[part 1 of 2: packages /Systems to /BMW/Boardnet/Clusters/CommunicationClusters]
AUTOSAR XML (schema 4-3-0)
package /Systems
  system EPS: category=ECU_SYSTEM_DESCRIPTION, pnc-vector-length=6, pnc-vector-offset=2, system-version=0.0.1
package /Systems/EndToEndProtections
  end to end protection set EndToEndProtectionSet
    18 x end to end protection:
      endToEndProt_ACLNY_MASSCNTR: end-to-end-profile={category=PROFILE_01, data-ids=31, data-id-mode=0, data-length=48, max-delta-counter-init=14, crc-offset=0, counter-offset=8}, end-to-end-protection-i-signal-i-pdu{data-offset=0, i-signal-group=sigGroup_ACLNY_MASSCNTR, i-signal-i-pdu=ACLNY_MASSCNTR}
      endToEndProt_AVL_FORC_GRD: end-to-end-profile={category=PROFILE_01, data-ids=190, data-id-mode=0, data-length=40, max-delta-counter-init=14, crc-offset=0, counter-offset=8}, end-to-end-protection-i-signal-i-pdu{data-offset=0, i-signal-group=sigGroup_AVL_FORC_GRD, i-signal-i-pdu=AVL_FORC_GRD}
      endToEndProt_AVL_PO_EPS: end-to-end-profile={category=PROFILE_01, data-ids=186, data-id-mode=0, data-length=64, max-delta-counter-init=14, crc-offset=0, counter-offset=8}, end-to-end-protection-i-signal-i-pdu{data-offset=0, i-signal-group=sigGroup_AVL_PO_EPS, i-signal-i-pdu=AVL_PO_EPS}
      endToEndProt_AVL_RPM_WHL: end-to-end-profile={category=PROFILE_01, data-ids=17, data-id-mode=0, data-length=96, max-delta-counter-init=14, crc-offset=0, counter-offset=8}, end-to-end-protection-i-signal-i-pdu{data-offset=0, i-signal-group=sigGroup_AVL_RPM_WHL, i-signal-i-pdu=AVL_RPM_WHL}
      endToEndProt_AVL_STMOM_DV_ACT: end-to-end-profile={category=PROFILE_01, data-ids=108, data-id-mode=0, data-length=32, max-delta-counter-init=14, crc-offset=0, counter-offset=8}, end-to-end-protection-i-signal-i-pdu{data-offset=0, i-signal-group=sigGroup_AVL_STMOM_DV_ACT, i-signal-i-pdu=AVL_STMOM_DV_ACT}
      endToEndProt_CON_VEH: end-to-end-profile={category=PROFILE_01, data-ids=197, data-id-mode=0, data-length=64, max-delta-counter-init=14, crc-offset=0, counter-offset=8}, end-to-end-protection-i-signal-i-pdu{data-offset=0, i-signal-group=sigGroup_CON_VEH, i-signal-i-pdu=CON_VEH}
      endToEndProt_DISP_CC_EPS: end-to-end-profile={category=PROFILE_01, data-ids=3148, data-id-mode=3, data-length=40, max-delta-counter-init=14, crc-offset=0, counter-offset=8, data-id-nibble-offset=12}, end-to-end-protection-i-signal-i-pdu{data-offset=0, i-signal-group=sigGroup_DISP_CC_EPS, i-signal-i-pdu=DISP_CC_EPS}
      endToEndProt_DT_EST: end-to-end-profile={category=PROFILE_01, data-ids=230, data-id-mode=0, data-length=128, max-delta-counter-init=14, crc-offset=0, counter-offset=8}, end-to-end-protection-i-signal-i-pdu{data-offset=0, i-signal-group=sigGroup_DT_EST, i-signal-i-pdu=DT_EST}
      endToEndProt_ENERG_DGR_DRDY: end-to-end-profile={category=PROFILE_01, data-ids=56, data-id-mode=0, data-length=64, max-delta-counter-init=14, crc-offset=56, counter-offset=52}, end-to-end-protection-i-signal-i-pdu{data-offset=0, i-signal-group=sigGroup_ENERG_DGR_DRDY, i-signal-i-pdu=ENERG_DGR_DRDY}
      endToEndProt_ENSU_SFY: end-to-end-profile={category=PROFILE_01, data-ids=628, data-id-mode=3, data-length=64, max-delta-counter-init=14, crc-offset=0, counter-offset=8, data-id-nibble-offset=12}, end-to-end-protection-i-signal-i-pdu{data-offset=0, i-signal-group=sigGroup_ENSU_SFY, i-signal-i-pdu=ENSU_SFY}
      endToEndProt_OFFS_QUAD_EPS: end-to-end-profile={category=PROFILE_01, data-ids=229, data-id-mode=0, data-length=40, max-delta-counter-init=14, crc-offset=0, counter-offset=8}, end-to-end-protection-i-signal-i-pdu{data-offset=0, i-signal-group=sigGroup_OFFS_QUAD_EPS, i-signal-i-pdu=OFFS_QUAD_EPS}
      endToEndProt_ST_EST: end-to-end-profile={category=PROFILE_01, data-ids=112, data-id-mode=0, data-length=40, max-delta-counter-init=14, crc-offset=0, counter-offset=8}, end-to-end-protection-i-signal-i-pdu{data-offset=0, i-signal-group=sigGroup_ST_EST, i-signal-i-pdu=ST_EST}
      endToEndProt_SU_EPS: end-to-end-profile={category=PROFILE_01, data-ids=131, data-id-mode=0, data-length=64, max-delta-counter-init=14, crc-offset=56, counter-offset=52}, end-to-end-protection-i-signal-i-pdu{data-offset=0, i-signal-group=sigGroup_SU_EPS, i-signal-i-pdu=SU_EPS}
      endToEndProt_TAR_ESTP_VIRT_FTAX: end-to-end-profile={category=PROFILE_01, data-ids=52, data-id-mode=0, data-length=64, max-delta-counter-init=14, crc-offset=0, counter-offset=8}, end-to-end-protection-i-signal-i-pdu{data-offset=0, i-signal-group=sigGroup_TAR_ESTP_VIRT_FTAX, i-signal-i-pdu=TAR_ESTP_VIRT_FTAX}
      endToEndProt_TAR_QTA_STRMOM_DV: end-to-end-profile={category=PROFILE_01, data-ids=109, data-id-mode=0, data-length=64, max-delta-counter-init=14, crc-offset=0, counter-offset=8}, end-to-end-protection-i-signal-i-pdu{data-offset=0, i-signal-group=sigGroup_TAR_QTA_STRMOM_DV, i-signal-i-pdu=TAR_QTA_STRMOM_DV}
      endToEndProt_TAR_STMOM_DV_ACT: end-to-end-profile={category=PROFILE_01, data-ids=179, data-id-mode=0, data-length=64, max-delta-counter-init=14, crc-offset=0, counter-offset=8}, end-to-end-protection-i-signal-i-pdu{data-offset=0, i-signal-group=sigGroup_TAR_STMOM_DV_ACT, i-signal-i-pdu=TAR_STMOM_DV_ACT}
      endToEndProt_VYAW_VEH: end-to-end-profile={category=PROFILE_01, data-ids=14, data-id-mode=0, data-length=48, max-delta-counter-init=14, crc-offset=0, counter-offset=8}, end-to-end-protection-i-signal-i-pdu{data-offset=0, i-signal-group=sigGroup_VYAW_VEH, i-signal-i-pdu=VYAW_VEH}
      endToEndProt_V_VEH: end-to-end-profile={category=PROFILE_01, data-ids=12, data-id-mode=0, data-length=40, max-delta-counter-init=14, crc-offset=0, counter-offset=8}, end-to-end-protection-i-signal-i-pdu{data-offset=0, i-signal-group=sigGroup_V_VEH, i-signal-i-pdu=V_VEH}
package /BMW/Boardnet/Clusters/CommunicationClusters
  flexray cluster A_FlexRay:
    baudrate=10000000
    protocol-name=FlexRay
    action-point-offset=2
    bit=1E-7
    cas-rx-low-max=79
    cold-start-attempts=8
    cycle=0.005
    cycle-count-max=63
    detect-nit-error=false
    dynamic-slot-idle-phase=1
    ignore-after-tx=0
    listen-noise=2
    macro-per-cycle=3636
    macrotick-duration=0.000001375
    max-without-clock-correction-fatal=2
    max-without-clock-correction-passive=2
    minislot-action-point-offset=2
    minislot-duration=5
    network-idle-time=7
    network-management-vector-length=0
    number-of-minislots=289
    number-of-static-slots=91
    offset-correction-start=3632
    payload-length-static=8
    safety-margin=100
    sample-clock-period=1.25E-8
    static-slot-duration=24
    symbol-window=0
    symbol-window-action-point-offset=2
    sync-frame-id-count-max=15
    transmission-start-sequence-duration=9
    wakeup-rx-idle=59
    wakeup-rx-low=50
    wakeup-rx-window=301
    wakeup-tx-active=60
    wakeup-tx-idle=180
    flexray physical channel A_FlexRay: comm-connectors=con_EPS_FibexID_0b7e5e09c061465d913e8968ece3cded, channel-name=CHANNEL-A  # A-FlexRay
      frame xcpstatic: from EPS, category=XCP_RUNTIME_CONFIGURED, frame-length=16, flexray-absolutely-scheduled-timing{communication-cycle=cycle-repetition={base-cycle=0, cycle-repetition=CYCLE-REPETITION-1}, slot-id=10}, allow-dynamic-l-sdu-length=false, payload-preamble-indicator=false  # XCP Bereich Statisch / XCP Frame Static | Dieser Frame dient als Platzhalter für die XCP-Konfiguration für FlexRay (s. LH FlexRay) und zur Pufferkonfiguration der FlexRay-Controller. Der statische XCP-Bereich wird auch durch das Projekt "Funktionstrace" mitbenutzt. Ansprechpartner ist Florian Kuttig oder Christian Pigorsch. / Dummyframe für Infrastruktur XCP
        general purpose i pdu dummy16bstatic: category=XCP, length=16  # Dummy-PDU 16 Byte static | Dummy-PDU ohne inhaltliche Verbindlichkeit mit 16 Byte für Infrastruktur (z.B. XCP).
      frame ERRM_BN_U: to EPS, category=APPLICATION, frame-length=2, flexray-absolutely-scheduled-timing{communication-cycle=cycle-repetition={base-cycle=0, cycle-repetition=CYCLE-REPETITION-1}, slot-id=104}, allow-dynamic-l-sdu-length=false, payload-preamble-indicator=false  # Fehlerspeicher Bordnetz Spannung
        pdu ERRM_BN_U: length=2, minimum-delay=0.01, transmission-mode-true-timing={cyclic-timing=time-period={tolerance=absolute-tolerance=1, value=5}, event-controlled-timing={number-of-repetitions=0, "Die Nachricht wird bei einer beliebigen Änderung des Signals "Steuerung Fehlerspeicher Bordnetzspannung" ereignisgesteuert versendet."}}, unused-bit-pattern=255  # Fehlerspeicher Bordnetz Spannung | Diese Botschaft beinhaltet das Signal Steuerung Fehlerspeicher Bordnetzspannung mit dem Ziel der Bereitstellung von Spannungsschwellen für das Fehlerspeicherhandling. Diese Botschaft wird von einigen Versionen der DME nicht verschickt. Es darf daher auf Empfängerseite keine Timeout-Fehlerspeichereinträge dazu geben. Die Empfänger müssen bei Timeout dieser Botschaft eine interne Ersatzwertbildung vornehmen.
          signal CTR_ERRM_BN_U: start 0, 6 bit, little-endian, base-type=uint8, invalid-value=value_63Dot0:63, compu-method=CTR_ERRM_BN_U, transfer-property=TRIGGERED-ON-CHANGE, to EPS  # Steuerung_Fehlerspeicher_Bordnetz_Spannung / control_error-memory_Bordnetz_voltage | LogicalInterface:BMW.INFRASTRUCTURE.LOWVOLTAGE.EnergyManagementConsumer[internal]@Infrastruktur; Das Signal Steuerung_Fehlerspeicher_Bordnetz_Spannung stellt Spannungsschwellen für das Fehlerspeicherhandling zur Verfügung.
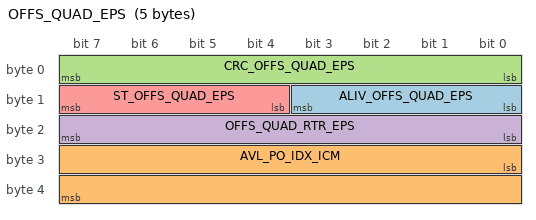
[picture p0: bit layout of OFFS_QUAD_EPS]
      frame OFFS_QUAD_EPS: to EPS, category=APPLICATION, frame-length=5, flexray-absolutely-scheduled-timing{communication-cycle=cycle-repetition={base-cycle=0, cycle-repetition=CYCLE-REPETITION-1}, slot-id=107}, allow-dynamic-l-sdu-length=false, payload-preamble-indicator=false  # Offset Quadrant EPS
        pdu OFFS_QUAD_EPS: length=5, minimum-delay=0.01, transmission-mode-true-timing={cyclic-timing=time-period={tolerance=absolute-tolerance=0.2, value=1}, event-controlled-timing={number-of-repetitions=1, repetition-period=0.01, "$(ET;2;10) Wird bei Änderung des Signals ST_OFFS_QUAD_EPS 2-malig mit einem Wiederholzyklus von t = 10 ms versendet."}}, unused-bit-pattern=255  # Offset Quadrant EPS | Mittels Aufsetzalgorithmus ermittelter Offset des aktuellen Nullpunktes der EPS-Position (entspricht der Segmentmitte des Segments in dem sich der EPS-Rotor z.B. nach dem letzten Einbruch der Spannungsversorgung befand) zum absoluten Nullpunkt (Segmentmitte des Segments bei Geradeausfahrt). Die Nachricht wird beim Zustandswechsel vom ST_OFFS_QUAD_EPS sofort gesendet (ereignisgesteuert). Um sicher zu stellen dass die EPS die Daten empfängt, wird die Nachricht 2-malig gesendet mit einer Wiederholrate von 10ms. Dabei ist zu beachten, dass der funktionale Inhalt der Botschaft (gilt nicht für CRC und Alive) bei der Wiederholung identisch bleiben wird. Ausnahme: In DSC_2013 (MCV) und DSC_Modul (444, UKL) weicht der Implementierungsstand bzgl. der wiederholten Versendung von der hier definierten Spezifikation ab. Details sind im jeweiligen Projekt dokumentiert.
          signal ALIV_OFFS_QUAD_EPS: start 8, 4 bit, little-endian, base-type=uint8, invalid-value=value_15Dot0:15, compu-method=ALIV_COU_4, transfer-property=TRIGGERED-ON-CHANGE, to EPS  # Alive_Offset_Quadrant_EPS / alive_offset_quadrant_EPS | LogicalInterface:BMW.CHASSIS.STEERING.ElectricPowerSteering[internal]@Fahren;
          signal AVL_PO_IDX_ICM: start 24, 16 bit, little-endian, base-type=uint16, invalid-value=value_65535Dot0:65535, compu-method=AVL_PINA_IDX_ICM, data-constr=AVL_PINA_IDX_ICM, transfer-property=TRIGGERED-ON-CHANGE, to EPS  # Ist_Position_Index_ICM / actual-value_position_index_ICM | LogicalInterface:BMW.CHASSIS.STEERING.ElectricPowerSteering[internal]@Fahren; Rücksenden des von der EPS übertragenen Wertes von Ist_Position_Index_EPS, sofern mit Hilfe des Index-Signals aufgesetzt werden konnte. Dies soll bei einem weiteren Rotorsegmentwechsel, zwischen dem Empfang einer Indexflanke und Zurücksenden des vom Aufsetzalgorithmus ermittelten Offsetwertes, ermöglichen, diesen auf Seiten der EPS berücksichtigen und korrigieren zu können. Das Signal wird ohne Einheit übertragen. Die Einheit kann aus dem Signal "Einheit_Position_EPS" entnommen werden aus der Nachricht "Ist Position EPS": - Im F25/L7 ist das Signal als Zahnstangenhub zu interpretieren. Die Einheit ist somit 0.2mm. Hinweis: Aufgrund der derzeitigen bei der Nachrichtenkataloggenerierung durch die IT bedingte Rundung von Nachkommastellen, werden die Offset- und Quantisierungswerte nicht korrekt wieder gegeben. Folgende Angaben entsprechen den exakten Werten: Offset = -1439,9560546875 Quantisierung = 0,0439453125
          signal CRC_OFFS_QUAD_EPS: start 0, 8 bit, little-endian, base-type=uint8, compu-method=CRC8, data-constr=CRC8, transfer-property=TRIGGERED-ON-CHANGE, to EPS  # CRC_Offset_Quadrant_EPS / CRC_offset_quadrant_EPS | LogicalInterface:BMW.CHASSIS.STEERING.ElectricPowerSteering[internal]@Fahren; Standardabsicherung Applikations-CRC Dieses Signal verwendet die Applikations-CRC-ID = 229 (Dez)
          signal OFFS_QUAD_RTR_EPS: start 16, 8 bit, little-endian, base-type=uint8, invalid-value=value_255Dot0:255, compu-method=OFFS_QUAD_PINA_EPS, data-constr=OFFS_QUAD_PINA_EPS, transfer-property=TRIGGERED-ON-CHANGE, to EPS  # Offset_Quadrant_Rotor_EPS / offset_quadrant_rotor_EPS | LogicalInterface:BMW.CHASSIS.STEERING.ElectricPowerSteering[internal]@Fahren; Mittels Aufsetzalgorithmus ermittelter Offset des aktuellen Nullpunktes der EPS-Position (entspricht der Segmentmitte des Segments in dem sich der EPS-Rotor z.B. nach dem letzten Einbruch der Spannungsversorgung befand) zum absoluten Nullpunkt (Segmentmitte des Segments bei Geradeausfahrt). Der Offset wird angegeben als Anzahl voller Umdrehungen des EPS-Rotors (entspr. Anzahl Segmente).
          signal ST_OFFS_QUAD_EPS: start 12, 4 bit, little-endian, base-type=uint8, invalid-value=value_15Dot0:15, compu-method=ST_OFFS_QUAD_PINA_EPS, transfer-property=TRIGGERED-ON-CHANGE, to EPS  # Status_Offset_Quadrant_EPS / status_offset_quadrant_EPS | LogicalInterface:BMW.CHASSIS.STEERING.ElectricPowerSteering[internal]@Fahren; Mit dem Statuswert wird dem EPS-Steuergerät signalisiert, dass ein Offsetwert mithilfe des Aufsetzalgorithmus bestimmt werden konnte und zu übernehmen ist (= Offset übernehmen) bzw. dass der von der EPS aktuell verrechnete Offsetwert falsch ist und um den mitgelieferten Wert korrigiert werden muss (= Offset korrigieren). Ansonsten wird der Offset gerade ermittelt oder sofern dies bereits geschehen ist plausibilisiert und auf Richtigkeit überprüft (=Offset in Prüfung).
          mapping sigGroup_OFFS_QUAD_EPS: i-signal-group=sigGroup_OFFS_QUAD_EPS
      frame STEA_OFFS: to EPS, category=APPLICATION, frame-length=8, flexray-absolutely-scheduled-timing{communication-cycle=cycle-repetition={base-cycle=0, cycle-repetition=CYCLE-REPETITION-2}, slot-id=108}, allow-dynamic-l-sdu-length=false, payload-preamble-indicator=false  # Lenkwinkel Offset
        pdu STEA_OFFS: length=8, transmission-mode-true-timing=cyclic-timing=time-period={tolerance=absolute-tolerance=0.02, value=0.1}, unused-bit-pattern=255  # Lenkwinkel Offset | Offsetwerte zu den verschiedenen Lenkwinkeln. Die Werte werden mittels Langzeitabgleich gebildet.
          signal AVL_STEA_PNI_OFFS: start 36, 12 bit, little-endian, base-type=uint16, invalid-value=value_4095Dot0:4095, compu-method=AVL_STEA_PNI_OFFS, data-constr=AVL_STEA_PNI_OFFS, to EPS  # Ist_Lenkwinkel_Ritzel_Offset / actual-value_steering-angle_pinion_offset | LogicalInterface:BMW.CHASSIS.STEERING.ElectricPowerSteering[internal]@Fahren; Das Signal wird ohne Einheit übertragen. Die Einheit kann aus dem Signal "Einheit_Position_EPS" entnommen werden: - Signal kann als Ritzelwinkel interpretiert werden. Die Einheit ist Grad - Signal kann als Zahnstangenhub interpretiert werden. Die Einheit ist somit 0.2mm
      frame xcpstatic: from EPS, category=XCP_RUNTIME_CONFIGURED, frame-length=16, flexray-absolutely-scheduled-timing{communication-cycle=cycle-repetition={base-cycle=0, cycle-repetition=CYCLE-REPETITION-1}, slot-id=11}, allow-dynamic-l-sdu-length=false, payload-preamble-indicator=false  # XCP Bereich Statisch / XCP Frame Static | Dieser Frame dient als Platzhalter für die XCP-Konfiguration für FlexRay (s. LH FlexRay) und zur Pufferkonfiguration der FlexRay-Controller. Der statische XCP-Bereich wird auch durch das Projekt "Funktionstrace" mitbenutzt. Ansprechpartner ist Florian Kuttig oder Christian Pigorsch. / Dummyframe für Infrastruktur XCP
        carries pdu dummy16bstatic: packing-byte-order=little-endian, start-position=0
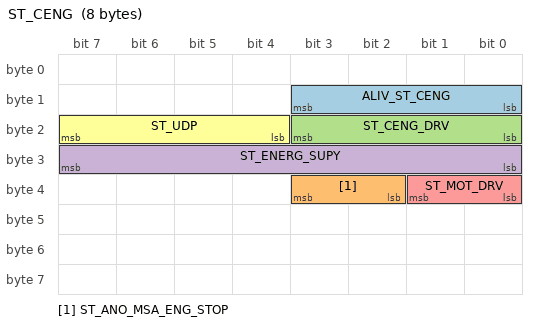
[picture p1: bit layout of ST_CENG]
      frame ST_CENG: to EPS, category=APPLICATION, frame-length=8, flexray-absolutely-scheduled-timing{communication-cycle=cycle-repetition={base-cycle=0, cycle-repetition=CYCLE-REPETITION-2}, slot-id=117}, allow-dynamic-l-sdu-length=false, payload-preamble-indicator=false  # Status Verbrennungsmotor
        pdu ST_CENG: length=8, minimum-delay=0.01, transmission-mode-true-timing={cyclic-timing=time-period={tolerance=absolute-tolerance=0.7, value=1}, event-controlled-timing=number-of-repetitions=0}, unused-bit-pattern=255  # Status Verbrennungsmotor
          signal ALIV_ST_CENG: start 8, 4 bit, little-endian, base-type=uint8, invalid-value=value_15Dot0:15, compu-method=ALIV_4_BIT_UInt, data-constr=ALIV_4_BIT_UInt, transfer-property=TRIGGERED-ON-CHANGE, to EPS  # Alive_Status_Verbrennungsmotor / alive_status_combustion-engine | LogicalInterface:BMW.POWERTRAIN.ENGINE.DrivingReadinessEngineStart[internal]@Fahren; Standardabsicherung Alivezähler laut Definition per Lastenheft Allgemeine Bordnetzkommunikation
          signal ST_ANO_MSA_ENG_STOP: start 34, 2 bit, little-endian, base-type=uint8, invalid-value=value_3Dot0:3, compu-method=ST_ANO_MSA_ENG_STOP, transfer-property=TRIGGERED-ON-CHANGE, to EPS  # Status_Ankündigung_MSA_Motor_Stop / status_announcement_MSA_engine_stop | LogicalInterface:BMW.POWERTRAIN.ENGINE.DrivingReadinessEngineStart[external]@Fahren; In diesem Signal wird die Ankündigung des MSA-Motorstops kommuniziert.
          signal ST_CENG_DRV: start 16, 4 bit, little-endian, base-type=uint8, invalid-value=value_15Dot0:15, compu-method=ST_CENG_DRV, transfer-property=TRIGGERED-ON-CHANGE, to EPS  # Status_Verbrennungsmotor_Antrieb / status_combustion-engine_drive | LogicalInterface:BMW.POWERTRAIN.ENGINE.DrivingReadinessEngineStart[external]@Fahren; In diesem Signal wird der Zusand des Antriebsverbrennungsmotors angegeben. Dieser Zustand gilt nicht für den REX-Verbrennungsmotors Motorzustand lässt keinen Rückschluss auf Kurbelwellendrehzahl zu. Aus der Reihenfolge der Codierung kann nicht auf gültige Zustandswechsel geschlossen werden.
          signal ST_ENERG_SUPY: start 24, 8 bit, little-endian, base-type=uint8, invalid-value=value_255Dot0:255, compu-method=ST_ENERG_SUPY, transfer-property=TRIGGERED-ON-CHANGE, to EPS  # Status_Energie_Versorgung / status_Energy_supply | LogicalInterface:BMW.POWERTRAIN.ENGINE.DrivingReadinessEngineStart[external]@Fahren; Im diesem Signal wird angegeben welcher Energieversorgungszweig vom Spannungseinbruch im Signal Status_Spannungseinbruch betroffen ist. Die betroffenen Steuergeräte am jeweiligen Versorgungszweig können dadurch gezielt Maßnahmen für die Unterspannung ergreifen. Ist Status_Spannungseinbruch gleich 1101 (Schnittstelle ist nicht verfügbar) wird in diesem Signal 0000 0000b (Kein Spannungseinbruch) ausgegeben.
          signal ST_MOT_DRV: start 32, 2 bit, little-endian, base-type=uint8, invalid-value=value_3Dot0:3, compu-method=ST_MOT_DRV, transfer-property=TRIGGERED-ON-CHANGE, to EPS  # Status_E-Motor_Antrieb / status_motor_drive | LogicalInterface:BMW.POWERTRAIN.ENGINE.DrivingReadinessEngineStart[external]@Fahren; In diesem Signal wird der Zustand des Elektromotors angegeben. Status der Traktions-E-Maschine(n) lässt keinen Rückschluss auf die Hochvoltverfügbarkeit zu.
          signal ST_UDP: start 20, 4 bit, little-endian, base-type=uint8, invalid-value=value_15Dot0:15, compu-method=ST_UDP, transfer-property=TRIGGERED-ON-CHANGE, to EPS  # Status_Spannungseinbruch / status_voltage-drop | LogicalInterface:BMW.POWERTRAIN.ENGINE.DrivingReadinessEngineStart[external]@Fahren; In diesem Signal wird der Startspannungseinbruch vor dem Start angekündigt (mindestens 70 ms vor dem Startspannungseinbruch) und behält den Zustand während des Startvorgangs bei. Die Entscheidung für einen Einbruch bis Spannungsschwelle 1 (Warmstart) bzw. Spannungsschwelle 2 (Kaltstart) wird anhand einer applizierbaren Motortemperaturschwelle getroffen. Der applizierte Wert entspricht der Temperaturschwelle von MSA. Codierung 0001 "Startspannungseinbruch bis maximal Spannungsschwelle 1" wird nur gesetzt, wenn zusätzlich kein MSA-Abschaltverhinderer durch SOC/SOH gesetzt ist. Der Spannungseinbruch basiert auf Temperaturabschätzung. Wird ein Einbruch auf Schwelle 1 oder 2 angekündigt, so erfolgt während des Starts bei geänderter Temperatur kein Wechsel auf die dann gültige Schwelle.
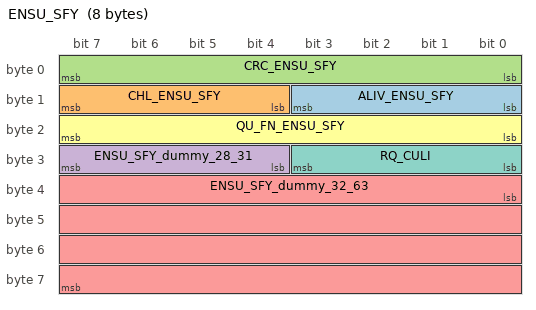
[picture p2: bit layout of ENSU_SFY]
      frame ENSU_SFY: to EPS, category=APPLICATION, frame-length=8, flexray-absolutely-scheduled-timing{communication-cycle=cycle-repetition={base-cycle=1, cycle-repetition=CYCLE-REPETITION-2}, slot-id=119}, allow-dynamic-l-sdu-length=false, payload-preamble-indicator=false  # Energieversorgung Sicherheit
        pdu ENSU_SFY: length=8, transmission-mode-true-timing=cyclic-timing=time-period={tolerance=absolute-tolerance=0.002, value=0.01}, unused-bit-pattern=255  # Energieversorgung Sicherheit | Die PDU enthält Informationen über den aktuellen Zustand der sicheren Energieversorgung sowie Kommandos um einen bestimmten Zustand der sicheren Energieversorgung einzustellen.
          signal ALIV_ENSU_SFY: start 8, 4 bit, little-endian, base-type=uint8, invalid-value=value_15Dot0:15, compu-method=ALIV_4_BIT_Unsigned_Integer, data-constr=ALIV_4_BIT_Unsigned_Integer, to EPS  # Alive_Energieversorgung_Sicherheit / alive_energy-supply_safety | LogicalInterface:BMW.INFRASTRUCTURE.LOWVOLTAGE.EnergySupplySafe[internal]@Infrastruktur; Standardabsicherung Alivezähler laut Definition per Lastenheft Allgemeine Bordnetzkommunikation.
          signal CHL_ENSU_SFY: start 12, 4 bit, little-endian, base-type=uint8, invalid-value=value_15Dot0:15, compu-method=CHL_4_UInt, data-constr=CHL_4_UInt, to EPS  # CHL_Energieversorgung_Sicherheit / CHL_energy-supply_safety | LogicalInterface:BMW.INFRASTRUCTURE.LOWVOLTAGE.EnergySupplySafe[internal]@Infrastruktur; Dieses Signal beinhaltet explizit den Wert der Erweiterungs-ID = 2 (dez) = 2 (hex) für den erweiterten Standardabsicherungs-Applikations-CRC und entspricht Bit 12-15 der Applikations-Data-ID (CRC-ID) des zughörigen CRC-Signals. Dieses Signal liegt im Bereich der für die Berechnung des CRC-Signales verwendet wird und muss empfängerseitig im Rahmen der CRC-Prüfung auf korrekte Befüllung geprüft werden. Nur wenn der Wert des Signales dem Sollwert entspricht ist und die Überprüfung des CRC-Signals positiv verläuft kann davon ausgegangen werden, dass die erwartete PDU fehlerfrei empfangen wurde. Das Signal kann den Wert 0 nicht annehmen um eine klare Differenzierung der 1A E2E-Protection (Autosar SWS 428) Anwendungsprofile 1A und 1C zu ermöglichen.
          signal CRC_ENSU_SFY: start 0, 8 bit, little-endian, base-type=uint8, compu-method=CRC8, data-constr=CRC8, to EPS  # CRC_Energieversorgung_Sicherheit / CRC_energy-supply_safety | LogicalInterface:BMW.INFRASTRUCTURE.LOWVOLTAGE.EnergySupplySafe[internal]@Infrastruktur; Dieses Signal beinhaltet die CRC-Checksumme für die erweiterte Standardabsicherung mit Applikations-CRC nach Anwendungsprofil 1C E2E-Protection (Autosar SWS 428). Das Signal verwendet die Applikations-Data-ID (12 Bit) 628 (dez) = 274 (hex). Die Applikations-CRC-ID besteht aus zwei Teilen: 1.) Bit 0-7: 116 (dez) = 74 (hex). Dieser Wert wird nur als Startwert für die CRC8-Berechnung verwendet. (Vergleiche Anwendungsprofil 1A E2E-Protection (Autosar SWS 428)) 2.) Bit 8-11: 2 (dez) = 2 (hex). Dieser Wert wird NICHT für die CRC8-Berechnung verwendet sondern als explizit übertragene Erweiterungs-ID zur Unterscheidung der CRC-abgesicherten PDUs. Dieser Teil der Applikations-Data-ID geht also nicht in das CRC-Signal ein sondern wird im Wert des zugehörigen CHL-Signales abgebildet. Die Bits 8-11 der Appliktions-Data-ID entsprechen somit den Bits 12-15 der PDU.
          signal ENSU_SFY_dummy_28_31: start 28, 4 bit, little-endian, init-value=15, base-type=uint8, compu-method=UINT4, data-constr=UINT4, to EPS
          signal ENSU_SFY_dummy_32_63: start 32, 32 bit, little-endian, init-value=4294967295, base-type=uint32, compu-method=UINT32, data-constr=UINT32, to EPS
          signal QU_FN_ENSU_SFY: start 16, 8 bit, little-endian, base-type=uint8, invalid-value=value_255Dot0:255, compu-method=QU_FN_ENSU_SFY, to EPS  # Qualifier_Funktion_Energieversorgung_Sicherheit / Qualifier_function_energy-supply_safety | LogicalInterface:BMW.INFRASTRUCTURE.LOWVOLTAGE.EnergySupplySafe[internal]@Infrastruktur; Funktions-Qualifier zur sicheren Energieversorgung.
          signal RQ_CULI: start 24, 4 bit, little-endian, base-type=uint8, invalid-value=value_15Dot0:15, compu-method=RQ_CULI, to EPS  # Anforderung_Strombegrenzung / request_current-limitation | LogicalInterface:BMW.INFRASTRUCTURE.LOWVOLTAGE.EnergySupplySafe[internal]@Infrastruktur; Das Signal kommandiert einen bestimmten Grad der Leistungseinschränkung an die Empfänger. Diese Leistungseinschränkung ist jeweils vereinbart und umfasst typischerweise einen maximalen Stromverbrauch, einen maximalen Stromgradienten und eine Integrität nach ASIL.
          mapping sigGroup_ENSU_SFY: i-signal-group=sigGroup_ENSU_SFY
      frame xcpstatic: from EPS, category=XCP_RUNTIME_CONFIGURED, frame-length=16, flexray-absolutely-scheduled-timing{communication-cycle=cycle-repetition={base-cycle=0, cycle-repetition=CYCLE-REPETITION-1}, slot-id=12}, allow-dynamic-l-sdu-length=false, payload-preamble-indicator=false  # XCP Bereich Statisch / XCP Frame Static | Dieser Frame dient als Platzhalter für die XCP-Konfiguration für FlexRay (s. LH FlexRay) und zur Pufferkonfiguration der FlexRay-Controller. Der statische XCP-Bereich wird auch durch das Projekt "Funktionstrace" mitbenutzt. Ansprechpartner ist Florian Kuttig oder Christian Pigorsch. / Dummyframe für Infrastruktur XCP
        carries pdu dummy16bstatic: packing-byte-order=little-endian, start-position=0
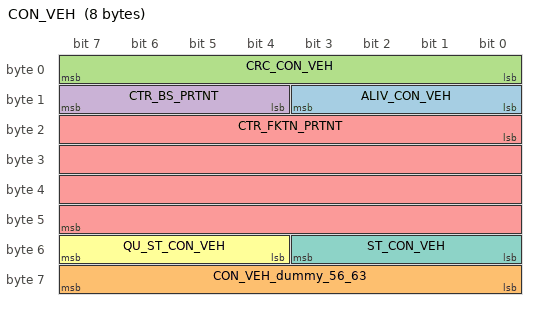
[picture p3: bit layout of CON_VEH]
      frame CON_VEH: to EPS, category=APPLICATION, frame-length=8, flexray-absolutely-scheduled-timing{communication-cycle=cycle-repetition={base-cycle=1, cycle-repetition=CYCLE-REPETITION-2}, slot-id=121}, allow-dynamic-l-sdu-length=false, payload-preamble-indicator=false  # Zustand Fahrzeug
        pdu CON_VEH: length=8, minimum-delay=0.02, transmission-mode-true-timing={cyclic-timing=time-period={tolerance=absolute-tolerance=0.02, value=0.1}, event-controlled-timing={number-of-repetitions=7, repetition-period=0.05, "$(ET;8;50) Die Nachricht wird bei Signalchance 8x mit einer Zykluszeit 50ms +- 10ms versendet"}}, unused-bit-pattern=255  # Zustand Fahrzeug | Diese Nachricht überträgt den Status (aktiv oder inaktiv) der Teilnetze. Ab SP 2015: Diese Nachricht enthält alle Signale, die zur Steuerung von Fahrzeugzuständen und Teilnetzen notwendig sind und wird mit CRC und Alive abgesichert.
          signal ALIV_CON_VEH: start 8, 4 bit, little-endian, base-type=uint8, invalid-value=value_15Dot0:15, compu-method=ALIV_4_BIT_Unsigned_Integer, data-constr=ALIV_4_BIT_Unsigned_Integer, transfer-property=TRIGGERED-ON-CHANGE, to EPS  # Alive_Zustand_Fahrzeug / alive_condition_vehicle | LogicalInterface:BMW.INFRASTRUCTURE.VEHICLE.VehicleCondition[external]@Infrastruktur; Standardabsicherung Alivezähler laut Definition per Lastenheft Allgemeine Bordnetzkommunikation.
          signal CON_VEH_dummy_56_63: start 56, 8 bit, little-endian, init-value=255, base-type=uint8, compu-method=UINT8, data-constr=UINT8, transfer-property=PENDING, to EPS
          signal CRC_CON_VEH: start 0, 8 bit, little-endian, base-type=uint8, compu-method=CRC8, data-constr=CRC8, transfer-property=TRIGGERED-ON-CHANGE, to EPS  # CRC_Zustand_Fahrzeug / CRC_condition_vehicle | LogicalInterface:BMW.INFRASTRUCTURE.VEHICLE.VehicleCondition[external]@Infrastruktur; Standardabsicherung Applikations-CRC laut Definition per Lastenheft Allgemeine Bordnetzkommunikation. Dieses Signal verwendet die Applikations-CRC-ID = 197 (Dez).
          signal CTR_BS_PRTNT: start 12, 4 bit, little-endian, base-type=uint8, invalid-value=value_15Dot0:15, compu-method=CTR_BS_PRTNT, transfer-property=TRIGGERED-ON-CHANGE, to EPS  # Steuerung_Basis_Teilnetze / control_base_partial-networks | LogicalInterface:BMW.INFRASTRUCTURE.VEHICLE.VehicleCondition[external]@Infrastruktur; Dieses Signal gibt an, ob im aktuellen Fahrzeugzustand Kommunikation benötigt wird. Über dieses Signal wird mitgeteilt, ob im aktuell aktiven Fahrzeugzustand ("Parken, Wohnen, Fahren", s. Signal ST_CON_VEH) Kommunikation benötigt wird. Dieses Signal definiert dadurch ein sogenanntes Basisteilnetz. Es dient dazu, festzulegen, welche Signale und Nachrichten im jeweiligen Basisteilnetz verfügbar sind. Der Teilnetzdomänenmaster (s. LH Teilnetzbetrieb Domänenmaster und Slave, 100003564) empfängt dieses Signal und befüllt aufgrund des Signalinhalts seine Netzwerkmanagement-Nachricht (Signal CTR_BS_PRTNT_NM). Über diese werden dann die Komponenten gesteuert, die das AUTOSAR Netzwerkmanagement unterstützen. Andere Komponenten (beispielsweise Komponenten an Klemme 15N oder MOST-Teilnehmer) werten dieses Signal selbst aus und steuern damit ihre Kommunikation.
          signal CTR_FKTN_PRTNT: start 16, 32 bit, little-endian, base-type=uint32, invalid-value=value_4Dot294967295E9:4294967295, compu-method=FKTN_PRTNT, transfer-property=TRIGGERED-ON-CHANGE, to EPS  # Steuerung_Funktionale_Teilnetze / control_functional_partial-networks | LogicalInterface:BMW.INFRASTRUCTURE.VEHICLE.VehicleCondition[external]@Infrastruktur; Dieses Signal gibt an, welche funktionalen Teilnetze aktiv sind. Über dieses Signal wird mitgeteilt, welche funktionalen Teilnetze (z.B. "Entertainment", "Laden") aktiv sind. Es dient dazu, festzulegen, welche Signale und Nachrichten im jeweiligen funktionalen Teilnetz verfügbar sind. Der Teilnetzdomänenmaster (s. LH Teilnetzbetrieb Domänenmaster und Slave, 100003564) empfängt dieses Signal und befüllt aufgrund des Signalinhalts seine Netzwerkmanagement-Nachricht (Signal CTR_FKTN_PRTNT_NM). Über diese werden dann die Komponenten gesteuert, die das AUTOSAR Netzwerkmanagement unterstützen. Andere Komponenten (beispielsweise Komponenten an Klemme 15N oder MOST-Teilnehmer) werten dieses Signal selbst aus und steuern damit ihre Kommunikation.
          signal QU_ST_CON_VEH: start 52, 4 bit, little-endian, base-type=uint8, invalid-value=value_15Dot0:15, compu-method=QU_ST_CON_VEH, transfer-property=TRIGGERED-ON-CHANGE, to EPS  # Qualifier_Status_Zustand_Fahrzeug / Qualifier_status_condition_vehicle | LogicalInterface:BMW.INFRASTRUCTURE.VEHICLE.VehicleCondition[external]@Infrastruktur; Das Signal zeigt an, ob der berechnete Wert von Status_Zustand_Fahrzeug==Fahren im Sinne der Sicherheitsanforderungen nach ASIL B korrekt ist und ob die sicherheitsrelevanten Eingangsgrößen gültig vorliegen. Alle anderen Fzg.-Zustände erfüllen KEINE Anforderungen der funktionalen Sicherheit. Qualifier_Status_Zustand_Fahrzeug == "Signalwert gültig" gilt, wenn - Status_Zustand_Fahrzeug == Fahren und - Status_Fahren_Bereitschaft_Antrieb == Fahrbereitschaft und - alle sicherheitsrelevanten Eingangsgrößen gültig vorliegen Interpretation: Das Fzg. Befindet im Zustand Fahren, ASIL B. Qualifier_Status_Zustand_Fahrzeug == "Signalwert eingeschränkt gültig" gilt, wenn - (Status_Zustand_Fahren== Fahren und Status_Fahren_Bereitschaft_Antrieb!=Fahrbereitschaft) oder - (Status_Zustand_Fahren!= Fahren und Status_Fahren_Bereitschaft_Antrieb==Fahrbereitschaft) oder - (Status_Zustand_Fahren==Fahren und Status_Fahren_Bereitschaft_Antrieb==Fahrbereitschaft und Sicherheitsrelvante Eingangsgössen liegen nicht gültig vor Interpretation: Das Fzg befindet sich im Zustand Fahren, ASIL B Bedingungen nicht erfüllt. Qualifier_Status_Zustand_Fahrzeug == " Wert nicht verfügbar " gilt, wenn - Status_Zustand_Fahrzeug != Fahren und - Status_Fahren_Bereitschaft_Antrieb != Fahrbereitschaft Interpretation: Keine Überprüfung von Fzg.-Zuständen != Fahren gem. ISO26262
          signal ST_CON_VEH: start 48, 4 bit, little-endian, base-type=uint8, invalid-value=value_15Dot0:15, compu-method=ST_CON_VEH, transfer-property=TRIGGERED-ON-CHANGE, to EPS  # Status_Zustand_Fahrzeug / status_condition_vehicle | LogicalInterface:BMW.INFRASTRUCTURE.VEHICLE.VehicleCondition[external]@Infrastruktur; Das Signal Status_Zustand_Fahrzeug beschreibt den Fahrzeugzustand (Lastenheft "Parken, Wohnen, Fahren", 10000924) aus Kundensicht. Anhand dieses Zustandes wird festgelegt, welche (Kunden-)Funktionen aktuell verfügbar sein sollen. Die Aktivbedingung für die einzelnen Funktionen sind der E/E-Funktionsliste zu entnehmen.
          mapping sigGroup_CON_VEH: i-signal-group=sigGroup_CON_VEH
      frame TL_MST_GW_TRNSM_FR_254: to EPS, category=TPL, frame-length=254, flexray-absolutely-scheduled-timing{communication-cycle=cycle-repetition={base-cycle=0, cycle-repetition=CYCLE-REPETITION-1}, slot-id=147}, allow-dynamic-l-sdu-length=false, payload-preamble-indicator=false  # Transport-Layer Master Gateway Übertragung FlexRay_254 | ACHTUNG: Die Länge dieser Nachricht ist variabel, bis 254 Byte. Die genaue TL-Spezifikation für FlexRay ist im Lastenheft FlexRay, Part 3: Process and Software (SAP-Nr.: 10000879-000) beschrieben.
        n pdu TL_MST_GW_TRNSM_FR_254: length=254  # Transport-Layer Master Gateway Übertragung FlexRay_254 | ACHTUNG: Die Länge dieser Nachricht ist variabel, bis 254 Byte. Die genaue TL-Spezifikation für FlexRay ist im Lastenheft FlexRay, Part 3: Process and Software (SAP-Nr.: 10000879-000) beschrieben.
      frame TL_ECU_TRNSM_FR_32: from EPS, category=TPL, frame-length=32, flexray-absolutely-scheduled-timing{communication-cycle=cycle-repetition={base-cycle=0, cycle-repetition=CYCLE-REPETITION-1}, slot-id=183}, allow-dynamic-l-sdu-length=false, payload-preamble-indicator=false  # Transport-Layer STG Übertragung FlexRay_32 | ACHTUNG: Die Länge dieser Nachricht ist variabel, aber maximal 32 byte. Die genaue TL-Spezifikation für FlexRay ist im Lastenheft FlexRay, Part 3: Process and Software (SAP-Nr.: 10000879-000) beschrieben.
        n pdu TL_ECU_TRNSM_FR_32: length=32  # Transport-Layer STG Übertragung FlexRay_32 | ACHTUNG: Die Länge dieser Nachricht ist variabel, aber maximal 32 byte. Die genaue TL-Spezifikation für FlexRay ist im Lastenheft FlexRay, Part 3: Process and Software (SAP-Nr.: 10000879-000) beschrieben.
      frame TL_BRC_FR_32: to EPS, category=TPL, frame-length=32, flexray-absolutely-scheduled-timing{communication-cycle=cycle-repetition={base-cycle=0, cycle-repetition=CYCLE-REPETITION-1}, slot-id=209}, allow-dynamic-l-sdu-length=false, payload-preamble-indicator=false  # Transport-Layer Broadcast FlexRay_32
        n pdu TL_BRC_FR_32: length=32  # Transport-Layer Broadcast FlexRay_32 | ACHTUNG: Die Länge dieser Nachricht ist variabel, aber maximal 32 Byte. Die genaue TL-Spezifikation für FlexRay ist im Lastenheft FlexRay, Part 3: Process and Software (SAP-Nr.: 10000879-000) beschrieben. ACHTUNG: Bitte unbedingt beachten, dass alle Slots in der Transport Layer Area 3 (209-213) von allen Steuergeräten standardmäßig empfangen werden müssen. Ausnahme: Steuergeräte, die als Sender für einen Slot-Cycle eingetragen sind, müssen diesen Slot-Cycle nicht empfangen.
      frame TL_BRC_FR_32: to EPS, category=TPL, frame-length=32, flexray-absolutely-scheduled-timing{communication-cycle=cycle-repetition={base-cycle=0, cycle-repetition=CYCLE-REPETITION-1}, slot-id=210}, allow-dynamic-l-sdu-length=false, payload-preamble-indicator=false  # Transport-Layer Broadcast FlexRay_32
        carries pdu TL_BRC_FR_32: packing-byte-order=little-endian, start-position=0
      frame TL_BRC_FR_32: to EPS, category=TPL, frame-length=32, flexray-absolutely-scheduled-timing{communication-cycle=cycle-repetition={base-cycle=0, cycle-repetition=CYCLE-REPETITION-1}, slot-id=211}, allow-dynamic-l-sdu-length=false, payload-preamble-indicator=false  # Transport-Layer Broadcast FlexRay_32
        carries pdu TL_BRC_FR_32: packing-byte-order=little-endian, start-position=0
      frame TL_BRC_FR_32: to EPS, category=TPL, frame-length=32, flexray-absolutely-scheduled-timing{communication-cycle=cycle-repetition={base-cycle=0, cycle-repetition=CYCLE-REPETITION-1}, slot-id=212}, allow-dynamic-l-sdu-length=false, payload-preamble-indicator=false  # Transport-Layer Broadcast FlexRay_32
        carries pdu TL_BRC_FR_32: packing-byte-order=little-endian, start-position=0
      frame TL_BRC_FR_32: to EPS, category=TPL, frame-length=32, flexray-absolutely-scheduled-timing{communication-cycle=cycle-repetition={base-cycle=0, cycle-repetition=CYCLE-REPETITION-1}, slot-id=213}, allow-dynamic-l-sdu-length=false, payload-preamble-indicator=false  # Transport-Layer Broadcast FlexRay_32
        carries pdu TL_BRC_FR_32: packing-byte-order=little-endian, start-position=0
      frame SVC: to EPS, category=SERVICE, frame-length=8, flexray-absolutely-scheduled-timing{communication-cycle=cycle-repetition={base-cycle=3, cycle-repetition=CYCLE-REPETITION-4}, slot-id=214}, allow-dynamic-l-sdu-length=false, payload-preamble-indicator=false  # Dienste / Services | Dieser Frame löst die bis einschließlich SP2015 gültige Version des gleichnamigen Frames ab. Ab SP2018 darf nur noch diese Version des Frames verwendet werden. Die Dienste-Nachricht kann von mehreren Steuergeräten versendet werden und ist eine Multiplex-Nachricht. Um sicherzustellen, dass dabei mit verschiedenen Identifiern gesendet wird, wird zu einer "Basis-ID" von 580h (10110000000b) die Steuergeräteadresse des jeweiligen Senders hinzuaddiert. Der in der ID2 übertragene Wert gibt an, welcher Dienst übertragen wird, resp. wie die Bytes 1-7 zu interpretieren sind. Die Auslösebedingungen (inkl. Entprellzeiten) beziehen sich dabei immer auf die ID2, nicht auf die Bus-ID.
        multiplexed i pdu SVC:  # Dienste / Services
          length=8
          dynamic-part{segment-position{segment-byte-order=little-endian, segment-length=64, segment-position=0}, dynamic-part-alternatives=[{i-pdu=SECU_CHAL, initial-dynamic-part=false, selector-field-code=248}, {i-pdu=RQ_STG_EFAN, initial-dynamic-part=false, selector-field-code=21}, {i-pdu=SECU_RESP, initial-dynamic-part=false, selector-field-code=247}, {i-pdu=ANFRAGE, initial-dynamic-part=true, selector-field-code=1}]}
          selector-field-byte-order=little-endian
          selector-field-length=8
          selector-field-start-position=0
          trigger-mode=DYNAMIC-PART-TRIGGER
          unused-bit-pattern=255
      frame SVC: to EPS, category=SERVICE, frame-length=8, flexray-absolutely-scheduled-timing{communication-cycle=cycle-repetition={base-cycle=10, cycle-repetition=CYCLE-REPETITION-16}, slot-id=215}, allow-dynamic-l-sdu-length=false, payload-preamble-indicator=false  # Dienste / Services | Dieser Frame löst die bis einschließlich SP2015 gültige Version des gleichnamigen Frames ab. Ab SP2018 darf nur noch diese Version des Frames verwendet werden. Die Dienste-Nachricht kann von mehreren Steuergeräten versendet werden und ist eine Multiplex-Nachricht. Um sicherzustellen, dass dabei mit verschiedenen Identifiern gesendet wird, wird zu einer "Basis-ID" von 580h (10110000000b) die Steuergeräteadresse des jeweiligen Senders hinzuaddiert. Der in der ID2 übertragene Wert gibt an, welcher Dienst übertragen wird, resp. wie die Bytes 1-7 zu interpretieren sind. Die Auslösebedingungen (inkl. Entprellzeiten) beziehen sich dabei immer auf die ID2, nicht auf die Bus-ID.
        carries pdu SVC: packing-byte-order=little-endian, start-position=0
      frame SVC: to EPS, category=SERVICE, frame-length=8, flexray-absolutely-scheduled-timing{communication-cycle=cycle-repetition={base-cycle=2, cycle-repetition=CYCLE-REPETITION-16}, slot-id=215}, allow-dynamic-l-sdu-length=false, payload-preamble-indicator=false  # Dienste / Services | Dieser Frame löst die bis einschließlich SP2015 gültige Version des gleichnamigen Frames ab. Ab SP2018 darf nur noch diese Version des Frames verwendet werden. Die Dienste-Nachricht kann von mehreren Steuergeräten versendet werden und ist eine Multiplex-Nachricht. Um sicherzustellen, dass dabei mit verschiedenen Identifiern gesendet wird, wird zu einer "Basis-ID" von 580h (10110000000b) die Steuergeräteadresse des jeweiligen Senders hinzuaddiert. Der in der ID2 übertragene Wert gibt an, welcher Dienst übertragen wird, resp. wie die Bytes 1-7 zu interpretieren sind. Die Auslösebedingungen (inkl. Entprellzeiten) beziehen sich dabei immer auf die ID2, nicht auf die Bus-ID.
        carries pdu SVC: packing-byte-order=little-endian, start-position=0
      frame SVC: to EPS, category=SERVICE, frame-length=8, flexray-absolutely-scheduled-timing{communication-cycle=cycle-repetition={base-cycle=5, cycle-repetition=CYCLE-REPETITION-16}, slot-id=215}, allow-dynamic-l-sdu-length=false, payload-preamble-indicator=false  # Dienste / Services | Dieser Frame löst die bis einschließlich SP2015 gültige Version des gleichnamigen Frames ab. Ab SP2018 darf nur noch diese Version des Frames verwendet werden. Die Dienste-Nachricht kann von mehreren Steuergeräten versendet werden und ist eine Multiplex-Nachricht. Um sicherzustellen, dass dabei mit verschiedenen Identifiern gesendet wird, wird zu einer "Basis-ID" von 580h (10110000000b) die Steuergeräteadresse des jeweiligen Senders hinzuaddiert. Der in der ID2 übertragene Wert gibt an, welcher Dienst übertragen wird, resp. wie die Bytes 1-7 zu interpretieren sind. Die Auslösebedingungen (inkl. Entprellzeiten) beziehen sich dabei immer auf die ID2, nicht auf die Bus-ID.
        carries pdu SVC: packing-byte-order=little-endian, start-position=0
      frame SVC: to EPS, category=SERVICE, frame-length=8, flexray-absolutely-scheduled-timing{communication-cycle=cycle-repetition={base-cycle=6, cycle-repetition=CYCLE-REPETITION-16}, slot-id=215}, allow-dynamic-l-sdu-length=false, payload-preamble-indicator=false  # Dienste / Services | Dieser Frame löst die bis einschließlich SP2015 gültige Version des gleichnamigen Frames ab. Ab SP2018 darf nur noch diese Version des Frames verwendet werden. Die Dienste-Nachricht kann von mehreren Steuergeräten versendet werden und ist eine Multiplex-Nachricht. Um sicherzustellen, dass dabei mit verschiedenen Identifiern gesendet wird, wird zu einer "Basis-ID" von 580h (10110000000b) die Steuergeräteadresse des jeweiligen Senders hinzuaddiert. Der in der ID2 übertragene Wert gibt an, welcher Dienst übertragen wird, resp. wie die Bytes 1-7 zu interpretieren sind. Die Auslösebedingungen (inkl. Entprellzeiten) beziehen sich dabei immer auf die ID2, nicht auf die Bus-ID.
        carries pdu SVC: packing-byte-order=little-endian, start-position=0
      frame SVC: to EPS, category=SERVICE, frame-length=8, flexray-absolutely-scheduled-timing{communication-cycle=cycle-repetition={base-cycle=9, cycle-repetition=CYCLE-REPETITION-16}, slot-id=215}, allow-dynamic-l-sdu-length=false, payload-preamble-indicator=false  # Dienste / Services | Dieser Frame löst die bis einschließlich SP2015 gültige Version des gleichnamigen Frames ab. Ab SP2018 darf nur noch diese Version des Frames verwendet werden. Die Dienste-Nachricht kann von mehreren Steuergeräten versendet werden und ist eine Multiplex-Nachricht. Um sicherzustellen, dass dabei mit verschiedenen Identifiern gesendet wird, wird zu einer "Basis-ID" von 580h (10110000000b) die Steuergeräteadresse des jeweiligen Senders hinzuaddiert. Der in der ID2 übertragene Wert gibt an, welcher Dienst übertragen wird, resp. wie die Bytes 1-7 zu interpretieren sind. Die Auslösebedingungen (inkl. Entprellzeiten) beziehen sich dabei immer auf die ID2, nicht auf die Bus-ID.
        carries pdu SVC: packing-byte-order=little-endian, start-position=0
      frame SVC: to EPS, category=SERVICE, frame-length=8, flexray-absolutely-scheduled-timing{communication-cycle=cycle-repetition={base-cycle=10, cycle-repetition=CYCLE-REPETITION-16}, slot-id=216}, allow-dynamic-l-sdu-length=false, payload-preamble-indicator=false  # Dienste / Services | Dieser Frame löst die bis einschließlich SP2015 gültige Version des gleichnamigen Frames ab. Ab SP2018 darf nur noch diese Version des Frames verwendet werden. Die Dienste-Nachricht kann von mehreren Steuergeräten versendet werden und ist eine Multiplex-Nachricht. Um sicherzustellen, dass dabei mit verschiedenen Identifiern gesendet wird, wird zu einer "Basis-ID" von 580h (10110000000b) die Steuergeräteadresse des jeweiligen Senders hinzuaddiert. Der in der ID2 übertragene Wert gibt an, welcher Dienst übertragen wird, resp. wie die Bytes 1-7 zu interpretieren sind. Die Auslösebedingungen (inkl. Entprellzeiten) beziehen sich dabei immer auf die ID2, nicht auf die Bus-ID.
        carries pdu SVC: packing-byte-order=little-endian, start-position=0
      frame SVC: to EPS, category=SERVICE, frame-length=8, flexray-absolutely-scheduled-timing{communication-cycle=cycle-repetition={base-cycle=12, cycle-repetition=CYCLE-REPETITION-16}, slot-id=216}, allow-dynamic-l-sdu-length=false, payload-preamble-indicator=false  # Dienste / Services | Dieser Frame löst die bis einschließlich SP2015 gültige Version des gleichnamigen Frames ab. Ab SP2018 darf nur noch diese Version des Frames verwendet werden. Die Dienste-Nachricht kann von mehreren Steuergeräten versendet werden und ist eine Multiplex-Nachricht. Um sicherzustellen, dass dabei mit verschiedenen Identifiern gesendet wird, wird zu einer "Basis-ID" von 580h (10110000000b) die Steuergeräteadresse des jeweiligen Senders hinzuaddiert. Der in der ID2 übertragene Wert gibt an, welcher Dienst übertragen wird, resp. wie die Bytes 1-7 zu interpretieren sind. Die Auslösebedingungen (inkl. Entprellzeiten) beziehen sich dabei immer auf die ID2, nicht auf die Bus-ID.
        carries pdu SVC: packing-byte-order=little-endian, start-position=0
      frame SVC: to EPS, category=SERVICE, frame-length=8, flexray-absolutely-scheduled-timing{communication-cycle=cycle-repetition={base-cycle=13, cycle-repetition=CYCLE-REPETITION-16}, slot-id=216}, allow-dynamic-l-sdu-length=false, payload-preamble-indicator=false  # Dienste / Services | Dieser Frame löst die bis einschließlich SP2015 gültige Version des gleichnamigen Frames ab. Ab SP2018 darf nur noch diese Version des Frames verwendet werden. Die Dienste-Nachricht kann von mehreren Steuergeräten versendet werden und ist eine Multiplex-Nachricht. Um sicherzustellen, dass dabei mit verschiedenen Identifiern gesendet wird, wird zu einer "Basis-ID" von 580h (10110000000b) die Steuergeräteadresse des jeweiligen Senders hinzuaddiert. Der in der ID2 übertragene Wert gibt an, welcher Dienst übertragen wird, resp. wie die Bytes 1-7 zu interpretieren sind. Die Auslösebedingungen (inkl. Entprellzeiten) beziehen sich dabei immer auf die ID2, nicht auf die Bus-ID.
        carries pdu SVC: packing-byte-order=little-endian, start-position=0
      frame SVC: to EPS, category=SERVICE, frame-length=8, flexray-absolutely-scheduled-timing{communication-cycle=cycle-repetition={base-cycle=14, cycle-repetition=CYCLE-REPETITION-16}, slot-id=216}, allow-dynamic-l-sdu-length=false, payload-preamble-indicator=false  # Dienste / Services | Dieser Frame löst die bis einschließlich SP2015 gültige Version des gleichnamigen Frames ab. Ab SP2018 darf nur noch diese Version des Frames verwendet werden. Die Dienste-Nachricht kann von mehreren Steuergeräten versendet werden und ist eine Multiplex-Nachricht. Um sicherzustellen, dass dabei mit verschiedenen Identifiern gesendet wird, wird zu einer "Basis-ID" von 580h (10110000000b) die Steuergeräteadresse des jeweiligen Senders hinzuaddiert. Der in der ID2 übertragene Wert gibt an, welcher Dienst übertragen wird, resp. wie die Bytes 1-7 zu interpretieren sind. Die Auslösebedingungen (inkl. Entprellzeiten) beziehen sich dabei immer auf die ID2, nicht auf die Bus-ID.
        carries pdu SVC: packing-byte-order=little-endian, start-position=0
      frame SVC: to EPS, category=SERVICE, frame-length=8, flexray-absolutely-scheduled-timing{communication-cycle=cycle-repetition={base-cycle=15, cycle-repetition=CYCLE-REPETITION-16}, slot-id=216}, allow-dynamic-l-sdu-length=false, payload-preamble-indicator=false  # Dienste / Services | Dieser Frame löst die bis einschließlich SP2015 gültige Version des gleichnamigen Frames ab. Ab SP2018 darf nur noch diese Version des Frames verwendet werden. Die Dienste-Nachricht kann von mehreren Steuergeräten versendet werden und ist eine Multiplex-Nachricht. Um sicherzustellen, dass dabei mit verschiedenen Identifiern gesendet wird, wird zu einer "Basis-ID" von 580h (10110000000b) die Steuergeräteadresse des jeweiligen Senders hinzuaddiert. Der in der ID2 übertragene Wert gibt an, welcher Dienst übertragen wird, resp. wie die Bytes 1-7 zu interpretieren sind. Die Auslösebedingungen (inkl. Entprellzeiten) beziehen sich dabei immer auf die ID2, nicht auf die Bus-ID.
        carries pdu SVC: packing-byte-order=little-endian, start-position=0
      frame SVC: to EPS, category=SERVICE, frame-length=8, flexray-absolutely-scheduled-timing{communication-cycle=cycle-repetition={base-cycle=6, cycle-repetition=CYCLE-REPETITION-16}, slot-id=216}, allow-dynamic-l-sdu-length=false, payload-preamble-indicator=false  # Dienste / Services | Dieser Frame löst die bis einschließlich SP2015 gültige Version des gleichnamigen Frames ab. Ab SP2018 darf nur noch diese Version des Frames verwendet werden. Die Dienste-Nachricht kann von mehreren Steuergeräten versendet werden und ist eine Multiplex-Nachricht. Um sicherzustellen, dass dabei mit verschiedenen Identifiern gesendet wird, wird zu einer "Basis-ID" von 580h (10110000000b) die Steuergeräteadresse des jeweiligen Senders hinzuaddiert. Der in der ID2 übertragene Wert gibt an, welcher Dienst übertragen wird, resp. wie die Bytes 1-7 zu interpretieren sind. Die Auslösebedingungen (inkl. Entprellzeiten) beziehen sich dabei immer auf die ID2, nicht auf die Bus-ID.
        carries pdu SVC: packing-byte-order=little-endian, start-position=0
      frame SVC: to EPS, category=SERVICE, frame-length=8, flexray-absolutely-scheduled-timing{communication-cycle=cycle-repetition={base-cycle=7, cycle-repetition=CYCLE-REPETITION-16}, slot-id=216}, allow-dynamic-l-sdu-length=false, payload-preamble-indicator=false  # Dienste / Services | Dieser Frame löst die bis einschließlich SP2015 gültige Version des gleichnamigen Frames ab. Ab SP2018 darf nur noch diese Version des Frames verwendet werden. Die Dienste-Nachricht kann von mehreren Steuergeräten versendet werden und ist eine Multiplex-Nachricht. Um sicherzustellen, dass dabei mit verschiedenen Identifiern gesendet wird, wird zu einer "Basis-ID" von 580h (10110000000b) die Steuergeräteadresse des jeweiligen Senders hinzuaddiert. Der in der ID2 übertragene Wert gibt an, welcher Dienst übertragen wird, resp. wie die Bytes 1-7 zu interpretieren sind. Die Auslösebedingungen (inkl. Entprellzeiten) beziehen sich dabei immer auf die ID2, nicht auf die Bus-ID.
        carries pdu SVC: packing-byte-order=little-endian, start-position=0
      frame SVC: from EPS, category=SERVICE, frame-length=8, flexray-absolutely-scheduled-timing{communication-cycle=cycle-repetition={base-cycle=9, cycle-repetition=CYCLE-REPETITION-16}, slot-id=216}, allow-dynamic-l-sdu-length=false, payload-preamble-indicator=false  # Dienste / Services | Dieser Frame löst die bis einschließlich SP2015 gültige Version des gleichnamigen Frames ab. Ab SP2018 darf nur noch diese Version des Frames verwendet werden. Die Dienste-Nachricht kann von mehreren Steuergeräten versendet werden und ist eine Multiplex-Nachricht. Um sicherzustellen, dass dabei mit verschiedenen Identifiern gesendet wird, wird zu einer "Basis-ID" von 580h (10110000000b) die Steuergeräteadresse des jeweiligen Senders hinzuaddiert. Der in der ID2 übertragene Wert gibt an, welcher Dienst übertragen wird, resp. wie die Bytes 1-7 zu interpretieren sind. Die Auslösebedingungen (inkl. Entprellzeiten) beziehen sich dabei immer auf die ID2, nicht auf die Bus-ID.
        carries pdu SVC: packing-byte-order=little-endian, start-position=0
      frame xcpmaster: to EPS, category=XCP_PRE_CONFIGURED, frame-length=32, flexray-absolutely-scheduled-timing{communication-cycle=cycle-repetition={base-cycle=0, cycle-repetition=CYCLE-REPETITION-1}, slot-id=219}, allow-dynamic-l-sdu-length=false, payload-preamble-indicator=false  # XCP-Master | XCP-Masterframe für die Kommunikation vom Master zum Slave (Pre-Configured).
        general purpose i pdu dummy32bmaster: category=XCP, length=32  # Dummy-PDU 32 Byte XCP-Master | Die PDU (32 Byte lang) hat ebenso keine inhaltliche Verbindlichkeit.
      frame xcpslave: from EPS, category=XCP_PRE_CONFIGURED, frame-length=32, flexray-absolutely-scheduled-timing{communication-cycle=cycle-repetition={base-cycle=0, cycle-repetition=CYCLE-REPETITION-1}, slot-id=220}, allow-dynamic-l-sdu-length=false, payload-preamble-indicator=false  # XCP-Slave | Frame für die Kommunikation von den Slaves zum Master (Pre-Configured).
        general purpose i pdu dummy32bslave: category=XCP, length=32  # Dummy-PDU 32 Byte XCP-Slave | Dummy-PDU ohne inhaltliche Verbindlichkeit mit 32 Byte für Infrastruktur (z.B. XCP).
      frame ST_ENERG_GEN: to EPS, category=APPLICATION, frame-length=8, flexray-absolutely-scheduled-timing{communication-cycle=cycle-repetition={base-cycle=1, cycle-repetition=CYCLE-REPETITION-2}, slot-id=232}, allow-dynamic-l-sdu-length=false, payload-preamble-indicator=false  # Status Energieerzeugung
        pdu ST_ENERG_GEN: length=8, minimum-delay=0.05, transmission-mode-true-timing={cyclic-timing=time-period={tolerance=absolute-tolerance=0.2, value=1}, event-controlled-timing=number-of-repetitions=0}, unused-bit-pattern=255  # Status Energieerzeugung | Diese Nachricht wird in Hybridfahrzeugen nicht auf dem FA-CAN gesendet.
          signal ST_LDREL_GEN: start 56, 4 bit, little-endian, base-type=uint8, invalid-value=value_15Dot0:15, compu-method=ST_LDREL_GEN, transfer-property=TRIGGERED-ON-CHANGE, to EPS  # Status_Entlastung_Generator / status_load-relieving_generator | LogicalInterface:BMW.INFRASTRUCTURE.LOWVOLTAGE.GeneratorInterface[external]@Infrastruktur; Überträgt den aktuellen Zustand der Generator Entlastungsfunktion (Bestandteil von AEP).
          signal ST_SEP_STOR: start 40, 2 bit, little-endian, base-type=uint8, invalid-value=value_3Dot0:3, compu-method=ST_DCSW, transfer-property=TRIGGERED-ON-CHANGE, to EPS  # Status_Trennelement_Speicher / status_separating-element_store | LogicalInterface:BMW.INFRASTRUCTURE.LOWVOLTAGE.EnergyManagementConverter[internal]@Infrastruktur; Mit diesem Signal wird angezeigt, ob das Trennelement auf die Position 12V oder 24V ist, oder ob er in der Abwartezeit ist bevor eine Umschaltung aus der 24V Position zu der 12V Position.
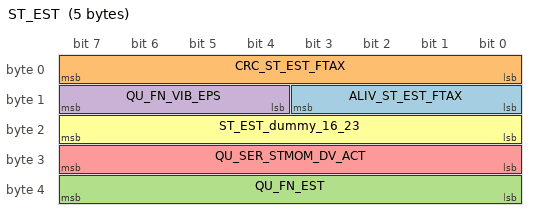
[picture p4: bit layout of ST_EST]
      frame ST_EST: from EPS, category=APPLICATION, frame-length=5, flexray-absolutely-scheduled-timing{communication-cycle=cycle-repetition={base-cycle=1, cycle-repetition=CYCLE-REPETITION-2}, slot-id=234}, allow-dynamic-l-sdu-length=false, payload-preamble-indicator=false  # Status Elektrische-Lenkung Vorderachse / status electrical-steering front-axle
        pdu ST_EST: length=5, minimum-delay=0.05, transmission-mode-true-timing={cyclic-timing=time-period={tolerance=absolute-tolerance=0.1, value=0.5}, event-controlled-timing={number-of-repetitions=0, "Dreimalige Versendung bei SIGNALCHANGE"}}, unused-bit-pattern=255  # Status Elektrische-Lenkung Vorderachse / status electrical-steering front-axle | Gerätestatus der EPS
          signal ALIV_ST_EST_FTAX: start 8, 4 bit, little-endian, base-type=uint8, invalid-value=value_15Dot0:15, compu-method=ALIV_COU_4, transfer-property=TRIGGERED-ON-CHANGE  # Alive_Status_Elektrische-Lenkung_Vorderachse / alive_status_electrical-steering_front-axle | LogicalInterface:BMW.CHASSIS.STEERING.ElectricPowerSteering[internal]@Fahren; Standardabsicherung Alivezähler laut Definition per Lastenheft Allgemeine Bordnetzkommunikation.
          signal CRC_ST_EST_FTAX: start 0, 8 bit, little-endian, base-type=uint8, compu-method=CRC8, data-constr=CRC8, transfer-property=TRIGGERED-ON-CHANGE  # CRC_Status_Elektrische-Lenkung_Vorderachse / CRC_status_electrical-steering_front-axle | LogicalInterface:BMW.CHASSIS.STEERING.ElectricPowerSteering[internal]@Fahren; Standardabsicherung Applikations-CRC laut Definition per Lastenheft Allgemeine Bordnetzkommunikation. Dieses Signal verwendet die Applikations-CRC-ID = 112 (Dez)
          signal QU_FN_EST: start 32, 8 bit, little-endian, base-type=uint8, invalid-value=value_255Dot0:255, compu-method=QU_FN_EST, transfer-property=TRIGGERED-ON-CHANGE  # Qualifier_Funktion_Elektrische-Lenkung / Qualifier_function_electrical-steering | LogicalInterface:BMW.CHASSIS.STEERING.ElectricPowerSteering[internal]@Fahren; Der Funktionsqualifier teilt anderen Systemen im Fahrzeugverbund mit, ob und wie die EPS Funktion zur Verfügung steht. Hierbei ist die EPS Degradierung mittels 60h = 0110 0000 oder B0h = 1011 0000 zu versenden. 60h für den Fall, dass die Funktion der EPS bis zum nächsten Klemmenwechsel degradiert bleibt. B0h für den Fall, dass eine "Heilung" im aktuellen Zündungszyklus möglich ist. Mittels des EPS Funktionsqualifiers ist es zusätzlich möglich zu erkennen, um welche EPS es sich im Fahrzeug handelt. Hierbei sind durch die EPS folgende Spezifikation zu bedienen: - 12V EPS 1010 0000 A0h - 12V EAS 1010 0100 A4h - 24V EAS 1010 1000 A8h Sollte in einem Fahrzeug die große Bordnetzerweiterung mit ihrem hohen Spannungsniveau ausgefallen sein, so wird dies dem Fahrzeugverbund durch die EPS durch die Bitkombination des Qualifiers wie folgt mitgeteilt: - 24V EAS, EPS Kl.30 Abfall von 24V -> 12V 0011 0001 31h
          signal QU_FN_VIB_EPS: start 12, 4 bit, little-endian, base-type=uint8, invalid-value=value_15Dot0:15, compu-method=QU_FN_VIB_EPS, transfer-property=TRIGGERED-ON-CHANGE  # Qualifier_Funktion_Vibration_EPS / Qualifier_function_vibration_EPS | LogicalInterface:BMW.CHASSIS.STEERING.ElectricPowerSteering[internal]@Fahren; Funktionsqualifier zur EPS-Lenkradvibration
          signal QU_SER_STMOM_DV_ACT: start 24, 8 bit, little-endian, base-type=uint8, invalid-value=value_255Dot0:255, compu-method=QU_SER_STMOM_STMOM_DV_ACT, transfer-property=TRIGGERED-ON-CHANGE  # Qualifier_Service_Lenkmoment_Fahrer_Stellglied / Qualifier_service_steering-moment_driver_actuator | LogicalInterface:BMW.CHASSIS.STEERING.ElectricPowerSteering[internal]@Fahren; Der Service Qualifier Qualifier_Service_Lenkmoment_Fahrer_Stellglied (QU_SER_STMOM_DV_ACT) gillt in der L6: für die Offset Handmomentenschnittstelle. in der L7 und folgenden Baureihen: für die Fahrdynamikschnittstelle, bestehend aus der Offset Handmomenten-, Offset Motormomenten- und der Faktorenschnittstelle. D.h. sofern alle Sollwerte der Unterschnittstellen funktional umsetzbar sind, wird dies über den einen Service Qualifier der Fahrdynamikschnittstelle mitgeteilt. Die Fahrdynamikschnittstelle erlaubt eine Modifikation der interner bestimmten Sollwerte. (Handmoment, Motormoment, Rücklauf,...) Sollte ein funktionales Problem bei der Ansteuerung der Schnittstellen vorliegen, so wird die betroffene Anforderung auf BMW Seite heraus gerampt.
          signal ST_EST_dummy_16_23: start 16, 8 bit, little-endian, init-value=255, base-type=uint8, compu-method=UINT8, data-constr=UINT8, transfer-property=PENDING
          mapping sigGroup_ST_EST: i-signal-group=sigGroup_ST_EST
      frame SECU_FAHRGESTELLNUMMER: to EPS, category=APPLICATION, frame-length=8, flexray-absolutely-scheduled-timing{communication-cycle=cycle-repetition={base-cycle=0, cycle-repetition=CYCLE-REPETITION-4}, slot-id=244}, allow-dynamic-l-sdu-length=false, payload-preamble-indicator=false  # Sicher Fahrgestellnummer
        pdu SECU_FAHRGESTELLNUMMER: length=8, minimum-delay=0.05, transmission-mode-true-timing=event-controlled-timing=number-of-repetitions=0, unused-bit-pattern=255  # Sicher Fahrgestellnummer | $(AUTOSAR; SIGNALGROUP)
          signal STU_8_BYTE: start 0, 64 bit, little-endian, base-type=uint64, invalid-value=value_18446744073709551615:18446744073709552000, compu-method=STU_8_BYTE, data-constr=STU_8_BYTE, to EPS  # Signatur_8_Byte / signature_8_byte | LogicalInterface:BMW.INFRASTRUCTURE.VEHICLE.VehicleInformation[internal]@Infrastruktur;
      frame CTR_DIAG_OBD_DRDY: to EPS, category=APPLICATION, frame-length=2, flexray-absolutely-scheduled-timing{communication-cycle=cycle-repetition={base-cycle=0, cycle-repetition=CYCLE-REPETITION-2}, slot-id=247}, allow-dynamic-l-sdu-length=false, payload-preamble-indicator=false  # Steuerung Diagnose OBD Fahrdynamik
        pdu CTR_DIAG_OBD_DRDY: length=2, minimum-delay=0.05, transmission-mode-true-timing={cyclic-timing=time-period={tolerance=absolute-tolerance=0.2, value=1}, event-controlled-timing={number-of-repetitions=0, "Bei Anforderung "OBD-Fehlerspeicher löschen" in der DSC wird die Nachricht zusätzlich versendet."}}, unused-bit-pattern=255  # Steuerung Diagnose OBD Fahrdynamik | Bis SP2015: Diese PDU wird nur versendet, wenn das DSC "OBD-relevant" bzw. "OBD-konform" ist. Ab SP2018: Diese PDU wird permanent versendet – unabhängig davon, ob das DSC "OBD-relevant" bzw. "OBD-konform" ist. Diese PDU beinhaltet: - Die Anforderung der MIL an die Motorsteuerung der Verbrennungsmaschine. - Die Anforderung an die zugeordnete "Dependent Secondary Devices", dass gerade die OBD-Diagnose zurückzusetzen ist.
          signal RQ_RST_OBD_DIAG_DRDY: start 2, 2 bit, little-endian, base-type=uint8, invalid-value=value_3Dot0:3, compu-method=RQ_RST_OBD_DIAG, transfer-property=TRIGGERED-ON-CHANGE, to EPS  # Anforderung_Reset_OBD_Diagnose_Fahrdynamik / request_reset_OBD_diagnosis_driving-dynamics | LogicalInterface:BMW.INFRASTRUCTURE.DIAGNOSIS.OnBoardDiagnosis[external]@Infrastruktur; Das "Primary Device" verwaltet den OBD-Fehlerspeicher und die Umweltbedingungen (Freezeframe). Dieses Signal enthält die Statusinfo vom "Primary Device" an das "Dependent Secondary Device", daß gerade "OBD-Fehlerspeicher löschen" angefordert wurde. Das "Dependent Secondary Device" reagiert auf dieses Signal mit dem Rücksetzen der OBD-Diagnose für die am "Dependent Secondary Device" angeschlossenen OBD-Komponenten, danach können evtl. Fehler in den angeschlossenen OBD-Komponenten neu erkannt werden. Das Signal wird nur dann versendet, wenn das Löschen des Fehlerspeichers auch wirklich erfolgen darf; z.B via Mode $04 nur bei Kl.15 an und stehendem Motor.
      frame DIAG_OBD_ENG: to EPS, category=APPLICATION, frame-length=7, flexray-absolutely-scheduled-timing{communication-cycle=cycle-repetition={base-cycle=1, cycle-repetition=CYCLE-REPETITION-2}, slot-id=247}, allow-dynamic-l-sdu-length=false, payload-preamble-indicator=false  # Diagnose OBD Motor
        pdu DIAG_OBD_ENG: length=7, minimum-delay=0.05, transmission-mode-true-timing={cyclic-timing=time-period={tolerance=absolute-tolerance=0.2, value=1}, event-controlled-timing=number-of-repetitions=0}, unused-bit-pattern=255  # Diagnose OBD Motor | Zentrale OBD Informationen von dem OBD-Master SG an alle betroffenen OBD Steuergeräte (Primary und ggf. dep. Secondary SG's). Der Zykluszähler "Fueled Engine Operation Ignition Cycle Center" wird ausschließlich in Hybrid Projekten benötigt.
          signal ST_OBD_CYC: start 0, 6 bit, little-endian, base-type=uint8, invalid-value=value_63Dot0:63, compu-method=ST_OBD_CYC, transfer-property=TRIGGERED-ON-CHANGE, to EPS  # Status_OBD_Zyklus / status_OBD_cycle | LogicalInterface:BMW.INFRASTRUCTURE.DIAGNOSIS.OnBoardDiagnosis[external]@Infrastruktur; Dieses Signal enthält Codierungen aus den alten Signalen Status_RBM-Zyklus und Status_OBD_Steuerfunktion_Getriebe_Erweitert. Dieses Signal enthält die Information, welcher Zyklus in der DME aktiv ist (Warm-Up-Zyklus, Driving-Zyklus, RBM-Zyklus). RBM-Zyklus nicht aktiv bedeutet: Nicht alle Bedingungen erfüllt RBM-Zyklus aktiv bedeutet: Alle Bedingungen erfüllt Dabei handelt es sich um folgende Bedingungen (Übernahme aus Gesetzestext): - time grösser oder gleich 600s (bei einer Höhe kleiner als 8000f, Umgebungstemperatur grösser oder gleich 20°F) - cumulative time grösser oder gleich 200s mit Geschwindigkeit grösser oder gleich 25mph (bei einer Höhe kleiner als 8000f, Umgebungstemperatur grösser oder gleich 20°F) - continous idle grösser oder gleich 30s Der PFC Zyklus entspricht dem RBM-Zyklus, jedoch ohne Berücksichtung der Höhe und der Umgebungstemperatur.
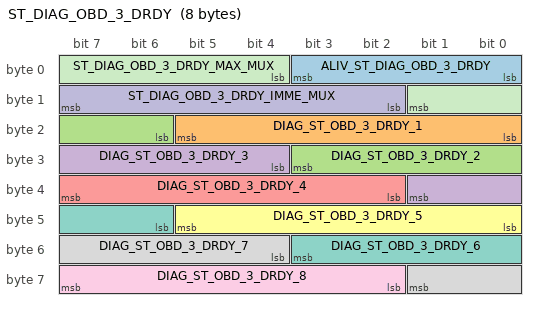
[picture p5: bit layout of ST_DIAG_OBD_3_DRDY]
      frame ST_DIAG_OBD_3_DRDY: from EPS, category=APPLICATION, frame-length=8, flexray-absolutely-scheduled-timing{communication-cycle=cycle-repetition={base-cycle=10, cycle-repetition=CYCLE-REPETITION-32}, slot-id=248}, allow-dynamic-l-sdu-length=false, payload-preamble-indicator=false  # Status Diagnose OBD 3 Fahrdynamik
        pdu ST_DIAG_OBD_3_DRDY:  # Status Diagnose OBD 3 Fahrdynamik | $(AUTOSAR; SIGNALGROUP) Zur Erfüllung der gesetzlichen Anforderungen der CARB ("California Air Resources Board") und EPA ("U.S. Environmental Protection Agency") wird das sog. Distributed-OBD-Konzept verwendet. Hierbei überwacht und diagnostiziert der Sender lokale OBD-Relevante Sensoren bzw. Funktionen und bildet daraus für jede Diagnose einen eigenen Diagnose Status zur Übermittlung der Fehlererkennung. Diese Botschaft dient zur Übermittlung der Diagnose Status an den zugeordnete OBD Host, der dann für die gesetzeskonforme Abspeicherung sorgt. Die allgemeine Spezifikation zur Umsetzung ist: vor SP2015: in der aktuell gültigen Version "Informationsaustausch im Zuge der Distributed-OBD Architektur (D-OBD)" beschrieben. ab SP2015: in der aktuell gültigen Version "Systemlastenheft OBD" beschrieben. Details zur inhaltlichen Umsetzung der Multiplexnachricht (Anzahl und Position der einzelnen übertragenen Diagnosestatusinformation) sind mit dem jeweiligen Steuergeräteverantwortlichen abzustimmen.
          length=8
          minimum-delay=0.16
          transmission-mode-true-timing=event-controlled-timing={number-of-repetitions=0, "Die PDU hat drei Triggerbedingung, die im NK aber nicht modelliert werden, da sie bei einer AUTOSAR RTE-Konfiguration stören würden und direkt in einem SW-C als Trigger implementiert werden müssen: Burst-Modus Zyklisch Eventgetriggert Vor SP2015: der erste Versand der Botschaft hat 500ms nach Klemme 15 ein zu erfolgen. Ab SP2015: der erste Versand der Botschaft hat 500ms nach Sendebereitschaft des Steuergeräts und gesetzter Aktivbedingung zu erfolgen. Die Bestimmung der 500ms erfolgt nach der internen Zeitmessung."}
          unused-bit-pattern=255
          signal ALIV_ST_DIAG_OBD_3_DRDY: start 0, 4 bit, little-endian, base-type=uint8, invalid-value=value_15Dot0:15, compu-method=ALIV_4_BIT_Unsigned_Integer, data-constr=ALIV_4_BIT_Unsigned_Integer, transfer-property=TRIGGERED-ON-CHANGE  # Alive_Status_Diagnose_OBD_3_Fahrdynamik / alive_status_diagnosis_OBD_3_driving-dynamics | LogicalInterface:BMW.INFRASTRUCTURE.DIAGNOSIS.OnBoardDiagnosis[internal]@Infrastruktur; Standardabsicherung Alivezähler laut Definition per Lastenheft Allgemeine Bordnetzkommunikation.
          signal DIAG_ST_OBD_3_DRDY_1: start 16, 6 bit, little-endian, base-type=uint8, invalid-value=value_63Dot0:63, compu-method=DIAG_ST_OBD, data-constr=DIAG_ST_OBD, transfer-property=TRIGGERED-ON-CHANGE  # Diagnose_Status_OBD_3_Fahrdynamik_1 / diagnosis_status_OBD_3_driving-dynamics_1 | LogicalInterface:BMW.INFRASTRUCTURE.DIAGNOSIS.OnBoardDiagnosis[internal]@Infrastruktur; Diagnose Status zur Übermittlung der Status des OBD-Fehler, Cal-ID, oder CVN. Den Inhalt des Signals wird über das Signal Status_Diagnose_OBD_3_Fahrdynamik_Multiplexer_Aktuell definiert (Multiplexing)
          signal DIAG_ST_OBD_3_DRDY_2: start 22, 6 bit, little-endian, base-type=uint8, invalid-value=value_63Dot0:63, compu-method=DIAG_ST_OBD, data-constr=DIAG_ST_OBD, transfer-property=TRIGGERED-ON-CHANGE  # Diagnose_Status_OBD_3_Fahrdynamik_2 / diagnosis_status_OBD_3_driving-dynamics_2 | LogicalInterface:BMW.INFRASTRUCTURE.DIAGNOSIS.OnBoardDiagnosis[internal]@Infrastruktur; Diagnose Status zur Übermittlung der Status des OBD-Fehler, Cal-ID, oder CVN. Den Inhalt des Signals wird über das Signal Status_Diagnose_OBD_3_Fahrdynamik_Multiplexer_Aktuell definiert (Multiplexing)
          signal DIAG_ST_OBD_3_DRDY_3: start 28, 6 bit, little-endian, base-type=uint8, invalid-value=value_63Dot0:63, compu-method=DIAG_ST_OBD, data-constr=DIAG_ST_OBD, transfer-property=TRIGGERED-ON-CHANGE  # Diagnose_Status_OBD_3_Fahrdynamik_3 / diagnosis_status_OBD_3_driving-dynamics_3 | LogicalInterface:BMW.INFRASTRUCTURE.DIAGNOSIS.OnBoardDiagnosis[internal]@Infrastruktur; Diagnose Status zur Übermittlung der Status des OBD-Fehler, Cal-ID, oder CVN. Den Inhalt des Signals wird über das Signal Status_Diagnose_OBD_3_Fahrdynamik_Multiplexer_Aktuell definiert (Multiplexing)
          signal DIAG_ST_OBD_3_DRDY_4: start 34, 6 bit, little-endian, base-type=uint8, invalid-value=value_63Dot0:63, compu-method=DIAG_ST_OBD, data-constr=DIAG_ST_OBD, transfer-property=TRIGGERED-ON-CHANGE  # Diagnose_Status_OBD_3_Fahrdynamik_4 / diagnosis_status_OBD_3_driving-dynamics_4 | LogicalInterface:BMW.INFRASTRUCTURE.DIAGNOSIS.OnBoardDiagnosis[internal]@Infrastruktur; Diagnose Status zur Übermittlung der Status des OBD-Fehler, Cal-ID, oder CVN. Den Inhalt des Signals wird über das Signal Status_Diagnose_OBD_3_Fahrdynamik_Multiplexer_Aktuell definiert (Multiplexing)
          signal DIAG_ST_OBD_3_DRDY_5: start 40, 6 bit, little-endian, base-type=uint8, invalid-value=value_63Dot0:63, compu-method=DIAG_ST_OBD, data-constr=DIAG_ST_OBD, transfer-property=TRIGGERED-ON-CHANGE  # Diagnose_Status_OBD_3_Fahrdynamik_5 / diagnosis_status_OBD_3_driving-dynamics_5 | LogicalInterface:BMW.INFRASTRUCTURE.DIAGNOSIS.OnBoardDiagnosis[internal]@Infrastruktur; Diagnose Status zur Übermittlung der Status des OBD-Fehler, Cal-ID, oder CVN. Den Inhalt des Signals wird über das Signal Status_Diagnose_OBD_3_Fahrdynamik_Multiplexer_Aktuell definiert (Multiplexing)
          signal DIAG_ST_OBD_3_DRDY_6: start 46, 6 bit, little-endian, base-type=uint8, invalid-value=value_63Dot0:63, compu-method=DIAG_ST_OBD, data-constr=DIAG_ST_OBD, transfer-property=TRIGGERED-ON-CHANGE  # Diagnose_Status_OBD_3_Fahrdynamik_6 / diagnosis_status_OBD_3_driving-dynamics_6 | LogicalInterface:BMW.INFRASTRUCTURE.DIAGNOSIS.OnBoardDiagnosis[internal]@Infrastruktur; Diagnose Status zur Übermittlung der Status des OBD-Fehler, Cal-ID, oder CVN. Den Inhalt des Signals wird über das Signal Status_Diagnose_OBD_3_Fahrdynamik_Multiplexer_Aktuell definiert (Multiplexing)
          signal DIAG_ST_OBD_3_DRDY_7: start 52, 6 bit, little-endian, base-type=uint8, invalid-value=value_63Dot0:63, compu-method=DIAG_ST_OBD, data-constr=DIAG_ST_OBD, transfer-property=TRIGGERED-ON-CHANGE  # Diagnose_Status_OBD_3_Fahrdynamik_7 / diagnosis_status_OBD_3_driving-dynamics_7 | LogicalInterface:BMW.INFRASTRUCTURE.DIAGNOSIS.OnBoardDiagnosis[internal]@Infrastruktur; Diagnose Status zur Übermittlung der Status des OBD-Fehler, Cal-ID, oder CVN. Den Inhalt des Signals wird über das Signal Status_Diagnose_OBD_3_Fahrdynamik_Multiplexer_Aktuell definiert (Multiplexing)
          signal DIAG_ST_OBD_3_DRDY_8: start 58, 6 bit, little-endian, base-type=uint8, invalid-value=value_63Dot0:63, compu-method=DIAG_ST_OBD, data-constr=DIAG_ST_OBD, transfer-property=TRIGGERED-ON-CHANGE  # Diagnose_Status_OBD_3_Fahrdynamik_8 / diagnosis_status_OBD_3_driving-dynamics_8 | LogicalInterface:BMW.INFRASTRUCTURE.DIAGNOSIS.OnBoardDiagnosis[internal]@Infrastruktur; Diagnose Status zur Übermittlung der Status des OBD-Fehler, Cal-ID, oder CVN. Den Inhalt des Signals wird über das Signal Status_Diagnose_OBD_3_Fahrdynamik_Multiplexer_Aktuell definiert (Multiplexing)
          signal ST_DIAG_OBD_3_DRDY_IMME_MUX: start 10, 6 bit, little-endian, base-type=uint8, invalid-value=value_63Dot0:63, compu-method=ST_DIAG_OBD_MUX_IMME, data-constr=ST_DIAG_OBD_MUX_IMME, transfer-property=TRIGGERED-ON-CHANGE  # Status_Diagnose_OBD_3_Fahrdynamik_Aktuell_Multiplexer / status_diagnosis_OBD_3_driving-dynamics_immediate_multiplexer | LogicalInterface:BMW.INFRASTRUCTURE.DIAGNOSIS.OnBoardDiagnosis[internal]@Infrastruktur; Alle Diagnose Status eines Steuergeräts werden in einer Botschaft zusammengefasst. Falls mehr als 8 Diagnose Status vorhanden sind, werden diese Inhalte in der Botschaft gemultiplext. Dieses Signal gibt den aktuellen Multiplex-Identifier an. Der maximal mögliche Wert ist dem Signal "ST_DIAG_OBD_3_DRDY_MAX_MUX" zu entnehmen.
          signal ST_DIAG_OBD_3_DRDY_MAX_MUX: start 4, 6 bit, little-endian, base-type=uint8, invalid-value=value_63Dot0:63, compu-method=ST_DIAG_OBD_MUX_MAX, data-constr=ST_DIAG_OBD_MUX_MAX, transfer-property=TRIGGERED-ON-CHANGE  # Status_Diagnose_OBD_3_Fahrdynamik_Maximal_Multiplexer / status_diagnosis_OBD_3_driving-dynamics_maximum_multiplexer | LogicalInterface:BMW.INFRASTRUCTURE.DIAGNOSIS.OnBoardDiagnosis[internal]@Infrastruktur; Alle Diagnose Status eines Steuergeräts werden in einer Botschaft zusammengefasst. Falls mehr als 8 Diagnose Status vorhanden sind, werden diese Inhalte in der Botschaft gemultiplext. Dieses Signal entspricht des maximalen Werts im Signal ST_DIAG_OBD_3_DRDY_IMME_MUX (zwischen 4 und 60 mögliche Werte).
      frame A_TEMP: to EPS, category=APPLICATION, frame-length=2, flexray-absolutely-scheduled-timing{communication-cycle=cycle-repetition={base-cycle=1, cycle-repetition=CYCLE-REPETITION-4}, slot-id=252}, allow-dynamic-l-sdu-length=false, payload-preamble-indicator=false  # Außentemperatur / Exterior temperature
        pdu A_TEMP:  # Außentemperatur / Exterior temperature | Timeout-Migration am 5. Mai 2006: Timeout-vereinheitlicht auf 3000 ms Damit wurden folgende Cluster-spezifisch abweichend vergebenen Werte geändert: Motor-CAN (4): 0ms, Motor-CAN [3]: 0ms, A_FlexRay (5): 0ms, A_FlexRay [4]: 0ms, Body-CAN (5): 0ms, Body-CAN [4]: 0ms, Body-CAN [1]: 0ms, FA-CAN (5): 0ms, FA-CAN [4]: 0ms, S-CAN (6): 0ms, S-CAN [5]: 0ms, Safety-CAN (2): 0ms
          length=2
          minimum-delay=0.1
          transmission-mode-true-timing={cyclic-timing=time-period={tolerance=absolute-tolerance=0.2, value=1}, event-controlled-timing={number-of-repetitions=2, repetition-period=0.16, "$(ET;3;160)Bei Auslösung der Nachricht durch dieses Ereignis muss aus Sicherheitsgründen die Versendung insgesamt 3-mal mit einem Wiederholzyklus von t=160 ms erfolgen (Details in der Spezifikation: Erweiterung der ereignisgesteuerten Auslösebedingungen)."}}
          unused-bit-pattern=255
          signal TEMP_EX: start 0, 8 bit, little-endian, base-type=uint8, invalid-value=value_255Dot0:255, compu-method=UI_8_noIniVal_noDflVal_255_0_50s_MI_40_noEnc_hasRng, data-constr=UI_8_noIniVal_noDflVal_255_0_50s_MI_40_noEnc_hasRng, to EPS  # Temperatur_Außen / temperature_exterior | LogicalInterface:BMW.INFRASTRUCTURE.VEHICLE.EnvironmentalInformation[external]@Infrastruktur; Hier wird die bearbeitete (= gefilterte) Außentemperatur allen anderen Busteilnehmern zur Verfügung gestellt. Für die Filterung im Stand wird der durch den Außentemperaturfühler ermittelte Wert mit der aktuellen Motortemperatur verrechnet, um daraus den bestmöglichen Wert zu ermitteln. Bei Fahrt wird die Filterzeitkonstante von der Geschwindigkeit abhängig gemacht. Alter Name: T_UMG. Dieses Signal hat ein Äquivalent auf dem SF-CAN. / The processed (= filtered) exterior temperature is made available to all other bus participants. For filtering in the standing vehicle the value determined by the exterior temperature sensor is set off against the current engine temperature in order to find the best possible value. When the vehicle is moving, the filter time constant is made dependent on the speed.
      frame CTR_VIB_STW_DISP_EXMI_SP2015_FDBK_VIB_STW_DISP_EXMI: to EPS, category=APPLICATION, frame-length=16, flexray-absolutely-scheduled-timing{communication-cycle=cycle-repetition={base-cycle=2, cycle-repetition=CYCLE-REPETITION-4}, slot-id=269}, allow-dynamic-l-sdu-length=false, payload-preamble-indicator=false  # Steuerung Vibration Lenkrad Anzeige Außenspiegel SP2015 / Rückmeldung Vibration Lenkrad Anzeige Außenspiegel
        pdu CTR_VIB_STW_DISP_EXMI_SP2015: length=8, minimum-delay=0.02, transmission-mode-true-timing={cyclic-timing=time-period={tolerance=absolute-tolerance=0.1, value=0.5}, event-controlled-timing=number-of-repetitions=0}, unused-bit-pattern=255  # Steuerung Vibration Lenkrad Anzeige Außenspiegel SP2015 / Steuerung Vibration Lenkrad Anzeige Aussenspiegel SP2015 | Ansteuerung der Vibrations-Aktuatorik im Lenkrad durch den Vibrationskoordinator und der Warnanzeige der Fahrspurwechsel-Warnfunktion in den Außenspiegeln. Diese Nachricht wird nur bei Fahrzeugen mit TLC oder HCx unterstützt. Diese Nachricht wird nur in Fahrzeugen ohne Integrated Chassis Management Quer-/Längsdynamik vom kamerabasierten Fahrerassistenzsystem versendet. Diese Nachricht ersetzt ab SP2015 die Nachrichten "Steuerung Vibration Lenkrad" und "Steuerung Anzeige Warnung Fahrspurwechsel".
          signal CTR_WARN_DIR_VIB_EPS: start 54, 2 bit, little-endian, base-type=uint8, invalid-value=value_3Dot0:3, compu-method=CTR_WARN_DIR_VIB_EPS, transfer-property=TRIGGERED-ON-CHANGE, to EPS  # Steuerung_Warnung_Richtung_Vibration_EPS / control_warning_direction_vibration_EPS | LogicalInterface:BMW.DASS.DRIVING.ControlDriverAssistanceSystemSteeringWheel[internal]@FASuS; Dieses Signal dient zur Übermittlung einer Richtungsangabe für die haptische Rückmeldung (z.B. Vibration) im Lenkrad.
          signal CTR_WARN_ILVL_VIB_EPS: start 56, 4 bit, little-endian, base-type=uint8, invalid-value=value_15Dot0:15, compu-method=CTR_WARN_ILVL_VIB_EPS, transfer-property=TRIGGERED-ON-CHANGE, to EPS  # Steuerung_Warnung_Intensitätsstufe_Vibration_EPS / control_warning_intensity-level_vibration_EPS | LogicalInterface:BMW.DASS.DRIVING.ControlDriverAssistanceSystemSteeringWheel[internal]@FASuS; Steuerung der Ansteuerstufe für die haptische Rückmeldung im Lenkrad (z.B. Vibration).
          signal CTR_WARN_PTRN_VIB_EPS: start 36, 4 bit, little-endian, base-type=uint8, invalid-value=value_15Dot0:15, compu-method=CTR_WARN_PTRN_VIB_EPS, transfer-property=TRIGGERED-ON-CHANGE, to EPS  # Steuerung_Warnung_Muster_Vibration_EPS / control_warning_pattern_vibration_EPS | LogicalInterface:BMW.DASS.DRIVING.ControlDriverAssistanceSystemSteeringWheel[internal]@FASuS; Dieses Signal dient dazu ein Vibrationsmuster in der Lenkung anzustoßen für die haptische Rückmeldung (z.B. Vibration).
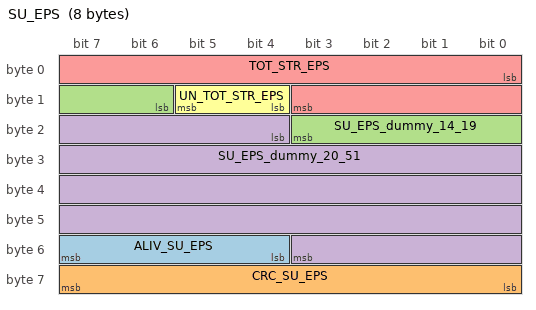
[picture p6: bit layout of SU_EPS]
      frame SU_EPS: from EPS, category=APPLICATION, frame-length=8, flexray-absolutely-scheduled-timing{communication-cycle=cycle-repetition={base-cycle=0, cycle-repetition=CYCLE-REPETITION-8}, slot-id=274}, allow-dynamic-l-sdu-length=false, payload-preamble-indicator=false  # Konfiguration EPS
        pdu SU_EPS:  # Konfiguration EPS | Diese Nachricht beinhaltet Informationen über die EPS Peripherie bzw. Konfiguration Für den Anfragemechanismus des Dienste Frames wurde der CAN-Identifier 1076 (dez.) vergeben.
          length=8
          minimum-delay=0.5
          transmission-mode-true-timing={cyclic-timing=time-period={tolerance=absolute-tolerance=1, value=5}, event-controlled-timing={number-of-repetitions=2, repetition-period=0.5, "$(ET;3;500)Ab Service Pack 2015 wird diese Nachricht zusätzlich zur der Versendung auf Anfrage nach dem Aufstarten des Sender Steuergeräts 3 Mal mit einer Wiederholrate von 500 ms geschickt."}}
          unused-bit-pattern=255
          signal ALIV_SU_EPS: start 52, 4 bit, little-endian, base-type=uint8, invalid-value=value_15Dot0:15, compu-method=ALIV_4_BIT_Unsigned_Integer, data-constr=ALIV_4_BIT_Unsigned_Integer  # Alive_Konfiguration_EPS / alive_setup_EPS | LogicalInterface:BMW.CHASSIS.STEERING.ElectricPowerSteering[internal]@Fahren; Standardabsicherung Alivezähler laut Definition per Lastenheft Allgemeine Bordnetzkommunikation.
          signal CRC_SU_EPS: start 56, 8 bit, little-endian, base-type=uint8, compu-method=CRC8, data-constr=CRC8  # CRC_Konfiguration_EPS / CRC_setup_EPS | LogicalInterface:BMW.CHASSIS.STEERING.ElectricPowerSteering[internal]@Fahren; Standardabsicherung Applikations-CRC laut Definition per Lastenheft Allgemeine Bordnetzkommunikation. Dieses Signal verwendet die Applikations-CRC-ID = 131 (dez.)
          signal SU_EPS_dummy_14_19: start 14, 6 bit, little-endian, init-value=63, base-type=uint8, compu-method=UINT6, data-constr=UINT6, transfer-property=PENDING
          signal SU_EPS_dummy_20_51: start 20, 32 bit, little-endian, init-value=4294967295, base-type=uint32, compu-method=UINT32, data-constr=UINT32, transfer-property=PENDING
          signal TOT_STR_EPS: start 0, 12 bit, little-endian, base-type=uint16, invalid-value=value_4095Dot0:4095, compu-method=TOT_STR_EPS, data-constr=TOT_STR_EPS  # Gesamt_Lenkübersetzung_EPS / total_steering-ratio_EPS | LogicalInterface:BMW.CHASSIS.STEERING.ElectricPowerSteering[internal]@Fahren; Definiert den Zahnstangenhub bzw. Ritzelwinkel, der einer ganzen EPS-Rotorumdrehung entspricht. Das Signal wird ohne Einheit übertragen. Die Einheit kann aus dem Signal "Einheit_Gesamt_Lenkübersetzung_EPS" entnommen werden. Im F25/L7 ist das Signal als Zahnstangenhub zu interpretieren. Die Einheit ist somit 0.2mm. Der Zahnstangenhub ist bei einer Bewegung der Zahnstange (aufs Fahrzeug bezogen) nach rechts positiv (entspricht einer Bewegung des Lenkrads aus seiner Nulllage entgegen des Uhrzeigersinns).
          signal UN_TOT_STR_EPS: start 12, 2 bit, little-endian, base-type=uint8, invalid-value=value_3Dot0:3, compu-method=UN_TOT_STR_EPS  # Einheit_Gesamt_Lenkübersetzung_EPS / unit-of-measurement_total_steering-ratio_EPS | LogicalInterface:BMW.CHASSIS.STEERING.ElectricPowerSteering[internal]@Fahren; Über dieses Signal wird übermittelt ob die EPS Gesamt-Lenkübersetzung als Zahnstangenhub oder Ritzelwinkel zu interpretieren ist.
          mapping sigGroup_SU_EPS: i-signal-group=sigGroup_SU_EPS
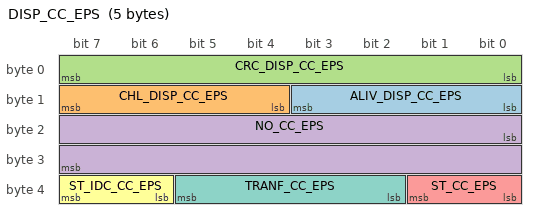
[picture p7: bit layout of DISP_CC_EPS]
      frame DISP_CC_EPS: from EPS, category=APPLICATION, frame-length=5, flexray-absolutely-scheduled-timing{communication-cycle=cycle-repetition={base-cycle=2, cycle-repetition=CYCLE-REPETITION-4}, slot-id=274}, allow-dynamic-l-sdu-length=false, payload-preamble-indicator=false  # Anzeige Checkcontrol EPS | Abgesicherte Checkcontrol Meldungen der EPS-Funktion an das Kombi Instrument. Um eine Alive-Überwachung des Sendersteuergeräts zu ermöglichen ist die Botschaft mit Alive-Zähler und CRC ausgestattet. Die Funktionsidentifikation "EPS" entspricht der Senderfunktion "Elektrische Lenkung Vorderachse". Soll eine CC Meldung auf dem zyklischen Kanal versendet werden, so wird die entsprechende CC ID als NO_CC_EPS, mit dem Wert "Setzen" als ST_CC_EPS und mit einer im Signal TRANF_CC_EPS festgelegten "Wiederholrate" in Sekunden versendet. Die folgenden Botschaften bis zum Ablauf der als "Wiederholrate" festgelegten Zeitspanne werden mit dem Wert "0xFFFE" als NO_CC_EPS und dem Wert "Rücksetzen" als ST_CC_EPS versendet.
        pdu DISP_CC_EPS: length=5, minimum-delay=0.06, transmission-mode-true-timing={cyclic-timing=time-period={tolerance=absolute-tolerance=0.064, value=0.32}, event-controlled-timing=number-of-repetitions=0}, unused-bit-pattern=255  # Anzeige Checkcontrol EPS
          signal ALIV_DISP_CC_EPS: start 8, 4 bit, little-endian, base-type=uint8, invalid-value=value_15Dot0:15, compu-method=ALIV_4_BIT_UInt, data-constr=ALIV_4_BIT_UInt, transfer-property=TRIGGERED-ON-CHANGE  # Alive_Anzeige_Checkcontrol_EPS / alive_display_check-control_EPS | LogicalInterface:BMW.INFOTAINMENT.DISPLAY.DisplayCheckControl[external]@IuK; Standardabsicherung Alivezähler laut Definition per Lastenheft Allgemeine Bordnetzkommunikation
          signal CHL_DISP_CC_EPS: start 12, 4 bit, little-endian, base-type=uint8, invalid-value=value_15Dot0:15, compu-method=CHL_4_UInt, data-constr=CHL_4_UInt, transfer-property=TRIGGERED-ON-CHANGE  # CHL_Anzeige_Checkcontrol_EPS / CHL_display_check-control_EPS | LogicalInterface:BMW.INFOTAINMENT.DISPLAY.DisplayCheckControl[external]@IuK; Dieses Signal beinhaltet explizit den Wert der Erweiterungs-ID = 12 (dez) = C (hex) für den erweiterten Standardabsicherungs-Applikations-CRC und entspricht Bit 12-15 der Applikations-Data-ID (CRC-ID) des zughörigen CRC-Signals. Dieses Signal liegt im Bereich der für die Berechnung des CRC-Signales verwendet wird und muss empfängerseitig im Rahmen der CRC-Prüfung auf korrekte Befüllung geprüft werden. Nur wenn der Wert des Signales dem Sollwert entspricht ist und die Überprüfung des CRC-Signals positiv verläuft kann davon ausgegangen werden, dass die erwartete PDU fehlerfrei empfangen wurde. Das Signal kann den Wert 0 nicht annehmen um eine klare Differenzierung der 1A E2E-Protection (Autosar SWS 428) Anwendungsprofile 1A und 1C zu ermöglichen.
          signal CRC_DISP_CC_EPS: start 0, 8 bit, little-endian, base-type=uint8, compu-method=CRC8, data-constr=CRC8, transfer-property=TRIGGERED-ON-CHANGE  # CRC_Anzeige_Checkcontrol_EPS / CRC_display_check-control_EPS | LogicalInterface:BMW.INFOTAINMENT.DISPLAY.DisplayCheckControl[external]@IuK; Anwendungsprofil 1C E2E-Protection (Autosar SWS 428). Das Signal verwendet die Applikations-Data-ID (12 Bit) 3148(dez) = C4C (hex). Die Applikations-CRC-ID besteht aus zwei Teilen: 1.) Bit 0-7: 76 (dez) = 4C (hex). Dieser Wert wird nur als Startwert für die CRC8-Berechnung verwendet. (Vergleiche Anwendungsprofil 1A E2E-Protection (Autosar SWS 428)) 2.) Bit 12-15: 12 (dez) = C (hex). Dieser Wert wird NICHT für die CRC8-Berechnung verwendet sondern als explizit übertragene Erweiterungs-ID zur Unterscheidung der CRC-abgesicherten PDUs. Dieser Teil der Applikations-Data-ID geht also nicht in das CRC-Signal ein sondern wird als Wert des Signales CHL_Anzeige_checkcontrol_EPS verwendet.
          signal NO_CC_EPS: start 16, 16 bit, little-endian, base-type=uint16, invalid-value=value_65535Dot0:65535, compu-method=NO_CC_EPS, data-constr=NO_CC_EPS, transfer-property=TRIGGERED-ON-CHANGE  # Nummer_Checkcontrol_EPS / number_check-control_EPS | LogicalInterface:BMW.INFOTAINMENT.DISPLAY.DisplayCheckControl[external]@IuK; Das Signal enthält die Nummer der Meldung, welche die Checkcontrol anzeigen oder löschen soll. Diese Nummer ist eindeutig im gesamten System und somit nicht abhängig von dem Steuergerät in dem die entsprechende Funktionalität realisiert wurde.
          signal ST_CC_EPS: start 32, 2 bit, little-endian, base-type=uint8, invalid-value=value_3Dot0:3, compu-method=ST_CC_EPS, transfer-property=TRIGGERED-ON-CHANGE  # Status_Checkcontrol_EPS / status_check-control_EPS | LogicalInterface:BMW.INFOTAINMENT.DISPLAY.DisplayCheckControl[external]@IuK; Hier wird festgelegt, ob die Meldung gesetzt oder gelöscht werden soll.
          signal ST_IDC_CC_EPS: start 38, 2 bit, little-endian, base-type=uint8, invalid-value=value_3Dot0:3, compu-method=ST_IDC_CC_EPS, transfer-property=TRIGGERED-ON-CHANGE  # Status_Blinken_Checkcontrol_EPS / status_indicate-direction_check-control_EPS | LogicalInterface:BMW.INFOTAINMENT.DISPLAY.DisplayCheckControl[external]@IuK; Hier wird angegeben mit welcher Frequenz eine durch diese Nachricht angesteuerte Hardware-Kontrolleuchte blinken soll. Die Blinkfrequenzen für langsames und schnelles Blinken sind codierbar.
          signal TRANF_CC_EPS: start 34, 4 bit, little-endian, base-type=uint8, invalid-value=value_15Dot0:15, compu-method=TRANF_CC_EPS, data-constr=TRANF_CC_EPS, transfer-property=TRIGGERED-ON-CHANGE  # Sendeart_Checkcontrol_EPS / transmitting-form_check-control_EPS | LogicalInterface:BMW.INFOTAINMENT.DISPLAY.DisplayCheckControl[external]@IuK; Dieses Signal gibt an, wie der Sender die Anzeigenachricht für die Checkcontrol-Meldung überträgt. Die Anzeigenachricht muß immer wieder zyklisch übertragen werden, solange die Meldung aktiv ist und angezeigt werden soll.
          mapping sigGroup_DISP_CC_EPS: i-signal-group=sigGroup_DISP_CC_EPS
      frame FZZSTD: to EPS, category=APPLICATION, frame-length=8, flexray-absolutely-scheduled-timing{communication-cycle=cycle-repetition={base-cycle=1, cycle-repetition=CYCLE-REPETITION-8}, slot-id=275}, allow-dynamic-l-sdu-length=false, payload-preamble-indicator=false  # Fahrzeugzustand
        pdu FZZSTD:  # Fahrzeugzustand
          length=8
          minimum-delay=0.1
          transmission-mode-true-timing={cyclic-timing=time-period={tolerance=absolute-tolerance=1, value=5}, event-controlled-timing={number-of-repetitions=0, "Diese Auslösebedingung gilt ab SP2015. Die Nachricht wird bei jeder Signaländerung einmalig versandt. Die Botschaft wird beim Teilnetzwechsel dreimalig im Abstand der minimalen Entprellzeit versendet."}}
          unused-bit-pattern=255
          signal ST_ENERG_FZM: start 16, 4 bit, little-endian, base-type=uint8, invalid-value=value_15Dot0:15, compu-method=ST_ENERG_FZM, transfer-property=TRIGGERED-ON-CHANGE, to EPS  # Status_Energie_FZM / status_Energy_FZM | LogicalInterface:BMW.INFRASTRUCTURE.VEHICLE.VehicleCondition[external]@Infrastruktur; Dieses Signal hat ein Äquivalent auf dem SF-CAN. Der Inhalt dieses Signals wird eins zu eins aus dem Signal "Status_Energie_Powermanagement" der Nachricht "Powermanagement Verbrauchersteuerung" übernommen. Wenn ein Ladezustand aufgrund ungünstiger Umgebungsbedingungen nicht ermittelt werden kann, wird der Ungültigkeitswert versendet. Dieser Zustand ist über mehrere Fahrzyklen zulässig und darf nicht zu Fehlerspeichern in empfangenden Komponenten führen.
          signal ST_ILK_ERRM_FZM: start 56, 2 bit, little-endian, base-type=uint8, invalid-value=value_3Dot0:3, compu-method=ST_ILK_ERRM_FZM, transfer-property=TRIGGERED-ON-CHANGE, to EPS  # Status_Sperre_Fehlerspeicher_FZM / status_interlock_error-memory_FZM | LogicalInterface:BMW.INFRASTRUCTURE.VEHICLE.VehicleCondition[external]@Infrastruktur; Dieses Signal hat ein Äquivalent auf dem SF-CAN.
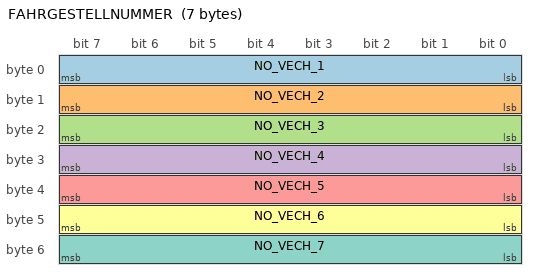
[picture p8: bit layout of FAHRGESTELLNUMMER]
      frame FAHRGESTELLNUMMER: to EPS, category=APPLICATION, frame-length=7, flexray-absolutely-scheduled-timing{communication-cycle=cycle-repetition={base-cycle=7, cycle-repetition=CYCLE-REPETITION-8}, slot-id=275}, allow-dynamic-l-sdu-length=false, payload-preamble-indicator=false  # Fahrgestellnummer / Chassis number
        pdu FAHRGESTELLNUMMER: length=7, minimum-delay=0.1, transmission-mode-true-timing=event-controlled-timing={number-of-repetitions=2, repetition-period=0.16, "$(ET;3;160)Bei Auslösen der Nachricht muss die Versendung insgesamt 3-mal mit einem Wiederholzyklus von t=160 ms erfolgen (Details in der Spezifikation: Erweiterung der ereignisgesteuerten Auslösebedingungen)."}, unused-bit-pattern=255  # Fahrgestellnummer / Chassis number | $(AUTOSAR; SIGNALGROUP) Diese Nachricht enthält die letzten sieben Stellen der Fahrgestellnummer, jede Stelle einzeln innerhalb eines 8-Bit-Signals in ASCII-Zeichen codiert. Beispiel: Fahrgestellnummer: WBAGL41000HB01108 (die letzten sieben Stellen: HB01108) Signal Nummer_Fahrgestell_1: H (siebtletzte Stelle der Fahrgestellnummer) Signal Nummer_Fahrgestell_2: B (sechstletzte Stelle der Fahrgestellnummer) ... Signal Nummer_Fahrgestell_6: 0 (vorletzte Stelle der Fahrgestellnummer) Signal Nummer_Fahrgestell_7: 8 (letzte Stelle der Fahrgestellnummer)
          signal NO_VECH_1: start 0, 8 bit, opaque, base-type=ascii8, invalid-value=value_255Dot0:255, compu-method=NO_VECH_1, transfer-property=TRIGGERED-ON-CHANGE, to EPS  # Nummer_Fahrgestell_1 / number_vehicle-chassis_1 | LogicalInterface:BMW.INFRASTRUCTURE.VEHICLE.VehicleInformation[external]@Infrastruktur; Dieses Signal enthält die siebtletzte Stelle der Fahrgestellnummer. (Die einzelnen Stellen sind in ASCII-Zeichen codiert.) Bit 0: LSB, Bit 7: MSB Transp.MOST-GW-Migration, 01.09.2006: Zusammenführung des Parameters ChassisNumber1 [1] mit dem Signal Nummer_Fahrgestell_1 [1]. / This signal contains the seventh last digit of the chassis number. (The individual digits are coded in ASCII characters.) Bit 0: LSB, Bit 7: MSB
          signal NO_VECH_2: start 8, 8 bit, opaque, base-type=ascii8, invalid-value=value_255Dot0:255, compu-method=NO_VECH_2, transfer-property=TRIGGERED-ON-CHANGE, to EPS  # Nummer_Fahrgestell_2 / number_vehicle-chassis_2 | LogicalInterface:BMW.INFRASTRUCTURE.VEHICLE.VehicleInformation[external]@Infrastruktur; Dieses Signal enthält die sechstletzte Stelle der Fahrgestellnummer. (Die einzelnen Stellen sind in ASCII-Zeichen codiert.) Bit 0: LSB, Bit 7: MSB Transp.MOST-GW-Migration, 01.09.2006: Zusammenführung des Parameters ChassisNumber2 [1] mit dem Signal Nummer_Fahrgestell_2 [1]. / This signal contains the sixth last digit of the chassis number. (The individual digits are coded in ASCII characters.) Bit 0: LSB, Bit 7: MSB
          signal NO_VECH_3: start 16, 8 bit, opaque, base-type=ascii8, invalid-value=value_255Dot0:255, compu-method=NO_VECH_3, transfer-property=TRIGGERED-ON-CHANGE, to EPS  # Nummer_Fahrgestell_3 / number_vehicle-chassis_3 | LogicalInterface:BMW.INFRASTRUCTURE.VEHICLE.VehicleInformation[external]@Infrastruktur; Dieses Signal enthält die fünftletzte Stelle der Fahrgestellnummer. (Die einzelnen Stellen sind in ASCII-Zeichen codiert.) Bit 0: LSB, Bit 7: MSB Transp.MOST-GW-Migration, 01.09.2006: Zusammenführung des Parameters ChassisNumber3 [1] mit dem Signal Nummer_Fahrgestell_3 [1]. / This signal contains the fifth last digit of the chassis number. (The individual digits are coded in ASCII characters.) Bit 0: LSB, Bit 7: MSB
          signal NO_VECH_4: start 24, 8 bit, opaque, base-type=ascii8, invalid-value=value_255Dot0:255, compu-method=NO_VECH_4, transfer-property=TRIGGERED-ON-CHANGE, to EPS  # Nummer_Fahrgestell_4 / number_vehicle-chassis_4 | LogicalInterface:BMW.INFRASTRUCTURE.VEHICLE.VehicleInformation[external]@Infrastruktur; Dieses Signal enthält die viertletzte Stelle der Fahrgestellnummer. (Die einzelnen Stellen sind in ASCII-Zeichen codiert.) Bit 0: LSB, Bit 7: MSB Transp.MOST-GW-Migration, 01.09.2006: Zusammenführung des Parameters ChassisNumber4 [1] mit dem Signal Nummer_Fahrgestell_4 [1]. / This signal contains the fourth last digit of the chassis number. (The individual digits are coded in ASCII characters.) Bit 0: LSB, Bit 7: MSB
          signal NO_VECH_5: start 32, 8 bit, opaque, base-type=ascii8, invalid-value=value_255Dot0:255, compu-method=NO_VECH_5, transfer-property=TRIGGERED-ON-CHANGE, to EPS  # Nummer_Fahrgestell_5 / number_vehicle-chassis_5 | LogicalInterface:BMW.INFRASTRUCTURE.VEHICLE.VehicleInformation[external]@Infrastruktur; Dieses Signal enthält die drittletzte Stelle der Fahrgestellnummer. (Die einzelnen Stellen sind in ASCII-Zeichen codiert.) Bit 0: LSB, Bit 7: MSB Transp.MOST-GW-Migration, 01.09.2006: Zusammenführung des Parameters ChassisNumber5 [1] mit dem Signal Nummer_Fahrgestell_5 [1]. / This signal contains the third last digit of the chassis number. (The individual digits are coded in ASCII characters.) Bit 0: LSB, Bit 7: MSB
          signal NO_VECH_6: start 40, 8 bit, opaque, base-type=ascii8, invalid-value=value_255Dot0:255, compu-method=NO_VECH_6, transfer-property=TRIGGERED-ON-CHANGE, to EPS  # Nummer_Fahrgestell_6 / number_vehicle-chassis_6 | LogicalInterface:BMW.INFRASTRUCTURE.VEHICLE.VehicleInformation[external]@Infrastruktur; Dieses Signal enthält die vorletzte Stelle der Fahrgestellnummer. (Die einzelnen Stellen sind in ASCII-Zeichen codiert.) Bit 0: LSB, Bit 7: MSB Transp.MOST-GW-Migration, 01.09.2006: Zusammenführung des Parameters ChassisNumber6 [1] mit dem Signal Nummer_Fahrgestell_6 [1]. / This signal contains the last but one digit of the chassis number. (The individual digits are coded in ASCII characters.) Bit 0: LSB, Bit 7: MSB
          signal NO_VECH_7: start 48, 8 bit, opaque, base-type=ascii8, invalid-value=value_255Dot0:255, compu-method=NO_VECH_7, transfer-property=TRIGGERED-ON-CHANGE, to EPS  # Nummer_Fahrgestell_7 / number_vehicle-chassis_7 | LogicalInterface:BMW.INFRASTRUCTURE.VEHICLE.VehicleInformation[external]@Infrastruktur; Dieses Signal enthält die letzte Stelle der Fahrgestellnummer. (Die einzelnen Stellen sind in ASCII-Zeichen codiert.) Bit 0: LSB, Bit 7: MSB Transp.MOST-GW-Migration, 01.09.2006: Zusammenführung des Parameters ChassisNumber7 [1] mit dem Signal Nummer_Fahrgestell_7 [4]. / This signal contains the last digit of the chassis number. (The individual digits are coded in ASCII characters.) Bit 0: LSB, Bit 7: MSB
      frame RELATIVZEIT: to EPS, category=APPLICATION, frame-length=6, flexray-absolutely-scheduled-timing{communication-cycle=cycle-repetition={base-cycle=2, cycle-repetition=CYCLE-REPETITION-8}, slot-id=276}, allow-dynamic-l-sdu-length=false, payload-preamble-indicator=false  # Relativzeit BN2020
        pdu RELATIVZEIT:  # Relativzeit BN2020 | Dieses Frame hat im BN2020 keine Timeoutüberwachung im ZGW.
          length=6
          minimum-delay=0.2
          transmission-mode-true-timing={cyclic-timing={time-period={tolerance=absolute-tolerance=0.2, value=1}, "Die Versendung der Nachricht erfolgt - bei aktivem Bus - zyklisch im Sekundenraster. Das Versenden der Relativzeit soll zukünftig für die Ermöglichung einer Zeitsynchronisation applikationsgesteuert genau beim Umspringen der Sekunde erfolgen."}, event-controlled-timing={number-of-repetitions=0, "Eine optionale Versendung, die sicherstellen soll, dass die Nachricht zeitsynchron mit dem Sekundenwechsel versendet wird. Die 1s-Zykluszeit wird entweder durch die ereignisgesteuerte Versendung oder durch die zyklische Versendung sichergestellt. Die beiden Sendearten werden nicht parallel benutzt. Zusätzlich wird die Nachricht bei jedem Klemmenwechsel versandt, allerdings erfolgt keine Versendung bei einem Wechsel von bzw. nach KL50."}}
          unused-bit-pattern=255
          signal T_SEC_COU_REL: start 0, 32 bit, little-endian, base-type=uint32, invalid-value=value_4Dot294967295E9:4294967295, compu-method=UI_32_noIniVal_noDflVal_4294967295_1_0_noEnc_hasRng, data-constr=UI_32_noIniVal_noDflVal_4294967295_1_0_noEnc_hasRng, to EPS  # Zeit_Sekunde_Zähler_Relativ / time_second_counter_relative | LogicalInterface:BMW.INFRASTRUCTURE.VEHICLE.VehicleInformation[external]@Infrastruktur; Dieser Zähler zählt synchron zur System- / Borduhr die Sekunden. ------------------------------------------------------------------------------------------------------------------------ Ab PL6 gilt (Senderfunktion "DM_Zeitmaster_Master"): Dieses Signal / dieser Parameter gibt die Zeit in Sekunden seit dem Start der Systemzeit (erfolgt typisch im Werk) wieder. Dazu wird bei der Initialisierung des Zeitmaster der Wert dieses Signals/Parameters auf die Zeit seit dem Start der Systemzeit in Sekunden gesetzt. Diese Zeit stellt einen streng fortlaufenden Sekundenzähler dar. Der Sender des Signals/Parameters legt zyklisch mit der Zykluszeit Backupintervall einen Backupwert im nichtflüchtigen Speicher ab. Nach Reset (z.B. Abklemmen der Batterie in der Werkstatt) wird der letzte Backupwert des Sekundenzählers plus die Dauer des Backupintervalls als neue Zeitbasis für den Zähler verwendet. Durch die Addition der Dauer des Backupintervalls ist sichergestellt, dass der Zähler auch nach einem Reset einen grösseren Wert hat wie der letzte Wert vor dem Reset. Mit diesem Signal/Parameter können Ereignisse im Fahrzeug (z.B. Fehlerspeichereinträge) in zeitliche Relation gebracht werden. Bei der Messung von relativen Zeiten mittels dieses Signals/Parameters muss darauf geachtet werden, dass der Wert des Zählers nach einem Reset einen Sprung machen kann. ------------------------------------------------------------------------------------------------------------------------ Für L6-Vorgängerbaureihen mit BN2000 gilt (Senderfunktion "Uhr"): Das Signal/der Parameter zählt im Sekundenraster von 0 bis über 4 Milliarden - entspricht ca. 140 Jahren. Der Zähler läuft nach Reset (z.B. Abklemmen der Batterie in der Werkstatt) von 0 los. Mit diesem Signal können relative Zeiten gemessen werden. Die Uhrzeit kann zu diesem Zweck nicht verwendet werden, da diese vom Kunden durch Stellen verändert werden kann. Eine Alive-Überwachung des Kombiinstruments kann mittels der Änderung des relativen Minutenzählers erfolgen. Alter Name: REL_ZEIT. Dieses Signal hat ein E72-Hybrid-Äquivalent (gleiche Signalklasse). Siehe HIM-Mapping-Tabelle. Dieses Signal hat ein Äquivalent auf dem SF-CAN. / This counter counts the seconds synchronously to the system / on-board clock. The signal counts in second raster from 0 to more than 4 billion - corresponds to approx. 140 years. The counter starts at 0 after being reset (e.g. disconnection of the battery in the workshop). With this signal relative times can be measured. The clock cannot be used for this purpose as it can be changed by the customer through adjustments. An alive monitoring of the instrument pack can be made by means of changing the relative minute counter.
      frame KILOMETERSTAND: to EPS, category=APPLICATION, frame-length=8, flexray-absolutely-scheduled-timing{communication-cycle=cycle-repetition={base-cycle=4, cycle-repetition=CYCLE-REPETITION-8}, slot-id=276}, allow-dynamic-l-sdu-length=false, payload-preamble-indicator=false  # Kilometerstand/Reichweite / Mileage/range
        pdu KILOMETERSTAND:  # Kilometerstand/Reichweite / Mileage/range | Timeout-Migration am 5. Mai 2006: Timeout-vereinheitlicht auf 30000 ms Damit wurden folgende Cluster-spezifisch abweichend vergebenen Werte geändert: Motor-CAN (4): 0ms, Motor-CAN [3]: 0ms, Motor-CAN [2]: 0ms, Motor-CAN [1]: 0ms, Body-CAN (5): 0ms, Body-CAN [4]: 0ms, Body-CAN [3]: 0ms, Body-CAN [2]: 0ms, Body-CAN [1]: 0ms, DME-CAN_L6_KSP2 [1]: 0ms, FA-CAN (5): 0ms, FA-CAN [4]: 0ms, FA-CAN [3]: 0ms, FA-CAN [2]: 0ms, FA-CAN [1]: 0ms, FAS-CAN [5]: 0ms, FAS_CAN_L6_KSP [1]: 0ms, FA_CAN_L6_KSP2 [1]: 0ms, I-CAN [3]: 0ms, I-CAN [2]: 0ms, I-FlexRay [1]: 0ms, PT-CAN (37): 0ms, PT-CAN [36]: 0ms, PT-CAN [35]: 0ms, PT-CAN [34]: 0ms, PT-CAN [33]: 0ms, PT-CAN [32]: 0ms, PT-CAN [31]: 0ms, PT-CAN [30]: 0ms, PT-CAN [29]: 0ms, PT-CAN [28]: 0ms, PT-CAN [27]: 0ms, PT-CAN [26]: 0ms, PT-CAN [25]: 0ms, PT-CAN [24]: 0ms, PT-CAN [23]: 0ms, PT_CAN_L6_KSP1 [1]: 0ms, S-CAN [4]: 0ms, S-CAN [3]: 0ms, S-CAN [2]: 0ms, S-CAN [1]: 0ms, Safety-CAN (2): 0ms
          length=8
          minimum-delay=0.2
          transmission-mode-true-timing={cyclic-timing={time-period={tolerance=absolute-tolerance=2, value=10}, "Weiters erfolgt die Versendung zyklisch mit einer großen Periode (Bus aktiv). / The message is also sent cyclically with a large period when the bus is active."}, event-controlled-timing={number-of-repetitions=0, "Die Nachricht wird - ab Bus aktiv - bei jeder Signaländerung versandt. Um eine Versendung auszulösen, müssen sich die Inhalte der Signale Wegstrecke_Kilometer bzw. Reichweite um mindestens 2 Kilometer von der letzten verschickten Nachricht unterscheiden. / When the bus is active the message is sent at each change of the signal contents. Concerning the signal 'mileage_kilometer' it it defined that the new content of the signal has to be at least 2 kilometers greater than the last message that was sent."}}
          unused-bit-pattern=255
          signal MILE_KM: start 0, 24 bit, little-endian, base-type=uint32, invalid-value=value_1Dot6777215E7:16777215, compu-method=MILE_KM, data-constr=MILE_KM, transfer-property=TRIGGERED-ON-CHANGE, to EPS  # Wegstrecke_Kilometer / mileage_kilometre | LogicalInterface:BMW.INFRASTRUCTURE.VEHICLE.VehicleInformation[external]@Infrastruktur; Hier wird der Anzeigewert des Gesamtwegstreckenzählers anderen Teilnehmern zur Verfügung gestellt. Dieses Signal hat ein Äquivalent auf dem SF-CAN. / Here the display value of the entire mileage counter is made available for other participants.
      frame xcpdynamic254_1: from EPS, category=XCP_RUNTIME_CONFIGURED, frame-length=254, flexray-absolutely-scheduled-timing{communication-cycle=cycle-repetition={base-cycle=0, cycle-repetition=CYCLE-REPETITION-1}, slot-id=294}, allow-dynamic-l-sdu-length=false, payload-preamble-indicator=false  # XCP-Bereich dynamic 254 Bytes 1 | XCP-Frame (Runtime-Configured) für die Kommunikation zwischen Master und Slaves. Maximal zulässige Größe ist 254 Bytes. Wichtig: Die FIBEX-Framegröße stellt keine Spezifikation dar sondern bildet lediglich die protokolltechnisch maximal erlaubte Größe. Die Framegröße muss durch den Anwender im a2l-File festgelegt werden. Dabei muss auch die ECU-spezifische Controllerkonfiguration beachtet werden. Sende-/Empfangsbeziehungen im FIBEX dürfen nicht ausgewertet werden und sind ebenfalls keine verbindliche Spezifikation.
        general purpose i pdu xcpdynamic254_1: category=XCP, length=254  # XCP-Bereich dynamic 254 Bytes 1 | Die PDU (254 Byte lang) hat ebenso keine inhaltliche Verbindlichkeit.
      frame xcpdynamic254_2: from EPS, category=XCP_RUNTIME_CONFIGURED, frame-length=254, flexray-absolutely-scheduled-timing{communication-cycle=cycle-repetition={base-cycle=0, cycle-repetition=CYCLE-REPETITION-1}, slot-id=295}, allow-dynamic-l-sdu-length=false, payload-preamble-indicator=false  # XCP-Bereich dynamic 254 Bytes 2 | XCP-Frame (Runtime-Configured) für die Kommunikation zwischen Master und Slaves. Maximal zulässige Größe ist 254 Bytes. Wichtig: Die FIBEX-Framegröße stellt keine Spezifikation dar sondern bildet lediglich die protokolltechnisch maximal erlaubte Größe. Die Framegröße muss durch den Anwender im a2l-File festgelegt werden. Dabei muss auch die ECU-spezifische Controllerkonfiguration beachtet werden. Sende-/Empfangsbeziehungen im FIBEX dürfen nicht ausgewertet werden und sind ebenfalls keine verbindliche Spezifikation.
        general purpose i pdu xcpdynamic254_2: category=XCP, length=254  # XCP-Bereich dynamic 254 Bytes 2 | Die PDU (254 Byte lang) hat ebenso keine inhaltliche Verbindlichkeit.
      frame xcpdynamic254_3: from EPS, category=XCP_RUNTIME_CONFIGURED, frame-length=254, flexray-absolutely-scheduled-timing{communication-cycle=cycle-repetition={base-cycle=0, cycle-repetition=CYCLE-REPETITION-1}, slot-id=296}, allow-dynamic-l-sdu-length=false, payload-preamble-indicator=false  # XCP-Bereich dynamic 254 Bytes 3 | XCP-Frame (Runtime-Configured) für die Kommunikation zwischen Master und Slaves. Maximal zulässige Größe ist 254 Bytes. Wichtig: Die FIBEX-Framegröße stellt keine Spezifikation dar sondern bildet lediglich die protokolltechnisch maximal erlaubte Größe. Die Framegröße muss durch den Anwender im a2l-File festgelegt werden. Dabei muss auch die ECU-spezifische Controllerkonfiguration beachtet werden. Sende-/Empfangsbeziehungen im FIBEX dürfen nicht ausgewertet werden und sind ebenfalls keine verbindliche Spezifikation.
        general purpose i pdu xcpdynamic254_3: category=XCP, length=254  # XCP-Bereich dynamic 254 Bytes 3 | Die PDU (254 Byte lang) hat ebenso keine inhaltliche Verbindlichkeit.
      frame xcpdynamic254_4: from EPS, category=XCP_RUNTIME_CONFIGURED, frame-length=254, flexray-absolutely-scheduled-timing{communication-cycle=cycle-repetition={base-cycle=0, cycle-repetition=CYCLE-REPETITION-1}, slot-id=297}, allow-dynamic-l-sdu-length=false, payload-preamble-indicator=false  # XCP-Bereich dynamic 254 Bytes 4 | XCP-Frame (Runtime-Configured) für die Kommunikation zwischen Master und Slaves. Maximal zulässige Größe ist 254 Bytes. Wichtig: Die FIBEX-Framegröße stellt keine Spezifikation dar sondern bildet lediglich die protokolltechnisch maximal erlaubte Größe. Die Framegröße muss durch den Anwender im a2l-File festgelegt werden. Dabei muss auch die ECU-spezifische Controllerkonfiguration beachtet werden. Sende-/Empfangsbeziehungen im FIBEX dürfen nicht ausgewertet werden und sind ebenfalls keine verbindliche Spezifikation.
        general purpose i pdu xcpdynamic254_4: category=XCP, length=254  # XCP-Bereich dynamic 254 Bytes 4 | Die PDU (254 Byte lang) hat ebenso keine inhaltliche Verbindlichkeit.
      frame xcpdynamic254_5: from EPS, category=XCP_RUNTIME_CONFIGURED, frame-length=254, flexray-absolutely-scheduled-timing{communication-cycle=cycle-repetition={base-cycle=0, cycle-repetition=CYCLE-REPETITION-1}, slot-id=298}, allow-dynamic-l-sdu-length=false, payload-preamble-indicator=false  # XCP-Bereich dynamic 254 Bytes 5 | XCP-Frame (Runtime-Configured) für die Kommunikation zwischen Master und Slaves. Maximal zulässige Größe ist 254 Bytes. Wichtig: Die FIBEX-Framegröße stellt keine Spezifikation dar sondern bildet lediglich die protokolltechnisch maximal erlaubte Größe. Die Framegröße muss durch den Anwender im a2l-File festgelegt werden. Dabei muss auch die ECU-spezifische Controllerkonfiguration beachtet werden. Sende-/Empfangsbeziehungen im FIBEX dürfen nicht ausgewertet werden und sind ebenfalls keine verbindliche Spezifikation.
        general purpose i pdu xcpdynamic254_5: category=XCP, length=254  # XCP-Bereich dynamic 254 Bytes 5 | Die PDU (254 Byte lang) hat ebenso keine inhaltliche Verbindlichkeit.
      frame xcpdynamic254_6: from EPS, category=XCP_RUNTIME_CONFIGURED, frame-length=254, flexray-absolutely-scheduled-timing{communication-cycle=cycle-repetition={base-cycle=0, cycle-repetition=CYCLE-REPETITION-1}, slot-id=299}, allow-dynamic-l-sdu-length=false, payload-preamble-indicator=false  # XCP-Bereich dynamic 254 Bytes 6 | XCP-Frame (Runtime-Configured) für die Kommunikation zwischen Master und Slaves. Maximal zulässige Größe ist 254 Bytes. Wichtig: Die FIBEX-Framegröße stellt keine Spezifikation dar sondern bildet lediglich die protokolltechnisch maximal erlaubte Größe. Die Framegröße muss durch den Anwender im a2l-File festgelegt werden. Dabei muss auch die ECU-spezifische Controllerkonfiguration beachtet werden. Sende-/Empfangsbeziehungen im FIBEX dürfen nicht ausgewertet werden und sind ebenfalls keine verbindliche Spezifikation.
        general purpose i pdu xcpdynamic254_6: category=XCP, length=254  # XCP-Bereich dynamic 254 Bytes 6 | Die PDU (254 Byte lang) hat ebenso keine inhaltliche Verbindlichkeit.
      frame xcpdynamic254_7: from EPS, category=XCP_RUNTIME_CONFIGURED, frame-length=254, flexray-absolutely-scheduled-timing{communication-cycle=cycle-repetition={base-cycle=0, cycle-repetition=CYCLE-REPETITION-1}, slot-id=300}, allow-dynamic-l-sdu-length=false, payload-preamble-indicator=false  # XCP-Bereich dynamic 254 Bytes 7 | XCP-Frame (Runtime-Configured) für die Kommunikation zwischen Master und Slaves. Maximal zulässige Größe ist 254 Bytes. Wichtig: Die FIBEX-Framegröße stellt keine Spezifikation dar sondern bildet lediglich die protokolltechnisch maximal erlaubte Größe. Die Framegröße muss durch den Anwender im a2l-File festgelegt werden. Dabei muss auch die ECU-spezifische Controllerkonfiguration beachtet werden. Sende-/Empfangsbeziehungen im FIBEX dürfen nicht ausgewertet werden und sind ebenfalls keine verbindliche Spezifikation.
        general purpose i pdu xcpdynamic254_7: category=XCP, length=254  # XCP-Bereich dynamic 254 Bytes 7 | Die PDU (254 Byte lang) hat ebenso keine inhaltliche Verbindlichkeit.
      frame xcpdynamic254_8: from EPS, category=XCP_RUNTIME_CONFIGURED, frame-length=254, flexray-absolutely-scheduled-timing{communication-cycle=cycle-repetition={base-cycle=0, cycle-repetition=CYCLE-REPETITION-1}, slot-id=301}, allow-dynamic-l-sdu-length=false, payload-preamble-indicator=false  # XCP-Bereich dynamic 254 Bytes 8 | XCP-Frame (Runtime-Configured) für die Kommunikation zwischen Master und Slaves. Maximal zulässige Größe ist 254 Bytes. Wichtig: Die FIBEX-Framegröße stellt keine Spezifikation dar sondern bildet lediglich die protokolltechnisch maximal erlaubte Größe. Die Framegröße muss durch den Anwender im a2l-File festgelegt werden. Dabei muss auch die ECU-spezifische Controllerkonfiguration beachtet werden. Sende-/Empfangsbeziehungen im FIBEX dürfen nicht ausgewertet werden und sind ebenfalls keine verbindliche Spezifikation.
        general purpose i pdu xcpdynamic254_8: category=XCP, length=254  # XCP-Bereich dynamic 254 Bytes 8 | Die PDU (254 Byte lang) hat ebenso keine inhaltliche Verbindlichkeit.
      frame FR_DBG_EPS: from EPS, category=APPLICATION, frame-length=58, flexray-absolutely-scheduled-timing{communication-cycle=cycle-repetition={base-cycle=0, cycle-repetition=CYCLE-REPETITION-1}, slot-id=315}, allow-dynamic-l-sdu-length=false, payload-preamble-indicator=false  # FlexRay Debug EPS | Dieser Frame enthält nur Debugging-Informationen, die ausschließlich während der Entwicklungszeit übertragen werden dürfen. Kein Serienumfang! Der Frame darf nicht für andere Zwecke als Debugging verwendet werden. Für Messzweck ist ausschließlich XCP zu verwenden. Jedes FlexRay Steuergerät ist einen Debug-Frame zugewiesen. Falls kein Bedarf vorhanden, soll dieser Debug-Frame nicht gesendet werden. Das Senden der Frame soll über ein Codierschalter abschaltbar sein. Der Codierschalter sollte wie folgt definiert werden: C_DebugFrame_FR Die in dieser Frame enthaltene Signale dürfen von den Fachstellen geändert werden. Die hier vorgegebene maximale Länge und Zykluszeit gilt für den Basis-Modus (z.B. FIT Fahrzeug oder SA909). Der Basis-Modus darf ohne Abstimmung nicht erweitert werden (dient zur Sicherstellung der Bandbreite im FIT-Fahrzeuge). Falls die Notwendigkeit besteht mehr Daten schneller zu senden, darf dies in einem Extended-Modus stattfinden. Dieser Extended Modus muss über den Debug-Codierschalter ein- und ausschaltbar sein. Für den Codierschalter sollte folgende Codierung verwendet werden 0: nichts senden 1: senden Basis-Modus 2: senden Extended-Modus_1 (optional) Die Umsetzung des Modus Erweitert ist optional.
        multiplexed i pdu FR_DBG_EPS:  # FlexRay Debug EPS
          length=58
          dynamic-part{segment-position{segment-byte-order=little-endian, segment-length=464, segment-position=0}, dynamic-part-alternatives=[{i-pdu=DBG_EPS_BS_MOD_58_BYTE, initial-dynamic-part=true, selector-field-code=1}, {i-pdu=DBG_EPS_MOD_EXT_120_BYTE, initial-dynamic-part=false, selector-field-code=2}]}
          selector-field-byte-order=little-endian
          selector-field-length=8
          selector-field-start-position=0
          trigger-mode=DYNAMIC-PART-TRIGGER
          unused-bit-pattern=255
      frame AVL_RPM_WHL: to EPS, category=APPLICATION, frame-length=12, flexray-absolutely-scheduled-timing{communication-cycle=cycle-repetition={base-cycle=0, cycle-repetition=CYCLE-REPETITION-1}, slot-id=46}, allow-dynamic-l-sdu-length=false, payload-preamble-indicator=false  # Ist Drehzahl Rad
        pdu AVL_RPM_WHL: length=12, transmission-mode-true-timing=cyclic-timing=time-period=0.005, unused-bit-pattern=255  # Ist Drehzahl Rad | Die Nachricht beinhaltet die im DSC-Steuergerät eingelesenen Raddrehzahlen. Die Aufbereitung der Fahrzeuggeschwindigkeit erfolgt plausibilisiert im ICM-Q/L-Steuergerät. Zusätzlich wird basierend auf den Raddrehzahlen eine Schlechtwegeerkennung in der Motorsteuerung durchgeführt. Die PDU "Ist Drehzahl Rad" wird auf CAN durch die PDUs "Ist Drehzahl Rad ungesichert" und "Ist Drehzahl Rad Qualifier" abgebildet. "Ist Drehzahl Rad" ist nur am FlexRay vorhanden, "Ist Drehzahl Rad ungesichert" und "Ist Drehzahl Rad Qualifier" nur am CAN. Das Gateway (ZGW) setzt die Nachrichten entsprechend um. Bitte die Zusammenhänge bei Änderungen beachten, da zwischen den PDUs Abhängigkeit besteht. DMEs für Motoren vor dem B38 dürfen eine Unterabtastung der Nachricht durchführen.
          signal ALIV_AVL_RPM_WHL: start 8, 4 bit, little-endian, base-type=uint8, invalid-value=value_15Dot0:15, compu-method=ALIV_COU_4, to EPS  # Alive_Ist_Drehzahl_Rad / alive_actual-value_RPM_wheel | LogicalInterface:BMW.POWERTRAIN.SpeedAccelerationDistance[external]@Fahren;
          signal AVL_RPM_WHL_FLH: start 48, 16 bit, little-endian, base-type=uint16, invalid-value=value_65535Dot0:65535, compu-method=AVL_RPM_WHL, data-constr=AVL_RPM_WHL, to EPS  # Ist_Drehzahl_Rad_VL / actual-value_RPM_wheel_FLH | LogicalInterface:BMW.POWERTRAIN.SpeedAccelerationDistance[external]@Fahren; Gemessene Drehzahl des vorderen linken Einzelrads. Hinweis: Aufgrund der derzeitigen bei der Nachrichtenkataloggenerierung durch die IT bedingte Rundung von Nachkommastellen, werden die Offset- und Quantisierungswerte nicht korrekt wieder gegeben. Folgende Angaben entsprechen den exakten Werten: Offset = -511,984375 Quantisierung = 0,015625 Die Drehrichtungsinformation der Signale (Vorzeichen des übermittelten Wertes) ist zeitweise nicht verlässlich. Die Verlässlichkeit ist in den jeweiligen Status Qualifiern (Qualifier_Ist_Drehzahl_Rad_XX, nur in "Ist Drehzahl Rad" und "Ist Drehzahl Rad Qualifier" enthalten) angegeben. Nach Stillstand ist die Drehrichtung erst nach ca. 15cm Fahrstrecke plausibilisiert. Vorher wird immer der Ersatzwert (positiver Betrag) übertragen. In F25 und L7 gilt zusätzlich für Fahrzeuge mit Raddrehzahlfühler - ohne Drehrichtungserkennung wird der Wertebereich nur von 0 bis 400 rad/s befüllt - mit Drehrichtungserkennung wird der Wertebereich von -400 bis 400 rad/s befüllt Über die Dienstbotschaft (Anfrage ID 427 "Konfiguration DSC") kann das DSC aufgefordert werden die Informationen, welche Sensoren verbaut sind, zu senden. (Rückmeldung erfolgt über die Botschaft "Konfiguration DSC") Dieses Signal hat ein Äquivalent auf dem SF-CAN.
          signal AVL_RPM_WHL_FRH: start 64, 16 bit, little-endian, base-type=uint16, invalid-value=value_65535Dot0:65535, compu-method=AVL_RPM_WHL, data-constr=AVL_RPM_WHL, to EPS  # Ist_Drehzahl_Rad_VR / actual-value_RPM_wheel_FRH | LogicalInterface:BMW.POWERTRAIN.SpeedAccelerationDistance[external]@Fahren; Gemessene Drehzahl des vorderen rechten Einzelrads. Hinweis: Aufgrund der derzeitigen bei der Nachrichtenkataloggenerierung durch die IT bedingte Rundung von Nachkommastellen, werden die Offset- und Quantisierungswerte nicht korrekt wieder gegeben. Folgende Angaben entsprechen den exakten Werten: Offset = -511,984375 Quantisierung = 0,015625 Die Drehrichtungsinformation der Signale (Vorzeichen des übermittelten Wertes) ist zeitweise nicht verlässlich. Die Verlässlichkeit ist in den jeweiligen Status Qualifiern (Qualifier_Ist_Drehzahl_Rad_XX, nur in "Ist Drehzahl Rad" und "Ist Drehzahl Rad Qualifier" enthalten) angegeben. Nach Stillstand ist die Drehrichtung erst nach ca. 15cm Fahrstrecke plausibilisiert. Vorher wird immer der Ersatzwert (positiver Betrag) übertragen. In F25 und L7 gilt zusätzlich für Fahrzeuge mit Raddrehzahlfühler - ohne Drehrichtungserkennung wird der Wertebereich nur von 0 bis 400 rad/s befüllt - mit Drehrichtungserkennung wird der Wertebereich von -400 bis 400 rad/s befüllt Über die Dienstbotschaft (Anfrage ID 427 "Konfiguration DSC") kann das DSC aufgefordert werden die Informationen, welche Sensoren verbaut sind, zu senden. (Rückmeldung erfolgt über die Botschaft "Konfiguration DSC") Dieses Signal hat ein Äquivalent auf dem SF-CAN.
          signal AVL_RPM_WHL_RLH: start 16, 16 bit, little-endian, base-type=uint16, invalid-value=value_65535Dot0:65535, compu-method=AVL_RPM_WHL, data-constr=AVL_RPM_WHL, to EPS  # Ist_Drehzahl_Rad_HL / actual-value_RPM_wheel_RLH | LogicalInterface:BMW.POWERTRAIN.SpeedAccelerationDistance[external]@Fahren; Gemessene Drehzahl des hinteren linken Einzelrads. Hinweis: Aufgrund der derzeitigen bei der Nachrichtenkataloggenerierung durch die IT bedingte Rundung von Nachkommastellen, werden die Offset- und Quantisierungswerte nicht korrekt wieder gegeben. Folgende Angaben entsprechen den exakten Werten: Offset = -511,984375 Quantisierung = 0,015625 Die Drehrichtungsinformation der Signale (Vorzeichen des übermittelten Wertes) ist zeitweise nicht verlässlich. Die Verlässlichkeit ist in den jeweiligen Status Qualifiern (Qualifier_Ist_Drehzahl_Rad_XX, nur in "Ist Drehzahl Rad" und "Ist Drehzahl Rad Qualifier" enthalten) angegeben. Nach Stillstand ist die Drehrichtung erst nach ca. 15cm Fahrstrecke plausibilisiert. Vorher wird immer der Ersatzwert (positiver Betrag) übertragen. In F25 und L7 gilt zusätzlich für Fahrzeuge mit Raddrehzahlfühler - ohne Drehrichtungserkennung wird der Wertebereich nur von 0 bis 400 rad/s befüllt - mit Drehrichtungserkennung wird der Wertebereich von -400 bis 400 rad/s befüllt Über die Dienstbotschaft (Anfrage ID 427 "Konfiguration DSC") kann das DSC aufgefordert werden die Informationen, welche Sensoren verbaut sind, zu senden. (Rückmeldung erfolgt über die Botschaft "Konfiguration DSC")
          signal AVL_RPM_WHL_RRH: start 32, 16 bit, little-endian, base-type=uint16, invalid-value=value_65535Dot0:65535, compu-method=AVL_RPM_WHL, data-constr=AVL_RPM_WHL, to EPS  # Ist_Drehzahl_Rad_HR / actual-value_RPM_wheel_RRH | LogicalInterface:BMW.POWERTRAIN.SpeedAccelerationDistance[external]@Fahren; Gemessene Drehzahl des hinteren rechten Einzelrads. Hinweis: Aufgrund der derzeitigen bei der Nachrichtenkataloggenerierung durch die IT bedingte Rundung von Nachkommastellen, werden die Offset- und Quantisierungswerte nicht korrekt wieder gegeben. Folgende Angaben entsprechen den exakten Werten: Offset = -511,984375 Quantisierung = 0,015625 Die Drehrichtungsinformation der Signale (Vorzeichen des übermittelten Wertes) ist zeitweise nicht verlässlich. Die Verlässlichkeit ist in den jeweiligen Status Qualifiern (Qualifier_Ist_Drehzahl_Rad_XX, nur in "Ist Drehzahl Rad" und "Ist Drehzahl Rad Qualifier" enthalten) angegeben. Nach Stillstand ist die Drehrichtung erst nach ca. 15cm Fahrstrecke plausibilisiert. Vorher wird immer der Ersatzwert (positiver Betrag) übertragen. In F25 und L7 gilt zusätzlich für Fahrzeuge mit Raddrehzahlfühler - ohne Drehrichtungserkennung wird der Wertebereich nur von 0 bis 400 rad/s befüllt - mit Drehrichtungserkennung wird der Wertebereich von -400 bis 400 rad/s befüllt Über die Dienstbotschaft (Anfrage ID 427 "Konfiguration DSC") kann das DSC aufgefordert werden die Informationen, welche Sensoren verbaut sind, zu senden. (Rückmeldung erfolgt über die Botschaft "Konfiguration DSC")
          signal AVL_RPM_WHL_dummy_12_15: start 12, 4 bit, little-endian, init-value=15, base-type=uint8, compu-method=UINT4, data-constr=UINT4, to EPS
          signal CRC_AVL_RPM_WHL: start 0, 8 bit, little-endian, base-type=uint8, compu-method=CRC8, data-constr=CRC8, to EPS  # CRC_Ist_Drehzahl_Rad / CRC_actual-value_RPM_wheel | LogicalInterface:BMW.POWERTRAIN.SpeedAccelerationDistance[external]@Fahren; Dieses Signal verwendet die Applikations-CRC-ID = 17 (Dez)
          signal QU_AVL_RPM_WHL_FLH: start 88, 4 bit, little-endian, base-type=uint8, invalid-value=value_15Dot0:15, compu-method=QU_AVL_RPM_WHL, to EPS  # Qualifier_Ist_Drehzahl_Rad_VL / Qualifier_actual-value_RPM_wheel_FLH | LogicalInterface:BMW.POWERTRAIN.SpeedAccelerationDistance[external]@Fahren; Status Qualifier zum Signal Ist_Drehzahl_Rad_VL. Ausführliche Spezifikation der Qualifier ist im Komponenten Lastenheften DSC und IPM zu finden. Dieses Signal hat ein Äquivalent auf dem SF-CAN.
          signal QU_AVL_RPM_WHL_FRH: start 92, 4 bit, little-endian, base-type=uint8, invalid-value=value_15Dot0:15, compu-method=QU_AVL_RPM_WHL, to EPS  # Qualifier_Ist_Drehzahl_Rad_VR / Qualifier_actual-value_RPM_wheel_FRH | LogicalInterface:BMW.POWERTRAIN.SpeedAccelerationDistance[external]@Fahren; Status Qualifier zum Signal Ist_Drehzahl_Rad_VR. Ausführliche Spezifikation der Qualifier ist im Komponenten Lastenheften DSC und IPM zu finden. Dieses Signal hat ein Äquivalent auf dem SF-CAN.
          signal QU_AVL_RPM_WHL_RLH: start 80, 4 bit, little-endian, base-type=uint8, invalid-value=value_15Dot0:15, compu-method=QU_AVL_RPM_WHL, to EPS  # Qualifier_Ist_Drehzahl_Rad_HL / Qualifier_actual-value_RPM_wheel_RLH | LogicalInterface:BMW.POWERTRAIN.SpeedAccelerationDistance[external]@Fahren; Status Qualifier zum Signal Ist_Drehzahl_Rad_HL. Ausführliche Spezifikation der Qualifier ist im Komponenten Lastenheften DSC und IPM zu finden.
          signal QU_AVL_RPM_WHL_RRH: start 84, 4 bit, little-endian, base-type=uint8, invalid-value=value_15Dot0:15, compu-method=QU_AVL_RPM_WHL, to EPS  # Qualifier_Ist_Drehzahl_Rad_HR / Qualifier_actual-value_RPM_wheel_RRH | LogicalInterface:BMW.POWERTRAIN.SpeedAccelerationDistance[external]@Fahren; Status Qualifier zum Signal Ist_Drehzahl_Rad_HR. Ausführliche Spezifikation der Qualifier ist im Komponenten Lastenheften DSC und IPM zu finden
          mapping sigGroup_AVL_RPM_WHL: i-signal-group=sigGroup_AVL_RPM_WHL
      frame ST_STAB_DSC_ST_STAB_DSC_2: to EPS, category=APPLICATION, frame-length=16, flexray-absolutely-scheduled-timing{communication-cycle=cycle-repetition={base-cycle=1, cycle-repetition=CYCLE-REPETITION-2}, slot-id=47}, allow-dynamic-l-sdu-length=false, payload-preamble-indicator=false  # Status Stabilisierung DSC / Status Stabilisierung DSC 2 | Statusinformation des DSC_Moduls.
        pdu ST_STAB_DSC: length=8, transmission-mode-true-timing=cyclic-timing=time-period=0.01, unused-bit-pattern=255  # Status Stabilisierung DSC | Statusinformation des DSC_Moduls.
          signal QU_FN_FDR: start 16, 12 bit, little-endian, base-type=uint16, invalid-value=value_4095Dot0:4095, compu-method=QU_FN_FDR, to EPS  # Qualifier_Funktion_FDR / Qualifier_function_FDR | LogicalInterface:BMW.CHASSIS.STABILIZATION.VehicleStabilizationManagement[external]@Fahren; Funktions-Qualifier zur FDR. Die untersten 3 Bits dieses Signals können vom DSC für Entwicklungszwecke belegt werden, sind aber nicht auszuwerten. Weitere Details finden sich im DSC-KomponentenLH
      frame AVL_STMOM_DV_ACT_AVL_FORC_GRD: from EPS, category=APPLICATION, frame-length=16, flexray-absolutely-scheduled-timing{communication-cycle=cycle-repetition={base-cycle=0, cycle-repetition=CYCLE-REPETITION-2}, slot-id=49}, allow-dynamic-l-sdu-length=false, payload-preamble-indicator=false  # Ist Lenkmoment Fahrer Stellglied / Ist Kraft Zahnstange / actual-value steering-moment driver actuator / Ist Kraft Zahnstange | Dieser Frame setzt sich zusammen aus den PDUs Ist Lenkmoment Fahrer Stellglied und Ist Kraft Zahnstange.
        carries pdu AVL_FORC_GRD: packing-byte-order=little-endian, start-position=64
        pdu AVL_FORC_GRD: length=5, transmission-mode-true-timing=cyclic-timing=time-period=0.01, unused-bit-pattern=255  # Ist Kraft Zahnstange | Die angegebene Zahnstangenkraft ist eine aus dem Zustandsbeobachter geschätzte Grösse. Dieser Frame ist Teil der KOM-Schnittstelle Lenkradmomentenregler des OEL-Reglers. Diese Version der Nachricht gilt bis SP2013.
          signal ALIV_AVL_FORC_GRD: start 8, 4 bit, little-endian, base-type=uint8, invalid-value=value_15Dot0:15, compu-method=ALIV_COU_4  # Alive_Ist_Kraft_Zahnstange / alive_actual-value_force_gear-rod | LogicalInterface:BMW.CHASSIS.STEERING.ElectricPowerSteering[internal]@Fahren; Standardabsicherung Alivezähler laut Definition per Lastenheft Allgemeine Bordnetzkommunikation.
          signal AVL_FORC_GRD: start 16, 12 bit, little-endian, base-type=uint16, invalid-value=value_4095Dot0:4095, compu-method=AVL_FORC_GRD, data-constr=AVL_FORC_GRD  # Ist_Kraft_Zahnstange / actual-value_force_gear-rod | LogicalInterface:BMW.CHASSIS.STEERING.ElectricPowerSteering[internal]@Fahren; Die angegebene Zahnstangenkraft (aus dem Zustandsbeobachter geschätzte Größe) spiegelt die Ist-Kraft der Zahnstange (EPS + Fahrer) wieder. Die Zahnstangenkraft ist bei einer Bewegung des Lenkrads aus seiner Nulllage entgegen des Uhrzeigersinns positiv.
          signal AVL_FORC_GRD_dummy_12_15: start 12, 4 bit, little-endian, init-value=15, base-type=uint8, compu-method=UINT4, data-constr=UINT4
          signal AVL_PWR_EL_EPS_COOD: start 32, 8 bit, little-endian, base-type=uint8, invalid-value=value_255Dot0:255, compu-method=AVL_PWR_EL, data-constr=AVL_PWR_EL  # Ist_Leistung_Elektrisch_EPS_Koordinator / actual-value_power_electric_EPS_coordinator | LogicalInterface:BMW.CHASSIS.STEERING.ElectricPowerSteering[internal]@Fahren;
          signal CRC_AVL_FORC_GRD: start 0, 8 bit, little-endian, base-type=uint8, compu-method=CRC8, data-constr=CRC8  # CRC_Ist_Kraft_Zahnstange / CRC_actual-value_force_gear-rod | LogicalInterface:BMW.CHASSIS.STEERING.ElectricPowerSteering[internal]@Fahren; Standardabsicherung Applikations-CRC Dieses Signal verwendet die Applikations-CRC-ID = 190 (Dez)
          signal QU_AVL_FORC_GRD: start 28, 4 bit, little-endian, base-type=uint8, invalid-value=value_15Dot0:15, compu-method=QU_AVL_FORC_GRD  # Qualifier_Ist_Kraft_Zahnstange / Qualifier_actual-value_force_gear-rod | LogicalInterface:BMW.CHASSIS.STEERING.ElectricPowerSteering[internal]@Fahren; Erweiterter Qualifier zum Signal Ist_Kraft_Zahnstange
          mapping sigGroup_AVL_FORC_GRD: i-signal-group=sigGroup_AVL_FORC_GRD
        pdu AVL_STMOM_DV_ACT: length=4, transmission-mode-true-timing=cyclic-timing=time-period=0.01, unused-bit-pattern=255  # Ist Lenkmoment Fahrer Stellglied / actual-value steering-moment driver | Darstellung des Fahrerhandmoment. Diese Version der Nachricht gilt bis SP2013.
          signal ALIV_AVL_STMOM_DV_ACT: start 8, 4 bit, little-endian, base-type=uint8, invalid-value=value_15Dot0:15, compu-method=ALIV_COU_4  # Alive_Ist_Lenkmoment_Fahrer_Stellglied / alive_actual-value_steering-moment_driver_actuator | LogicalInterface:BMW.CHASSIS.STEERING.ElectricPowerSteering[external]@Fahren; Standardabsicherung Alivezähler laut Definition per Lastenheft Allgemeine Bordnetzkommunikation.
          signal AVL_STMOM_DV_ACT: start 16, 12 bit, little-endian, base-type=uint16, invalid-value=value_4095Dot0:4095, compu-method=STMOM_QTA_DV, data-constr=STMOM_QTA_DV  # Ist_Lenkmoment_Fahrer_Stellglied / actual-value_steering-moment_driver_actuator | LogicalInterface:BMW.CHASSIS.STEERING.ElectricPowerSteering[external]@Fahren; Das Signal Ist_Lenkmoment_Fahrer stellt das Fahrerlenkmoment im Gegenuhrzeigersinn positiv dar.
          signal AVL_STMOM_DV_ACT_dummy_12_15: start 12, 4 bit, little-endian, init-value=15, base-type=uint8, compu-method=UINT4, data-constr=UINT4
          signal CRC_AVL_STMOM_DV_ACT: start 0, 8 bit, little-endian, base-type=uint8, compu-method=CRC8, data-constr=CRC8  # CRC_Ist_Lenkmoment_Fahrer_Stellglied / CRC_actual-value_steering-moment_driver_actuator | LogicalInterface:BMW.CHASSIS.STEERING.ElectricPowerSteering[external]@Fahren; Standardabsicherung Applikations-CRC laut Definition per Lastenheft Allgemeine Bordnetzkommunikation. Dieses Signal verwendet die Applikations-CRC-ID = 108 (Dez)
          signal QU_AVL_STMOM_DV_ACT: start 28, 4 bit, little-endian, base-type=uint8, invalid-value=value_15Dot0:15, compu-method=QU_AVL_STMOM_DV_ACT  # Qualifier_Ist_Lenkmoment_Fahrer_Stellglied / Qualifier_actual-value_steering-moment_driver_actuator | LogicalInterface:BMW.CHASSIS.STEERING.ElectricPowerSteering[external]@Fahren; Erweiterter Status Qualifier zum Signal Ist_Lenkmoment_Fahrer_Stellglied
          mapping sigGroup_AVL_STMOM_DV_ACT: i-signal-group=sigGroup_AVL_STMOM_DV_ACT
      frame DT_EST: from EPS, category=APPLICATION, frame-length=16, flexray-absolutely-scheduled-timing{communication-cycle=cycle-repetition={base-cycle=1, cycle-repetition=CYCLE-REPETITION-2}, slot-id=49}, allow-dynamic-l-sdu-length=false, payload-preamble-indicator=false  # Daten Elektrische-Lenkung
        pdu DT_EST: length=16, transmission-mode-true-timing=cyclic-timing=time-period=0.01, unused-bit-pattern=255  # Daten Elektrische-Lenkung
          signal ALIV_DT_EST: start 8, 4 bit, little-endian, base-type=uint8, invalid-value=value_15Dot0:15, compu-method=ALIV_4_BIT_Unsigned_Integer, data-constr=ALIV_4_BIT_Unsigned_Integer  # Alive_Daten_Elektrische-Lenkung / alive_data_electrical-steering | LogicalInterface:BMW.CHASSIS.STEERING.ElectricPowerSteering[internal]@Fahren; Standardabsicherung Alivezähler laut Definition per Lastenheft Allgemeine Bordnetzkommunikation Dieses Signal soll nur überwacht werden, wenn Aktivlenkung und ein Lenksäulensteller verbaut sind.
          signal AVL_I_ACT_EST: start 48, 8 bit, little-endian, base-type=uint8, invalid-value=value_255Dot0:255, compu-method=I_SPEC_ARS, data-constr=I_SPEC_ARS  # Ist_Strom_Stellglied_Elektrische-Lenkung / actual-value_current_actuator_electrical-steering | LogicalInterface:BMW.CHASSIS.LOWVOLTAGE.EnergyManagementELMa[internal]@Fahren; Es handelt sich um den DC-Last-Strom am Stecker der elektrischen Lenkmomentenunterstützung (EPS-Motor). Der Strom ist über einen FR-Task gemittelt. Aufstart- und Default-Wert ist 0 A.
          signal CRC_DT_EST: start 0, 8 bit, little-endian, base-type=uint8, compu-method=CRC8, data-constr=CRC8  # CRC_Daten_Elektrische-Lenkung / CRC_data_electrical-steering | LogicalInterface:BMW.CHASSIS.STEERING.ElectricPowerSteering[internal]@Fahren; Standardabsicherung Applikations-CRC laut Definition per Lastenheft Allgemeine Bordnetzkommunikation. Dieses Signal verwendet die Applikations-CRC-ID = 230 (dec) Dieses Signal soll nur überwacht werden, wenn Aktivlenkung und ein Lenksäulensteller verbaut sind.
          signal DT_EST_dummy_12_15: start 12, 4 bit, little-endian, init-value=15, base-type=uint8, compu-method=UINT4, data-constr=UINT4
          signal DT_EST_dummy_16_47: start 16, 32 bit, little-endian, init-value=4294967295, base-type=uint32, compu-method=UINT32, data-constr=UINT32
          signal DT_EST_dummy_64_95: start 64, 32 bit, little-endian, init-value=4294967295, base-type=uint32, compu-method=UINT32, data-constr=UINT32
          signal DT_EST_dummy_96_127: start 96, 32 bit, little-endian, init-value=4294967295, base-type=uint32, compu-method=UINT32, data-constr=UINT32
          signal QU_AVL_I_ACT_EST: start 60, 4 bit, little-endian, base-type=uint8, invalid-value=value_15Dot0:15, compu-method=QU_SUM_AVL_I_DRDY_SFY  # Qualifier_Ist_Strom_Stellglied_Elektrische-Lenkung / Qualifier_actual-value_current_actuator_electrical-steering | LogicalInterface:BMW.POWERTRAIN.GENERATOR.EnergySupplySafe[internal]@Fahren; Signalqualifier zum Signal Ist_Strom_Stellglied_Elektrische-Lenkung.
          signal ST_CULI_EST: start 56, 4 bit, little-endian, base-type=uint8, invalid-value=value_15Dot0:15, compu-method=ST_CULI_EST  # Status_Strombegrenzung_Elektrische-Lenkung / status_current-limitation_electrical-steering | LogicalInterface:BMW.POWERTRAIN.GENERATOR.EnergySupplySafe[internal]@Fahren; In diesem Signal wird übermittelt, ob und in welchem Umfang eine Strombegrenzung an der Elektrischen Lenkung umgesetzt wurde.
          mapping sigGroup_DT_EST: i-signal-group=sigGroup_DT_EST
      frame AVL_PO_EPS_ENGTORQ_EPS: from EPS, category=APPLICATION, frame-length=16, flexray-absolutely-scheduled-timing{communication-cycle=cycle-repetition={base-cycle=0, cycle-repetition=CYCLE-REPETITION-2}, slot-id=51}, allow-dynamic-l-sdu-length=false, payload-preamble-indicator=false  # Ist Position EPS / Motormoment EPS
        pdu AVL_PO_EPS: length=8, transmission-mode-true-timing=cyclic-timing=time-period=0.01, unused-bit-pattern=255  # Ist Position EPS | Die Nachricht enthält die EPS-Position, berechnet aus dem aufintegrierten EPS-Rotorlagewinkel. Diese Größe dient als Eingangsgröße für die aufbereiteten Lenkwinkel Nachrichten "Ist Lenkwinkel Fahrer", "Ist Lenkwinkel Vorderachse" und "Lenkwinkel Vorderachse Effektiv".
          signal ALIV_AVL_PO_EPS: start 8, 4 bit, little-endian, base-type=uint8, invalid-value=value_15Dot0:15, compu-method=ALIV_COU_4  # Alive_Ist_Position_EPS / alive_actual-value_position_EPS | LogicalInterface:BMW.CHASSIS.STEERING.ElectricPowerSteering[internal]@Fahren;
          signal AVL_PO_EPS: start 16, 16 bit, little-endian, base-type=uint16, invalid-value=value_65535Dot0:65535, compu-method=AVL_PINA_EPS, data-constr=AVL_PINA_EPS  # Ist_Position_EPS / actual-value_position_EPS | LogicalInterface:BMW.CHASSIS.STEERING.ElectricPowerSteering[internal]@Fahren; Relative Position, berechnet aus dem aufintegrierten EPS-Rotorlagewinkel, bezogen auf den aktuellen Nullpunkt der EPS (entspricht der Segmentmitte des Segments in dem sich der EPS-Rotor z.B. nach dem letzten Einbruch der Spannungsversorgung befand), sofern mittels des Aufsetzalgorithmus der Offset des aktuellen Nullpunktes zum absoluten Nullpunkt (Segmentmitte des Segments bei Geradeausfahrt) noch nicht ermittelt werden konnte (zugehöriger Qualifier: "Ersatzwert ist im Nutzsignal gesetzt"). Sobald der Offset zum absoluten Nullpunkt bestimmt werden konnte und an die EPS übermittelt wurde, entspricht dieser dem absoluten Position (zugehöriger Qualifier: "Signalwert ist gültig"). Nach erfolgreicher EPS-interner Plausibilisierung wird der Qualifier auf "Signalwert ist gültig und abgesichert und plausibilisiert" gesetzt. Das Signal wird ohne Einheit übertragen. Die Einheit kann aus dem Signal "Einheit_Position_EPS" entnommen werden: - Im F25/L7 ist das Signal als Zahnstangenhub zu interpretieren. Die Einheit ist somit 0.2mm. Der Zahnstangenhub ist bei einer Bewegung des Lenkrads aus seiner Nulllage entgegen des Uhrzeigersinns positiv. Der zugehörige Signalstatus wird gebildet (Qualifier_Ist_Position_EPS). Die Informationen stehen bei Zündung ein oder fahrendem Fahrzeug mit vereinbarter Güte zur Verfügung Absicherung erfolgt durch Host-CRC und Alive-Zähler. Wert Bedeutung 0 Theoretisch maximaler Wert rechts 7FFF Geradeausstellung FFFE Thoretisch maximaler Wert links.
          signal AVL_PO_IDX_EPS: start 32, 16 bit, little-endian, base-type=uint16, invalid-value=value_65535Dot0:65535, compu-method=AVL_PINA_IDX_ICM, data-constr=AVL_PINA_IDX_ICM  # Ist_Position_Index_EPS / actual-value_position_index_EPS | LogicalInterface:BMW.CHASSIS.STEERING.ElectricPowerSteering[internal]@Fahren; Dieser Wert entspricht der aktuellen Position zum Zeitpunkt einer detektierten Indexflanke. Das Signal wird ohne Einheit übertragen. Die Einheit kann aus dem Signal "Einheit_Position_EPS" entnommen werden: - Im F25/L7 ist das Signal als Zahnstangenhub zu interpretieren. Die Einheit ist somit 0.2mm. Hinweis: Aufgrund der derzeitigen bei der Nachrichtenkataloggenerierung durch die IT bedingte Rundung von Nachkommastellen, werden die Offset- und Quantisierungswerte nicht korrekt wieder gegeben. Folgende Angaben entsprechen den exakten Werten: Offset = -1439,9560546875 Quantisierung = 0,0439453125
          signal CRC_AVL_PO_EPS: start 0, 8 bit, little-endian, base-type=uint8, compu-method=CRC8, data-constr=CRC8  # CRC_Ist_Position_EPS / CRC_actual-value_position_EPS | LogicalInterface:BMW.CHASSIS.STEERING.ElectricPowerSteering[internal]@Fahren; Standardabsicherung Applikations-CRC Dieses Signal verwendet die Applikations-CRC-ID = 186 (Dez)
          signal IDX_TORQ_SEN: start 60, 2 bit, little-endian, base-type=uint8, invalid-value=value_3Dot0:3, compu-method=IDX_TORQ_SEN  # Index_Drehmoment_Sensor / index_torque_sensor | LogicalInterface:BMW.CHASSIS.STEERING.ElectricPowerSteering[internal]@Fahren; Information, ob das Lenkrad (bei nicht-AFS-Verbau, ansonsten Lenkgestänge "nach" AFS-Zustellaktuatorik) seit dem letzten Zyklus durch die 0° (=Geradeausfahrt), ±360° oder ±720° - Position bewegt worden ist.
          signal OFFS_GRD_MID_EPS: start 48, 12 bit, little-endian, base-type=uint16, invalid-value=value_4095Dot0:4095, compu-method=OFFS_GRD_MID_EPS, data-constr=OFFS_GRD_MID_EPS  # Offset_Zahnstange_Mitte_EPS / offset_gear-rod_middle_EPS | LogicalInterface:BMW.CHASSIS.STEERING.ElectricPowerSteering[internal]@Fahren; Offset zwischen Zahnstangenmitte und dem Lenkwinkel-Nullpunkt (Geradeauslauf). Das Signal wird ohne Einheit übertragen. Die Einheit kann aus dem Signal "Einheit_Position_EPS" entnommen werden: - Im F25/L7 ist das Signal als Zahnstangenhub zu interpretieren. Die Einheit ist somit 0.2mm.
          signal QU_AVL_PO_EPS: start 12, 4 bit, little-endian, base-type=uint8, invalid-value=value_15Dot0:15, compu-method=QU_AVL_PINA_EPS  # Qualifier_Ist_Position_EPS / Qualifier_actual-value_position_EPS | LogicalInterface:BMW.CHASSIS.STEERING.ElectricPowerSteering[internal]@Fahren; Signal Qualifier zum Signal Ist_Position_EPS
          signal UN_PO_EPS: start 62, 2 bit, little-endian, base-type=uint8, invalid-value=value_3Dot0:3, compu-method=UN_PO_EPS  # Einheit_Position_EPS / unit-of-measurement_position_EPS | LogicalInterface:BMW.CHASSIS.STEERING.ElectricPowerSteering[internal]@Fahren; Über dieses Signal wird übermittelt ob die Position als Ritzelwinkel oder Zahnstangenhub zu interpretieren ist. Die Einheit gilt für folgende Signale: - Offset_Zahnstange_Mitte _EPS - Ist_ Position_Index_EPS - Ist_ Position_EPS - Ist_ Position_Index_ICM (im Nachricht Offset Quadrant EPS)
          mapping sigGroup_AVL_PO_EPS: i-signal-group=sigGroup_AVL_PO_EPS
        carries pdu ENGTORQ_EPS: packing-byte-order=little-endian, start-position=64
        pdu ENGTORQ_EPS: length=8, transmission-mode-true-timing=cyclic-timing=time-period={tolerance=absolute-tolerance=0, value=0.01}, unused-bit-pattern=255  # Motormoment EPS | Diese PDU enthält Informationen zu Größen aus der EPS
          signal TRGG_ENGTORQ_EPS: start 16, 12 bit, little-endian, base-type=uint16, invalid-value=value_4095Dot0:4095, compu-method=TRGG_ENGTORQ_EPS, data-constr=TRGG_ENGTORQ_EPS  # Ansteuerung_Motormoment_EPS / triggering_engine-torque_EPS | LogicalInterface:BMW.CHASSIS.STEERING.ElectricPowerSteering[internal]@Fahren; Das EPS-Soll-Motormoment das an die FOR (Feld Orientierte Regelung) übergeben wird.
      frame SU_CLE_DRDY_DXP_SPEC_ADPT_MOD_DXP_ST_IDLV_COOD_DBE_DXP: to EPS, category=APPLICATION, frame-length=16, flexray-absolutely-scheduled-timing{communication-cycle=cycle-repetition={base-cycle=3, cycle-repetition=CYCLE-REPETITION-8}, slot-id=53}, allow-dynamic-l-sdu-length=false, payload-preamble-indicator=false  # Konfiguration Stellhebel Fahrdynamik Fahrerlebnis / Vorgabe Adaption Modus Fahrerlebnis / Status Individualisierung Koordinator Fahrverhalten Fahrerlebnis | Diese Nachricht setzt sich zusammen aus den PDUs Konfiguration Stellhebel Fahrdynamik Fahrerlebnis, Vorgabe Adaption Modus Fahrerlebnis und Status Individualisierung Koordinator Fahrverhalten Fahrerlebnis.
        pdu SU_CLE_DRDY_DXP: length=8, transmission-mode-true-timing=cyclic-timing=time-period=0.04, unused-bit-pattern=255  # Konfiguration Stellhebel Fahrdynamik Fahrerlebnis | In dieser Botschaft werden die Ausprägungen der teilnehmenden Funktionen des FES Koordinators Fahrverhalten kommuniziert.
          signal FACT_MO_STE_SO_DXP: start 16, 8 bit, little-endian, base-type=uint8, invalid-value=value_255Dot0:255, compu-method=FACT_MO_STE_SO_DXP, data-constr=FACT_MO_STE_SO_DXP, to EPS  # Faktor_Modifikation_Lenkung_Servo_Fahrerlebnis / factor_modification_steering_servo_driving-experience | LogicalInterface:BMW.POWERTRAIN.DrivingExperienceControl[internal]@Fahren;
          signal SU_CLU_STMOM_SFE_DXP: start 8, 4 bit, little-endian, base-type=uint8, invalid-value=value_15Dot0:15, compu-method=SU_CLU_STMOM_SFE_DXP, to EPS  # Konfiguration_Cluster_Lenkmoment_Lenkgefühl_Fahrerlebnis / setup_cluster_steering-moment_steering-feel_driving-experience | LogicalInterface:BMW.POWERTRAIN.DrivingExperienceControl[internal]@Fahren; Mit diesem Signal werden die Funktionen des FES Clusters Lenkmoment/Lenkgefühl auf die zum aktuellen FES Modus gehörige Einstellung geschaltet (Lenkunterstützung, Dämpfung, Aktive Rückstellung).
      frame ACLNX_MASSCNTR_ACLNY_MASSCNTR: to EPS, category=APPLICATION, frame-length=14, flexray-absolutely-scheduled-timing{communication-cycle=cycle-repetition={base-cycle=0, cycle-repetition=CYCLE-REPETITION-2}, slot-id=55}, allow-dynamic-l-sdu-length=false, payload-preamble-indicator=false  # Längsbeschleunigung Schwerpunkt / Querbeschleunigung Schwerpunkt | Dieser Frame setzt sich zusammen aus den PDUs Längsbeschleunigung Schwerpunkt und Querbeschleunigung Schwerpunkt.
        carries pdu ACLNY_MASSCNTR: packing-byte-order=little-endian, start-position=64
        pdu ACLNY_MASSCNTR: length=6, transmission-mode-true-timing=cyclic-timing=time-period=0.01, unused-bit-pattern=255  # Querbeschleunigung Schwerpunkt | Gemessene und plausibilisierte Querbeschleunigung im Fahrzeugschwerpunkt. Diese Nachricht wird nicht im EntryHU Gateway der PL7 geroutet.
          signal ACLNY_COG: start 16, 16 bit, little-endian, base-type=uint16, invalid-value=value_65535Dot0:65535, compu-method=ACLNY_COG, data-constr=ACLNY_COG, to EPS  # Querbeschleunigung_Schwerpunkt / lateral-acceleration_centre-of-gravity | LogicalInterface:BMW.POWERTRAIN.SpeedAccelerationDistance[external]@Fahren; Querbeschleunigung im Fahrzeugschwerpunkt. Eine positive Querbeschleunigung wird durch eine vorwärts durchfahrene Linkskurve erzeugt. Fahrzeugkoordinatensystem gemäß ISO 8855. Die Querbeschleunigung des Fahrzeuges wird je nach Fahrzeugkonfiguration von einem oder zwei Querbeschleunigungs-sensoren gemessen. Anschließend erfolgt eine Plausibilisierung (durch Modellüberwachung und Redundanzüberwachung bei zwei Sensoren) und ein Langzeitabgleich der Offset-Drift. Sind zwei Querbeschleunigungssensoren verbaut, so wird der Mittelwert der abgeglichenen Signale als Querbeschleunigungsnutzsignal ausgegeben. Es ist zu beachten, dass dieses Signal die Anteile der Gravitation enthält, die zum Beispiel bei einem wankenden Fzg. oder in einer seitengeneigten Fahrbahn mit gemessen werde. Ist einer von zwei Querbeschleunigungssensoren als fehlerhaft erkannt, so wird der Wert des verbleibenden Sensors als Nutzsignal ausgegeben. Im Qualifier erfolgt die Rückstufung des Signals von "gültig + abgesichert" auf "gültig". Die Einstufung "gültig" gilt entsprechend auch dann, wenn nur ein Querbeschleunigungssensor verbaut und fehlerfrei ist. Sind alle im Fzg. verbauten Querbeschleunigungssensoren als fehlerhaft erkannt, so wird ein Ersatzwert aus den verbleibenden Sensoren im Fzg. (Raddrehzahlen, Lenkwinkel, Querbeschleunigung) berechnet und ausgegeben. Entsprechend erfolgt die Kennzeichnung "Ersatzwert" durch den Qualifier. Transp.MOST-GW-Migration, 01.09.2006: Zusammenführung des Parameters LateralAccelerationMassCenter [1] mit dem Signal Querbeschleunigung_Schwerpunkt [3].
          signal ACLNY_COG_ERR_AMP: start 32, 12 bit, little-endian, base-type=uint16, invalid-value=value_4095Dot0:4095, compu-method=ACLNY_COG_ERR_AMP, data-constr=ACLNY_COG_ERR_AMP, to EPS  # Querbeschleunigung_Schwerpunkt_Fehler_Amplitude / lateral-acceleration_centre-of-gravity_error_amplitude | LogicalInterface:BMW.POWERTRAIN.SpeedAccelerationDistance[external]@Fahren; Für den Fall, dass ein Sensorfehler nicht oder noch nicht erkannt wurde, interne Überwachungsmaßnahmen jedoch anzeigen, dass eine Abweichung des Sensorsignals vom tatsächlichen Wert vorliegen könnte, gibt dieser Wert an, wie groß diese Abweichung maximal sein kann. Es wird der Betrag der Fehleramplitude ausgegeben, die Abweichung des tatsächlichen Signals vom ausgegebenen Signal liegt in einem Band mit der doppelten Breite der Fehleramplitude (Signal plus oder minus Fehleramplitude). Der Qualifier des Nutzsignals behält in diesem Fall seinen bisherigen Wert. Beispiel: zwei nicht als fehlerhaft erkannte Querbeschleunigungssensoren liefern die Werte 4 m/s² und 8 m/s². Das ausgegebene Nutzsignal hat in diesem Fall einen Wert von 6 m/s², die Fehleramplitude einen Wert von 2 m/s².
          signal ACLNY_MASSCNTR_dummy_12_15: start 12, 4 bit, little-endian, init-value=15, base-type=uint8, compu-method=UINT4, data-constr=UINT4, to EPS
          signal ALIV_ACLNY_COG: start 8, 4 bit, little-endian, base-type=uint8, invalid-value=value_15Dot0:15, compu-method=ALIV_COU_4, to EPS  # Alive_Querbeschleunigung_Schwerpunkt / alive_lateral-acceleration_centre-of-gravity | LogicalInterface:BMW.POWERTRAIN.SpeedAccelerationDistance[external]@Fahren;
          signal CRC_ACLNY_COG: start 0, 8 bit, little-endian, base-type=uint8, compu-method=CRC8, data-constr=CRC8, to EPS  # CRC_Querbeschleunigung_Schwerpunkt / CRC_lateral-acceleration_centre-of-gravity | LogicalInterface:BMW.POWERTRAIN.SpeedAccelerationDistance[external]@Fahren; Standardabsicherung Applikations-CRC Dieses Signal verwendet die Applikations-CRC-ID = 31 (Dez)
          signal QU_ACLNY_COG: start 44, 4 bit, little-endian, base-type=uint8, invalid-value=value_15Dot0:15, compu-method=QU_ACLNY_COG, to EPS  # Qualifier_Querbeschleunigung_Schwerpunkt / Qualifier_lateral-acceleration_centre-of-gravity | LogicalInterface:BMW.POWERTRAIN.SpeedAccelerationDistance[external]@Fahren; Erweiterter Status Qualifier zum Signal Querbeschleunigung_Schwerpunkt. Mindestanforderungen um einen gültigen Signalwert senden zu können (Stand 10.06.08 gilt für L6/L7/F25): - Klemme 30B + Geschwindigkeit_Fahrzeug_Schwerpunkt gültig + Lenkwinkel_Vorderachse_effektiv gültig alternative Aufstartbedingung: - Bei Erkennung eines Modellfehlers wird bei Kl.15 Änderung ein Reset durchgeführt. Frühestens 50ms später kann ein gültiger Wert kommen. In dieser Zeit wird der Qualifier auf Initialisierung gesetzt.
          mapping sigGroup_ACLNY_MASSCNTR: i-signal-group=sigGroup_ACLNY_MASSCNTR
      frame V_VEH_V_VEH_2: to EPS, category=APPLICATION, frame-length=16, flexray-absolutely-scheduled-timing{communication-cycle=cycle-repetition={base-cycle=3, cycle-repetition=CYCLE-REPETITION-4}, slot-id=55}, allow-dynamic-l-sdu-length=false, payload-preamble-indicator=false  # Geschwindigkeit Fahrzeug / Geschwindigkeit Fahrzeug 2
        pdu V_VEH: length=5, transmission-mode-true-timing=cyclic-timing=time-period=0.02, unused-bit-pattern=255  # Geschwindigkeit Fahrzeug | Diese Nachricht beinhaltet die Geschwindigkeit des Fahrzeugschwerpunktes und den Fahrzustand des Fahrzeuges.
          signal ALIV_V_VEH: start 8, 4 bit, little-endian, base-type=uint8, invalid-value=value_15Dot0:15, compu-method=ALIV_COU_V, to EPS  # Alive_Geschwindigkeit_Fahrzeug / alive_speed_vehicle | LogicalInterface:BMW.POWERTRAIN.SpeedAccelerationDistance[external]@Fahren; Transp.MOST-GW-Migration, 01.09.2006: Zusammenführung des Parameters AliveSpeed [1] mit dem Signal Alive_Geschwindigkeit_Fahrzeug [1].
          signal CRC_V_VEH: start 0, 8 bit, little-endian, base-type=uint8, compu-method=CRC_V_VEH, data-constr=CRC_V_VEH, to EPS  # CRC_Geschwindigkeit_Fahrzeug / CRC_speed_vehicle | LogicalInterface:BMW.POWERTRAIN.SpeedAccelerationDistance[external]@Fahren; Standardabsicherung Applikations-CRC Dieses Signal verwendet die Applikations-CRC-ID = 12 (Dez) Die Checksumme hat keine Ungültigkeitskennung! ACHTUNG: Im Problemfall befüllen Gateways trotzdem immer mit "ungültig" (hier: 0xFF). Transp.MOST-GW-Migration, 01.09.2006: Zusammenführung des Parameters ChecksumSpeedCRC [1] mit dem Signal CRC_Geschwindigkeit_Fahrzeug [2].
          signal DVCO_VEH: start 36, 3 bit, little-endian, base-type=uint8, invalid-value=value_7Dot0:7, compu-method=DVCO_VEH, to EPS  # Fahrzustand_Fahrzeug / driving-condition_vehicle | LogicalInterface:BMW.POWERTRAIN.SpeedAccelerationDistance[external]@Fahren; Alter Name: Status_Fahrzeug_Fahrzustand. (in L6 immer Sensoren mit Richtungserkennung). Dieses Signal zeigt die Fahrzeugbewegungsrichtung und einen Fahrzeugstillstand an. Fahrzeugstillstand ist gegeben, wenn die ermittelte Fahrzeuggeschwindigkeit kleiner als 0,01 m/s ist. Wenn alle Räder stabil und die Raddrehrichtungen bekannt sind, wird die Fahrtrichtung aus den Raddrehrichtungen bestimmt. Bei instabilen/schlupfbehafteten Rädern oder unbekannten Raddrehrichtungen wird die Fahrtrichtung aus einem Modell aus Längsbeschleunigung und Fahrbahnsteigung bestimmt. In SP2011 und SP2009 (außer PL6) Basisfahrzeugen werden aus Kostengründen Raddrehzahlfühler ohne Drehrichtungserkennung verbaut. Die Fahrtrichtung wird modelbasiert berechnet. Deshalb kann es eine unbestimmte Zeit dauern bis zur Erkennung der Fahrtrichtung (Worst Case erst ab 60km/h) Für bestimmte Sonderaustattungen werden Raddrehzahlfühler mit Drehrichtungserkennung verbaut. In SP2009 und SP2011 gilt für den Rollenbetrieb: Bei Zustand "Fahrzeug steht, Fahrzeug auf Ein-Achs-Rollenprüfstand erkannt" gibt das Signal Geschwindigkeit_Fahrzeug_Schwerpunkt nicht die Rollengeschwindigkeit wieder, sondern kann - bis auf Ausnahme von fremdgetriebenen Rollen mit Geschwindigkeiten bis zu 10km/h (hier wird nie eine Geschwindigkeit größer 10 km/h ausgegeben) - beliebige Werte annehmen. Der Qualifier der Fahrzeuggeschwindigkeit (QU_V_VEH_COG) kann je nach Zustand der Qualifier der Raddrehzahlen (QU_AVL_RPM_WHL_xx) auf den Zustand 1011b (Signalqualität bzw. Überwachung eingeschränkt, Zustand/Status temporär) wechseln. Bedingungen für eine erkannte (Einachs)-Rolle sind (UND-Verknüpfung): - größte Geschwindigkeit an nicht angetriebener Achse sehr klein - kleinste Geschwindigkeit an angetriebener Achse größer Schwelle - Differenzgeschwindigkeit der Räder an der angetriebenen Achse klein - Gierrate klein - Mind. eine Vorderrad- und beide Hinterraddrehzahlen gültig Treffen alle diese Bedingungen durchgehend zu, wird nach einer Zeitdauer von 3,5s im Fahrzustand die erkannte Rolle angezeigt. Bedingungen für das Rücksetzen der Rollenerkennung sind (ODER-Verknüpfung): - grösste Vorderradgeschwindigkeit größer Schwelle - Differenzgeschwindigkeit Hinterräder größer Schwelle - Gierrate grösser Schwelle - Beide Vorderrad- oder eine Hinterraddrehzahl ungültig (1 Zyklus entprellt) Achtung: Die automatische Rollenerkennung ist derzeit nur für Ein-Achs-Rollen möglich. Der Zustand "Fahrzeug steht, Zwei-Achs-Rollenbetrieb" kann im Klemmenzustand KL_30B_EIN aktiv vom Fahrer durch eine entsprechende Tastenkombination im Innenraum gesetzt werden. Dieser Zustand soll den Empfängern des Signals ein energetisch korrektes Verhalten auf der Zwei-Achs-Rolle ermöglichen, z.B. Diagnose Job "Rekuperation bei DSC_OFF" im DSC. Während dieses Zustands gibt das Signal Geschwindigkeit_Fahrzeug_Schwerpunkt nicht die Schwerpunktgeschwindigkeit des Fahrzeugs wieder, sondern es wird (im Gegensatz zur Ein-Achs-Rolle) eine Ersatzgeschwindigkeit aus den gemittelten Hinterachsraddrehzahlen ermittelt, die der Rollengeschwindigkeit entspricht. Der Qualifier QU_V_VEH_COG wird im fehlerfreien Fall auf "0001, Signalwert ist gültig und abgesichert und plausibilisiert" gesetzt. Der Zustand "Fahrzeug steht, Zwei-Achs-Rollenbetrieb" wird zurückgesetzt entweder wenn ein Klemmenwechsel von KL_15N_ein auf KL_15N_aus erfolgt oder wenn eine der folgenden Bedingungen erfüllt ist: - Lenkwinkel überschreitet eine Differenz von 20° (bezogen auf Lenkwinkel bei Setzen des Rollenmodus) - Geschwindigkeit berechnet aus Längsbeschleunigung größer 20 km/h - Gierwinkel größer 3° Ab SP2013 gilt für den Rollenbetrieb: Bei Zustand "Fahrzeug steht, Hinterachse auf Rollenprüfstand erkannt" und "Fahrzeug steht, Vorderachse auf Rollenprüfstand erkannt" gibt das Signal Geschwindigkeit_Fahrzeug_Schwerpunkt die Hinterachs- bzw. Vorderachsgeschwindigkeit und damit die Rollengeschwindigkeit aus. Die Hinterachsgeschwindigkeit wird ebenfalls bei "Fahrzeug steht, Zwei-Achs-Rollenbetrieb gesetzt" ausgegeben. Der Qualifier der Fahrzeuggeschwindigkeit (QU_V_VEH_COG) kann je nach Zustand der Qualifier der Raddrehzahlen (QU_AVL_RPM_WHL_xx) auf den Zustand 1011b (Signalqualität bzw. Überwachung eingeschränkt, Zustand/Status temporär) wechseln. Bedingungen für das Setzen des Rollenbetriebs: - Der Rollenbetrieb muss über eine Kombiroutine initialisiert werden. - Danach ist zunächst die 2-Achsrolle (DVCO_VEH=5) gesetzt. - Steht das Fahrzeug auf einer 1-Achs-Rolle erfolgt die Erkennung automatisch und DVCO_VEH nimmt den entsprechenden Zustand ein. Bedingungen für das Rücksetzen der Rollenerkennung sind (ODER-Verknüpfung): - nicht angetriebene Achsgeschwindigkeit größer Schwelle - Differenzgeschwindigkeit angetriebener Achse größer Schwelle - Gierwinkel grösser Schwelle - ungültige Raddrehzahlen - KL_15N_ein auf KL_15N_aus erfolgt - Lenkwinkel grösser Schwelle - Geschwindigkeit berechnet aus Längsbeschleunigung grösser Schwelle Dieses Signal soll langfristig entfallen und durch die zwei Signale Fahrtrichtung_Fahrzeug_Bestätigt und Status_Rollenmodus ersetzt werden: 1. Komponenten, die nur in 35up und folgenden Baureihen verbaut werden, sollen als Empfänger der neuen Signale Fahrtrichtung_Fahrzeug_Bestätigt und Status_Rollenmodus angetragen werden 2. Komponenten, die in der 35up und rückverbaut werden, sollen weiterhin als Empfänger des alten Signals Fahrzustand_Fahrzeug angetragen werden; zusätzlich können die neuen Signale Fahrtrichtung_Fahrzeug_Bestätigt und Status_Rollenmodus empfangen werden. 3. Bestandskomponenten werden mit dem alten Signal beliefert solange sie verbaut werden. 4. Nach Auslauf der letzten Bestandskomponenten soll das Signals Fahrzustand_Fahrzeug entfallen 5. Wird eine Komponente aus anderen Gründen geändert, wird empfohlen auf die neuen Signale umzustellen mit dem Ziel eines früheren Entfalls des Signals Fahrzustand_Fahrzeug
          signal QU_V_VEH_COG: start 32, 4 bit, little-endian, base-type=uint8, invalid-value=value_15Dot0:15, compu-method=QU_V_VEH_COG, to EPS  # Qualifier_Geschwindigkeit_Fahrzeug_Schwerpunkt / Qualifier_speed_vehicle_centre-of-gravity | LogicalInterface:BMW.POWERTRAIN.SpeedAccelerationDistance[external]@Fahren; Status Qualifier zum Signal Geschwindigkeit_Fahrzeug_Schwerpunkt. Mindestanforderungen um einen gültigen Signalwert senden zu können (Stand 10.06.08 gilt für L6/L7/F25): - Klemme 30B + mind. drei Ist_Drehzahl_Rad_xx gültig + Lenkwinkel_Vorderachse_effektiv gültig (im F25/L7 erst ab Kl.15N) "Ursprünglich wurden alle reservierten Zustände des Qualifier definiert (nach dem Qualifier-Standard). Beim Kombi wurden diese Zustände dementsprechend in der Software berücksichtigt. Die jetzt mit "reserviert" gekennzeichneten Zustände wurden aber seitens Sender nie befüllt. Das Kombi wertet die mit "reserviert" gekennzeichneten Zustände wie ursprünglich definiert weiterhin aus."
          signal ST_V_VEH_NSS: start 12, 4 bit, little-endian, base-type=uint8, invalid-value=value_15Dot0:15, compu-method=ST_V_VEH_NSS, to EPS  # Status_Geschwindigkeit_Fahrzeug_Stillstandsnah / status_speed_vehicle_near-standstill | LogicalInterface:BMW.POWERTRAIN.SpeedAccelerationDistance[external]@Fahren; Dieses Signal zeigt an, ob sich das Fahrzeug im stillstandsnahen Bereich (kleiner 10 km/h) befindet. Dazu müssen alle vier Drehzahlfühler (AVL_RPM_WHL_xxH) und die Referenzgeschwindigkeit V_VEH_COG einen Geschwindigkeitswert kleiner 10 km/h aufweisen.
          signal V_VEH_COG: start 16, 16 bit, little-endian, base-type=uint16, invalid-value=value_65535Dot0:65535, compu-method=V_VEH_COG, data-constr=V_VEH_COG, to EPS  # Geschwindigkeit_Fahrzeug_Schwerpunkt / speed_vehicle_centre-of-gravity | LogicalInterface:BMW.POWERTRAIN.SpeedAccelerationDistance[external]@Fahren; Absolutgeschwindigkeit des Fahrzeugschwerpunktes, enthält die Anteile aus Fahrzeuglängs- und Quergeschwindigkeit. Dieses Signal beruht im Wesentlichen auf den vier Raddrehzahlen. Dazu erfolgt die Berechnung und Plausibilisierung der Schwerpunktsgeschwindigkeit. In Fällen, in denen die Raddrehzahlen nur eine ungenaue Aussage über die Fzg.-Geschwindigkeit liefern (großer Schlupf an vier Rädern), erfolgt eine Stützung des Signals über Modellgrößen und weitere Sensorik (z. Bsp. Längsbeschleunigungssensor). Die Geschwindigkeit kann nur positive Werte annehmen, die Fahrtrichtung wird durch das Signal "Fahrzustand_Fahrzeug" angezeigt. Bei Ausfall von einem bis drei Raddrehzahlsensoren erfolgt die Berechnung über die restlichen verfügbaren Sensoren. Die schlechtere Signalqualität wird durch den Qualifier "Wert nicht vertrauenswürdig" gekennzeichnet. Bei Ausfall aller vier Raddrehzahlsensoren kann kein auf einem Modell oder zusätzlicher Sensorik beruhender Ersatzwert ausgegeben werden, daher wird in diesem Fall der Wert Null ausgegeben und der Qualifier auf "Signalwert ist ungültig" gesetzt. Transp.MOST-GW-Migration, 01.09.2006: Zusammenführung des Parameters CarSpeedExt [1] mit dem Signal Geschwindigkeit_Fahrzeug_Schwerpunkt [2].
          signal V_VEH_dummy_39_39: start 39, 1 bit, little-endian, init-value=1, base-type=uint8, compu-method=UINT1, data-constr=UINT1, to EPS
          mapping sigGroup_V_VEH: i-signal-group=sigGroup_V_VEH
      frame DT_DRDYSEN_EXT_VYAW_VEH: to EPS, category=APPLICATION, frame-length=14, flexray-absolutely-scheduled-timing{communication-cycle=cycle-repetition={base-cycle=0, cycle-repetition=CYCLE-REPETITION-2}, slot-id=56}, allow-dynamic-l-sdu-length=false, payload-preamble-indicator=false  # Daten Fahrdynamiksensor Erweitert / Giergeschwindigkeit Fahrzeug
        carries pdu VYAW_VEH: packing-byte-order=little-endian, start-position=64
        pdu VYAW_VEH: length=6, transmission-mode-true-timing=cyclic-timing=time-period=0.01, unused-bit-pattern=255  # Giergeschwindigkeit Fahrzeug | Gemessene und plausibilisierte Giergeschwindigkeit des Fahrzeugs. Diese Nachricht wird nicht im EntryHU Gateway der PL7 geroutet.
          signal ALIV_VYAW_VEH: start 8, 4 bit, little-endian, base-type=uint8, invalid-value=value_15Dot0:15, compu-method=ALIV_COU_4, to EPS  # Alive_Giergeschwindigkeit_Fahrzeug / alive_yaw-velocity_vehicle | LogicalInterface:BMW.POWERTRAIN.SpeedAccelerationDistance[external]@Fahren;
          signal CRC_VYAW_VEH: start 0, 8 bit, little-endian, base-type=uint8, compu-method=CRC8, data-constr=CRC8, to EPS  # CRC_Giergeschwindigkeit_Fahrzeug / CRC_yaw-velocity_vehicle | LogicalInterface:BMW.POWERTRAIN.SpeedAccelerationDistance[external]@Fahren; Standardabsicherung Applikations-CRC Dieses Signal verwendet die Applikations-CRC-ID = 14 (Dez)
          signal QU_VYAW_VEH: start 44, 4 bit, little-endian, base-type=uint8, invalid-value=value_15Dot0:15, compu-method=QU_VYAW_VEH, to EPS  # Qualifier_Giergeschwindigkeit_Fahrzeug / Qualifier_yaw-velocity_vehicle | LogicalInterface:BMW.POWERTRAIN.SpeedAccelerationDistance[external]@Fahren; Erweiterter Status Qualifier zum Signal Giergeschwindigkeit_Fahrzeug. Mindestanforderungen um einen gültigen Signalwert senden zu können (Stand 10.06.08 gilt für L6/L7/F25): - Klemme 30B + Geschwindigkeit_Fahrzeug_Schwerpunkt gültig + Lenkwinkel_Vorderachse_effektiv gültig alternative Aufstartbedingung: - Bei Erkennung eines Modellfehlers wird bei Kl.15 Änderung ein Reset durchgeführt. Frühestens 50ms später kann ein gültiger Wert kommen. In dieser Zeit wird der Qualifier auf Initialisierung gesetzt. Ab der F010-10-01-350 gibt es baureihenübergreifend folgende Spezifikationsänderung: Wenn der Gierratensensor im Anschlag ist (z. Bsp. bei der Rückwärtsschleuderwende), wird nicht wie bisher auf VYAW_VEH ein Ersatzwert und im Qualifier die Codierung 12 (dec) gesendet, sondern es wird der begrenzte Wert ausgegeben und der Qualifier bleibt auf gültig.
          signal VYAW_VEH: start 16, 16 bit, little-endian, base-type=uint16, invalid-value=value_65535Dot0:65535, compu-method=VYAW_VEH, data-constr=VYAW_VEH, to EPS  # Giergeschwindigkeit_Fahrzeug / yaw-velocity_vehicle | LogicalInterface:BMW.POWERTRAIN.SpeedAccelerationDistance[external]@Fahren; Giergeschwindigkeit des Fahrzeugs. Richtung nach ISO 8855 (positiver Winkel entspricht Drehung gegen den Uhrzeigersinn). Die Giergeschwindigkeit des Fahrzeuges wird je nach Fahrzeugkonfiguration von einem oder zwei Gierratensensoren gemessen. Es erfolgt eine Plausibilisierung (durch Modellüberwachung, Gradientenüberwachung und Redundanzüberwachung bei zwei Sensoren) und ein Langzeitabgleich der Offset-Drifts. Sind zwei Gierratensensoren verbaut, so wird der Mittelwert der abgeglichenen Signale als Gierratennutzsignal ausgegeben. Ist einer von zwei Gierratensensoren als fehlerhaft erkannt, so wird der Wert des verbleibenden Sensors als Nutzsignal ausgegeben. Im Qualifier erfolgt die Rückstufung des Signals von "gültig + abgesichert" auf "gültig". Die Einstufung "gültig" gilt entsprechend auch dann, wenn nur ein Gierratensensor verbaut und fehlerfrei ist. Sind alle im Fzg. verbauten Gierratensensoren als fehlerhaft erkannt, so wird ein Ersatzwert aus den verbleibenden Sensoren im Fzg. (Raddrehzahlen, Lenkwinkel, Querbeschleunigung) berechnet und ausgegeben. Entsprechend erfolgt die Kennzeichnung "Ersatzwert" durch den Qualifier. Transp.MOST-GW-Migration, 01.09.2006: Zusammenführung des Parameters YawVelocityVehicle [1] mit dem Signal Giergeschwindigkeit_Fahrzeug [3].
          signal VYAW_VEH_ERR_AMP: start 32, 12 bit, little-endian, base-type=uint16, invalid-value=value_4095Dot0:4095, compu-method=VYAW_VEH_ERR_AMP, data-constr=VYAW_VEH_ERR_AMP, to EPS  # Giergeschwindigkeit_Fahrzeug_Fehler_Amplitude / yaw-velocity_vehicle_error_amplitude | LogicalInterface:BMW.POWERTRAIN.SpeedAccelerationDistance[external]@Fahren; Für den Fall, dass ein Sensorfehler nicht oder noch nicht erkannt wurde, interne Überwachungsmaßnahmen jedoch anzeigen, dass eine Abweichung des Sensorsignals vom tatsächlichen Wert vorliegen könnte, gibt dieser Wert an, wie groß diese Abweichung maximal sein kann. Es wird der Betrag der Fehleramplitude ausgegeben, die Abweichung des tatsächlichen Signals vom ausgegebenen Signal liegt in einem Band mit der doppelten Breite der Fehleramplitude (Signal plus oder minus Fehleramplitude). Der Qualifier des Nutzsignals behält in diesem Fall seinen bisherigen Wert. Beispiel: zwei nicht als fehlerhaft erkannte Gierratensensoren liefern die Werte 10°/s und 20°/s. Das ausgegebene Nutzsignal hat in diesem Fall einen Wert von 15°/s, die Fehleramplitude einen Wert von 5°/s.
          signal VYAW_VEH_dummy_12_15: start 12, 4 bit, little-endian, init-value=15, base-type=uint8, compu-method=UINT4, data-constr=UINT4, to EPS
          mapping sigGroup_VYAW_VEH: i-signal-group=sigGroup_VYAW_VEH
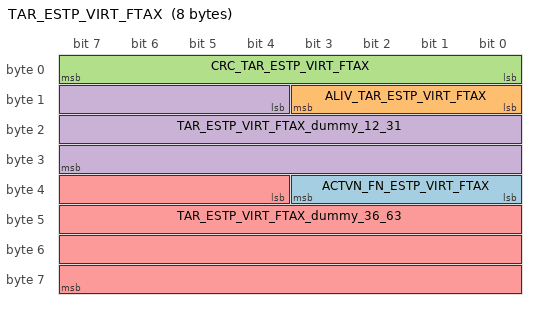
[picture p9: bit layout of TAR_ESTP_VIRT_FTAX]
      frame TAR_ESTP_VIRT_FTAX: to EPS, category=APPLICATION, frame-length=8, flexray-absolutely-scheduled-timing{communication-cycle=cycle-repetition={base-cycle=1, cycle-repetition=CYCLE-REPETITION-2}, slot-id=65}, allow-dynamic-l-sdu-length=false, payload-preamble-indicator=false  # Soll Endanschlag Virtuell Vorderachse
        pdu TAR_ESTP_VIRT_FTAX: length=8, transmission-mode-true-timing=cyclic-timing=time-period=0.01, unused-bit-pattern=255  # Soll Endanschlag Virtuell Vorderachse
          signal ACTVN_FN_ESTP_VIRT_FTAX: start 32, 4 bit, little-endian, base-type=uint8, invalid-value=value_15Dot0:15, compu-method=ACTVN_FN_ESTP_VIRT_FTAX, to EPS  # Aktivierung_Funktion_Endanschlag_Virtuell_Vorderachse / activation_function_end-stop_virtual_front-axle | LogicalInterface:BMW.CHASSIS.STEERING.SteeringAngle[internal]@Fahren; Dieses Signal gibt an, ob der virtuelle Endanschlag der EPS aktiviert bzw. deaktiviert werden soll.
          signal ALIV_TAR_ESTP_VIRT_FTAX: start 8, 4 bit, little-endian, base-type=uint8, invalid-value=value_15Dot0:15, compu-method=ALIV_4_BIT_Unsigned_Integer, data-constr=ALIV_4_BIT_Unsigned_Integer, to EPS  # Alive_Soll_Endanschlag_Virtuell_Vorderachse / alive_target_end-stop_virtual_front-axle | LogicalInterface:BMW.CHASSIS.STEERING.SteeringAngle[internal]@Fahren; Standardabsicherung Alivezähler laut Definition per Lastenheft Allgemeine Bordnetzkommunikation Dieses Signal soll nur überwacht werden, wenn Aktivlenkung und ein Lenksäulensteller verbaut sind.
          signal CRC_TAR_ESTP_VIRT_FTAX: start 0, 8 bit, little-endian, base-type=uint8, compu-method=CRC8, data-constr=CRC8, to EPS  # CRC_Soll_Endanschlag_Virtuell_Vorderachse / CRC_target_end-stop_virtual_front-axle | LogicalInterface:BMW.CHASSIS.STEERING.SteeringAngle[internal]@Fahren; Dieses Signal verwendet die Applikations-CRC-ID = 52 (Dez) Dieses Signal soll nur überwacht werden, wenn Aktivlenkung und ein Lenksäulensteller verbaut sind.
          signal TAR_ESTP_VIRT_FTAX_dummy_12_31: start 12, 20 bit, little-endian, init-value=1048575, base-type=uint32, compu-method=UINT20, data-constr=UINT20, to EPS
          signal TAR_ESTP_VIRT_FTAX_dummy_36_63: start 36, 28 bit, little-endian, init-value=268435455, base-type=uint32, compu-method=UINT28, data-constr=UINT28, to EPS
          mapping sigGroup_TAR_ESTP_VIRT_FTAX: i-signal-group=sigGroup_TAR_ESTP_VIRT_FTAX
      frame TAR_QTA_STRMOM_DV_TAR_STMOM_DV_ACT: to EPS, category=APPLICATION, frame-length=16, flexray-absolutely-scheduled-timing{communication-cycle=cycle-repetition={base-cycle=0, cycle-repetition=CYCLE-REPETITION-2}, slot-id=68}, allow-dynamic-l-sdu-length=false, payload-preamble-indicator=false  # Soll Anteil Lenkmoment Fahrer / Soll Lenkmoment Fahrer Stellglied / target quota steering-moment driver / Soll Lenkmoment Fahrer Stellglied | Soll-Offset-Handmoment.
        pdu TAR_QTA_STRMOM_DV: length=8, transmission-mode-true-timing=cyclic-timing=time-period=0.01, unused-bit-pattern=255  # Soll Anteil Lenkmoment Fahrer / target quota steering-moment Fahrer | Diese Nachricht wird nur bei Fahrzeugen mit elektrischer Lenkung unterstützt. Soll-Offset-Handmoment
          signal ALIV_TAR_QTA_STMOM_DV: start 8, 4 bit, little-endian, base-type=uint8, invalid-value=value_15Dot0:15, compu-method=ALIV_COU_4, to EPS  # Alive_Soll_Anteil_Lenkmoment_Fahrer / alive_target_quota_steering-moment_driver | LogicalInterface:BMW.CHASSIS.STEERING.SteeringAngle[internal]@Fahren; Standardabsicherung Alivezähler laut Definition per Lastenheft Allgemeine Bordnetzkommunikation.
          signal CRC_TAR_QTA_STMOM_DV: start 0, 8 bit, little-endian, base-type=uint8, compu-method=CRC8, data-constr=CRC8, to EPS  # CRC_Soll_Anteil_Lenkmoment_Fahrer / CRC_target_quota_steering-moment_driver | LogicalInterface:BMW.CHASSIS.STEERING.SteeringAngle[internal]@Fahren; Standardabsicherung Applikations-CRC laut Definition per Lastenheft Allgemeine Bordnetzkommunikation. Dieses Signal verwendet die Applikations-CRC-ID = 109 (Dez)
          signal CTR_DEAC_EPS_FNS: start 60, 4 bit, little-endian, base-type=uint8, invalid-value=value_15Dot0:15, compu-method=CTR_DEAC_EPS_FNS, to EPS  # Steuerung_Deaktivierung_EPS_Funktionen / control_deactivation_EPS_functions | LogicalInterface:BMW.CHASSIS.STEERING.SteeringAngle[internal]@Fahren; Dieses Signal beinhaltet die Information zur Deaktivierung einzelner Funktionen auf der EPS.
          signal FACT_ASS_STMOM_FTAX: start 48, 8 bit, little-endian, base-type=uint8, invalid-value=value_255Dot0:255, compu-method=FACT_ASS_STMOM_FTAX, data-constr=FACT_ASS_STMOM_FTAX, to EPS  # Faktor_Unterstützung_Lenkmoment_Vorderachse / factor_assistance_steering-moment_front-axle | LogicalInterface:BMW.CHASSIS.STEERING.SteeringAngle[internal]@Fahren; Dieser Faktor wird als Multiplikator für den Steuerung der Lenkunterstützungsberechnung benötigt. Vollständige Quantisierung/Offsetsangabe: (PH) = 0.00390625 * (HEX) + 1
          signal FACT_CTRR_STMOM_FTAX: start 32, 8 bit, little-endian, base-type=uint8, invalid-value=value_255Dot0:255, compu-method=FACT_CTRR_STMOM_FTAX, data-constr=FACT_CTRR_STMOM_FTAX, to EPS  # Faktor_Zentrierung_Lenkmoment_Vorderachse / factor_centering_steering-moment_front-axle | LogicalInterface:BMW.CHASSIS.STEERING.SteeringAngle[internal]@Fahren; Dieser Faktor wird als Multiplikator für den Steuerung des Aktiven Rücklaufs benötigt. Vollständige Quantisierung/Offsetsangabe: (PH) = 0.00390625 * (HEX) + 0,0078125
          signal FACT_DMPNG_STMOM_FTAX: start 40, 8 bit, little-endian, base-type=uint8, invalid-value=value_255Dot0:255, compu-method=FACT_CTRR_STMOM_FTAX, data-constr=FACT_CTRR_STMOM_FTAX, to EPS  # Faktor_Dämpfung_Lenkmoment_Vorderachse / factor_damping_steering-moment_front-axle | LogicalInterface:BMW.CHASSIS.STEERING.SteeringAngle[internal]@Fahren; Dieser Faktor wird als Multiplikator für den Steuerung des Aktiven Rücklaufs benötigt. Vollständige Quantisierung/Offsetsangabe: (PH) = 0.00390625 * (HEX) + 0.0078125
          signal QU_TAR_FACT_STMOM_FTAX: start 56, 4 bit, little-endian, base-type=uint8, invalid-value=value_15Dot0:15, compu-method=QU_TAR_FACT_STMOM_FTAX, to EPS  # Qualifier_Soll_Faktor_Lenkmoment_Vorderachse / Qualifier_target_factor_steering-moment_front-axle | LogicalInterface:BMW.CHASSIS.STEERING.SteeringAngle[internal]@Fahren; Sollwertqualifier zu den Signalen Faktor_Unterstützung_Lenkmoment_Vorderachse, Faktor_Dämpfung_Lenkmoment_Vorderachse, Faktor_Zentrierung_Lenkmoment_Vorderachse
          signal QU_TAR_QTA_STMOM_DV: start 28, 4 bit, little-endian, base-type=uint8, invalid-value=value_15Dot0:15, compu-method=QU_TAR_QTA_STMOM_DV, to EPS  # Qualifier_Soll_Anteil_Lenkmoment_Fahrer / Qualifier_target_quota_steering-moment_driver | LogicalInterface:BMW.CHASSIS.STEERING.SteeringAngle[internal]@Fahren; Sollwert-Qualifier zum Signal Soll_Anteil_Lenkmoment_Fahrer
          signal TAR_QTA_STMOM_DV: start 16, 12 bit, little-endian, base-type=uint16, invalid-value=value_4095Dot0:4095, compu-method=STMOM_QTA_DV, data-constr=STMOM_QTA_DV, to EPS  # Soll_Anteil_Lenkmoment_Fahrer / target_quota_steering-moment_driver | LogicalInterface:BMW.CHASSIS.STABILIZATION.VehicleDynamicParameters[internal]@Fahren; Es handelt sich um das Offset-Handmoment des Lenkrades, das im Gegenuhrzeigersinn positiv gezählt wird.
          signal TAR_QTA_STRMOM_DV_dummy_12_15: start 12, 4 bit, little-endian, init-value=15, base-type=uint8, compu-method=UINT4, data-constr=UINT4, to EPS
          mapping sigGroup_TAR_QTA_STRMOM_DV: i-signal-group=sigGroup_TAR_QTA_STRMOM_DV
        carries pdu TAR_STMOM_DV_ACT: packing-byte-order=little-endian, start-position=64
        pdu TAR_STMOM_DV_ACT: length=8, transmission-mode-true-timing=cyclic-timing=time-period=0.01, unused-bit-pattern=255  # Soll Lenkmoment Fahrer Stellglied | Diese Nachricht wird nur bei Fahrzeugen mit elektrischer Lenkung unterstützt. Das angegebene Offsetmoment wird vom ICM_QL Momentkoordinator gesendet und hinter der Reglerschleife aufaddiert, um eine direkte Korrekturmöglichkeit der Stellwerte zu haben.
          signal ALIV_TAR_STMOM_DV_ACT: start 8, 4 bit, little-endian, base-type=uint8, invalid-value=value_15Dot0:15, compu-method=ALIV_COU_4, to EPS  # Alive_Soll_Lenkmoment_Fahrer_Stellglied / alive_target_steering-moment_driver_actuator | LogicalInterface:BMW.CHASSIS.STABILIZATION.VehicleDynamicParameters[internal]@Fahren; Standardabsicherung Alivezähler laut Definition per Lastenheft Allgemeine Bordnetzkommunikation.
          signal CRC_TAR_STMOM_DV_ACT: start 0, 8 bit, little-endian, base-type=uint8, compu-method=CRC8, data-constr=CRC8, to EPS  # CRC_Soll_Lenkmoment_Fahrer_Stellglied / CRC_target_steering-moment_driver_actuator | LogicalInterface:BMW.CHASSIS.STABILIZATION.VehicleDynamicParameters[internal]@Fahren; Standardabsicherung Applikations-CRC laut Definition per Lastenheft Allgemeine Bordnetzkommunikation. Dieses Signal verwendet die Applikations-CRC-ID = 179 (Dez)
          signal FACT_DMPNG_ADDON_STMOM_FTAX: start 56, 8 bit, little-endian, base-type=uint8, invalid-value=value_255Dot0:255, compu-method=FACT_DMPNG_ADDON_STMOM_FTAX, data-constr=FACT_DMPNG_ADDON_STMOM_FTAX, to EPS  # Faktor_Dämpfung_Zusatz_Lenkmoment_Vorderachse / factor_damping_add-on_steering-moment_front-axle | LogicalInterface:BMW.CHASSIS.STABILIZATION.VehicleDynamicParameters[internal]@Fahren; Skalierung der Zusatzdämpfung in der EPS für steife Lenkwinkelregelung in der SWC QdmZff.
          signal QU_TAR_DMPNG_ADDON_STMOM_FTAX: start 52, 4 bit, little-endian, base-type=uint8, invalid-value=value_15Dot0:15, compu-method=QU_TAR_DMPNG_ADDON_STMOM_FTAX, to EPS  # Qualifier_Soll_Dämpfung_Zusatz_Lenkmoment_Vorderachse / Qualifier_target_damping_add-on_steering-moment_front-axle | LogicalInterface:BMW.CHASSIS.STABILIZATION.VehicleDynamicParameters[internal]@Fahren; Sollwertqualifier zum Signal Faktor_Dämpfung_Zusatz_Lenkmoment_Vorderachse
          signal QU_TAR_STMOM_DV_ACT: start 28, 4 bit, little-endian, base-type=uint8, invalid-value=value_15Dot0:15, compu-method=QU_TAR_STMOM_DV_ACT, to EPS  # Qualifier_Soll_Lenkmoment_Fahrer_Stellglied / Qualifier_target_steering-moment_driver_actuator | LogicalInterface:BMW.CHASSIS.STABILIZATION.VehicleDynamicParameters[internal]@Fahren; Sollwertqualifier zum Signal Soll_Lenkmoment_Fahrer_Stellglied
          signal TAR_STMOM_DV_ACT: start 16, 12 bit, little-endian, base-type=uint16, invalid-value=value_4095Dot0:4095, compu-method=TAR_STMOM_DV_ACT, data-constr=TAR_STMOM_DV_ACT, to EPS  # Soll_Lenkmoment_Fahrer_Stellglied / target_steering-moment_driver_actuator | LogicalInterface:BMW.CHASSIS.STABILIZATION.VehicleDynamicParameters[internal]@Fahren; Gestelltes Motormoment für den EPS Aktuator. Offsetmoment (+/-1Nm).
          signal TAR_STMOM_DV_ACT_dummy_12_15: start 12, 4 bit, little-endian, init-value=15, base-type=uint8, compu-method=UINT4, data-constr=UINT4, to EPS
          signal TAR_STMOM_DV_ACT_dummy_32_51: start 32, 20 bit, little-endian, init-value=1048575, base-type=uint32, compu-method=UINT20, data-constr=UINT20, to EPS
          mapping sigGroup_TAR_STMOM_DV_ACT: i-signal-group=sigGroup_TAR_STMOM_DV_ACT
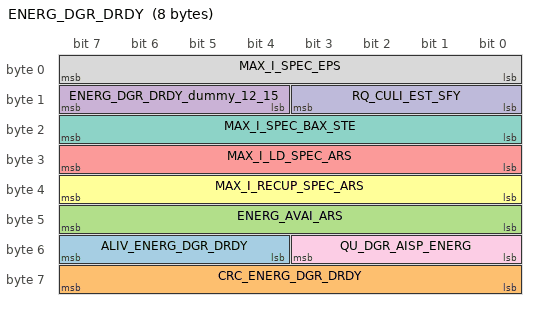
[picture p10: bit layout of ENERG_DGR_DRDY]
      frame ENERG_DGR_DRDY: to EPS, category=APPLICATION, frame-length=8, flexray-absolutely-scheduled-timing{communication-cycle=cycle-repetition={base-cycle=1, cycle-repetition=CYCLE-REPETITION-2}, slot-id=68}, allow-dynamic-l-sdu-length=false, payload-preamble-indicator=false  # Energie Degradation Fahrdynamik
        pdu ENERG_DGR_DRDY: length=8, transmission-mode-true-timing=cyclic-timing=time-period={tolerance=absolute-tolerance=0.002, value=0.01}, unused-bit-pattern=255  # Energie Degradation Fahrdynamik | Energie Degradation fahrdynamischer Regelsysteme: Diese PDU enthält die Max-Strom-Vorgaben für EPS, ASA, HSR, emARS und einen Funktionsqualifier zur Degradation von EHC1/2
          signal ALIV_ENERG_DGR_DRDY: start 52, 4 bit, little-endian, base-type=uint8, invalid-value=value_15Dot0:15, compu-method=ALIV_4_BIT_Unsigned_Integer, data-constr=ALIV_4_BIT_Unsigned_Integer, to EPS  # Alive_Energie_Degradation_Fahrdynamik / alive_Energy_degradation_driving-dynamics | LogicalInterface:BMW.POWERTRAIN.GENERATOR.EnergySupplySafe[internal]@Fahren; Standardabsicherung Alivezähler laut Definition per Lastenheft Allgemeine Bordnetzkommunikation.
          signal CRC_ENERG_DGR_DRDY: start 56, 8 bit, little-endian, base-type=uint8, compu-method=CRC8, data-constr=CRC8, to EPS  # CRC_Energie_Degradation_Fahrdynamik / CRC_Energy_degradation_driving-dynamics | LogicalInterface:BMW.POWERTRAIN.GENERATOR.EnergySupplySafe[internal]@Fahren; Standardabsicherung Applikations-CRC laut Definition per Lastenheft Allgemeine Bordnetzkommunikation. Dieses Signal verwendet die Applikations-CRC-ID = 56 (dez) = 38 (hex). Dieses Signal beinhaltet die CRC-Checksumme für die erweiterte Standardabsicherung mit Applikations-CRC nach Anwendungsprofil 1A E2E-Protection (Autosar SWS 428), mit abweichender Platzierung des CRC in Byte 7 (M10-Verfahren).
          signal ENERG_AVAI_ARS: start 40, 8 bit, little-endian, base-type=uint8, invalid-value=value_255Dot0:255, compu-method=ENERG_AVAI_ARS, data-constr=ENERG_AVAI_ARS, to EPS  # Energie_Verfügbarkeit_ARS / Energy_availibility_ARS | LogicalInterface:BMW.CHASSIS.LOWVOLTAGE.EnergyManagementELMaExt[internal]@Fahren; Es handelt sich um ein qualitatives Signal, das die verfügbare Energie der emARS-Bordnetzerweiterung und daraus resultierend die Degradationsstufe des emARS-Gesamtsystems beschreibt. Defaultwert ist 100%.
          signal ENERG_DGR_DRDY_dummy_12_15: start 12, 4 bit, little-endian, init-value=15, base-type=uint8, compu-method=UINT4, data-constr=UINT4, to EPS
          signal MAX_I_LD_SPEC_ARS: start 24, 8 bit, little-endian, base-type=uint8, invalid-value=value_255Dot0:255, compu-method=I_SPEC_ARS, data-constr=I_SPEC_ARS, to EPS  # Maximal_Strom_Last_Vorgabe_ARS / maximum_current_load_specification_ARS | LogicalInterface:BMW.CHASSIS.LOWVOLTAGE.EnergyManagementELMaExt[internal]@Fahren; Es handel sich um den maximal zulässigen DC-Last-Strom beider emARS-Aktuatoren in Summe. Default-Wert ist 240 A.
          signal MAX_I_RECUP_SPEC_ARS: start 32, 8 bit, little-endian, base-type=uint8, invalid-value=value_255Dot0:255, compu-method=MIN_I_SPEC_ARS, data-constr=MIN_I_SPEC_ARS, to EPS  # Maximal_Strom_Rekuperation_Vorgabe_ARS / maximum_current_recuperation_specification_ARS | LogicalInterface:BMW.CHASSIS.LOWVOLTAGE.EnergyManagementELMaExt[internal]@Fahren; Es handelt sich um den maximal zulässigen DC-REKU-Strom, welchen beide emARS-Aktuatoren ins Energiebordnetz zurückspeisen/ rekuperieren dürfen. Default-Wert ist -240 A.
          signal MAX_I_SPEC_BAX_STE: start 16, 8 bit, little-endian, base-type=uint8, invalid-value=value_255Dot0:255, compu-method=I_SPEC_ARS, data-constr=I_SPEC_ARS, to EPS  # Maximal_Strom_Vorgabe_Hinterachse_Lenkung / maximum_current_specification_back-axle_steering | LogicalInterface:BMW.CHASSIS.LOWVOLTAGE.EnergyManagementELMa[internal]@Fahren; Es handel sich um den maximal zulässigen DC-Last-Strom am Stecker des Lenkungsstellers der Hinterachse (HSR-Steller). Default-Wert ist 70 A.
          signal MAX_I_SPEC_EPS: start 0, 8 bit, little-endian, base-type=uint8, invalid-value=value_255Dot0:255, compu-method=I_SPEC_ARS, data-constr=I_SPEC_ARS, to EPS  # Maximal_Strom_Vorgabe_EPS / maximum_current_specification_EPS | LogicalInterface:BMW.CHASSIS.LOWVOLTAGE.EnergyManagementELMa[internal]@Fahren; Es handel sich um den maximal zulässigen DC-Last-Strom am Stecker der elektrischen Lenkmomentenunterstützung (EPS-Motor). Default-Wert ist 120 A.
          signal QU_DGR_AISP_ENERG: start 48, 4 bit, little-endian, base-type=uint8, invalid-value=value_15Dot0:15, compu-method=QU_DGR_AISP_ENERG, to EPS  # Qualifier_Degradation_Luftfeder_Energie / Qualifier_degradation_air-spring_Energy | LogicalInterface:BMW.CHASSIS.LOWVOLTAGE.EnergyManagementELMa[internal]@Fahren; Es handelt sich um einen Funktionsqualifier, um den Anlauf des Kompressors der Luftfederung bedarfsgerecht zu verzögern oder zu unterbrechen.
          signal RQ_CULI_EST_SFY: start 8, 4 bit, little-endian, base-type=uint8, invalid-value=value_15Dot0:15, compu-method=RQ_CULI_EST_SFY, to EPS  # Anforderung_Strombegrenzung_Elektrische-Lenkung_Sicherheit / request_current-limitation_electrical-steering_safety | LogicalInterface:BMW.POWERTRAIN.GENERATOR.EnergySupplySafe[internal]@Fahren; In diesem Signal wird der Elektrischen Lenkung übermittelt, ob und in welchem Umfang Anforderungen an eine Strombegrenzung der elektrischen Lenkung bestehen.
          mapping sigGroup_ENERG_DGR_DRDY: i-signal-group=sigGroup_ENERG_DGR_DRDY
      frame xcpstatic: from EPS, category=XCP_RUNTIME_CONFIGURED, frame-length=16, flexray-absolutely-scheduled-timing{communication-cycle=cycle-repetition={base-cycle=0, cycle-repetition=CYCLE-REPETITION-1}, slot-id=8}, allow-dynamic-l-sdu-length=false, payload-preamble-indicator=false  # XCP Bereich Statisch / XCP Frame Static | Dieser Frame dient als Platzhalter für die XCP-Konfiguration für FlexRay (s. LH FlexRay) und zur Pufferkonfiguration der FlexRay-Controller. Der statische XCP-Bereich wird auch durch das Projekt "Funktionstrace" mitbenutzt. Ansprechpartner ist Florian Kuttig oder Christian Pigorsch. / Dummyframe für Infrastruktur XCP
        carries pdu dummy16bstatic: packing-byte-order=little-endian, start-position=0
      frame xcpstatic: from EPS, category=XCP_RUNTIME_CONFIGURED, frame-length=16, flexray-absolutely-scheduled-timing{communication-cycle=cycle-repetition={base-cycle=0, cycle-repetition=CYCLE-REPETITION-1}, slot-id=9}, allow-dynamic-l-sdu-length=false, payload-preamble-indicator=false  # XCP Bereich Statisch / XCP Frame Static | Dieser Frame dient als Platzhalter für die XCP-Konfiguration für FlexRay (s. LH FlexRay) und zur Pufferkonfiguration der FlexRay-Controller. Der statische XCP-Bereich wird auch durch das Projekt "Funktionstrace" mitbenutzt. Ansprechpartner ist Florian Kuttig oder Christian Pigorsch. / Dummyframe für Infrastruktur XCP
        carries pdu dummy16bstatic: packing-byte-order=little-endian, start-position=0
      pdu triggering pduTrig_ANFRAGE: pdu=ANFRAGE, from EPS, to EPS
      pdu triggering pduTrig_DBG_EPS_BS_MOD_58_BYTE: pdu=DBG_EPS_BS_MOD_58_BYTE, from EPS
      pdu triggering pduTrig_DBG_EPS_MOD_EXT_120_BYTE: pdu=DBG_EPS_MOD_EXT_120_BYTE, from EPS
      pdu triggering pduTrig_RQ_STG_EFAN: pdu=RQ_STG_EFAN, from EPS
      pdu triggering pduTrig_SECU_CHAL: pdu=SECU_CHAL, from EPS
      pdu triggering pduTrig_SECU_RESP: pdu=SECU_RESP, to EPS
